VERSION ""

NS_ :

BS_:

BU_: Charger BMS

BO_ 2618644212 BMV: 512 BMS
 SG_ SingleBatteryGroup256 : 4092|4@1+ (1,0) [0|15] ""  Charger
 SG_ SingleBatteryVoltage256 : 4080|12@1+ (0.01,0) [0|24] "V"  Charger
 SG_ SingleBatteryGroup255 : 4076|4@1+ (1,0) [0|15] ""  Charger
 SG_ SingleBatteryVoltage255 : 4064|12@1+ (0.01,0) [0|24] "V"  Charger
 SG_ SingleBatteryGroup254 : 4060|4@1+ (1,0) [0|15] ""  Charger
 SG_ SingleBatteryVoltage254 : 4048|12@1+ (0.01,0) [0|24] "V"  Charger
 SG_ SingleBatteryGroup253 : 4044|4@1+ (1,0) [0|15] ""  Charger
 SG_ SingleBatteryVoltage253 : 4032|12@1+ (0.01,0) [0|24] "V"  Charger
 SG_ SingleBatteryGroup252 : 4028|4@1+ (1,0) [0|15] ""  Charger
 SG_ SingleBatteryVoltage252 : 4016|12@1+ (0.01,0) [0|24] "V"  Charger
 SG_ SingleBatteryGroup251 : 4012|4@1+ (1,0) [0|15] ""  Charger
 SG_ SingleBatteryVoltage251 : 4000|12@1+ (0.01,0) [0|24] "V"  Charger
 SG_ SingleBatteryGroup250 : 3996|4@1+ (1,0) [0|15] ""  Charger
 SG_ SingleBatteryVoltage250 : 3984|12@1+ (0.01,0) [0|24] "V"  Charger
 SG_ SingleBatteryGroup249 : 3980|4@1+ (1,0) [0|15] ""  Charger
 SG_ SingleBatteryVoltage249 : 3968|12@1+ (0.01,0) [0|24] "V"  Charger
 SG_ SingleBatteryGroup248 : 3964|4@1+ (1,0) [0|15] ""  Charger
 SG_ SingleBatteryVoltage248 : 3952|12@1+ (0.01,0) [0|24] "V"  Charger
 SG_ SingleBatteryGroup247 : 3948|4@1+ (1,0) [0|15] ""  Charger
 SG_ SingleBatteryVoltage247 : 3936|12@1+ (0.01,0) [0|24] "V"  Charger
 SG_ SingleBatteryGroup246 : 3932|4@1+ (1,0) [0|15] ""  Charger
 SG_ SingleBatteryVoltage246 : 3920|12@1+ (0.01,0) [0|24] "V"  Charger
 SG_ SingleBatteryGroup245 : 3916|4@1+ (1,0) [0|15] ""  Charger
 SG_ SingleBatteryVoltage245 : 3904|12@1+ (0.01,0) [0|24] "V"  Charger
 SG_ SingleBatteryGroup244 : 3900|4@1+ (1,0) [0|15] ""  Charger
 SG_ SingleBatteryVoltage244 : 3888|12@1+ (0.01,0) [0|24] "V"  Charger
 SG_ SingleBatteryGroup243 : 3884|4@1+ (1,0) [0|15] ""  Charger
 SG_ SingleBatteryVoltage243 : 3872|12@1+ (0.01,0) [0|24] "V"  Charger
 SG_ SingleBatteryGroup242 : 3868|4@1+ (1,0) [0|15] ""  Charger
 SG_ SingleBatteryVoltage242 : 3856|12@1+ (0.01,0) [0|24] "V"  Charger
 SG_ SingleBatteryGroup241 : 3852|4@1+ (1,0) [0|15] ""  Charger
 SG_ SingleBatteryVoltage241 : 3840|12@1+ (0.01,0) [0|24] "V"  Charger
 SG_ SingleBatteryGroup240 : 3836|4@1+ (1,0) [0|15] ""  Charger
 SG_ SingleBatteryVoltage240 : 3824|12@1+ (0.01,0) [0|24] "V"  Charger
 SG_ SingleBatteryGroup239 : 3820|4@1+ (1,0) [0|15] ""  Charger
 SG_ SingleBatteryVoltage239 : 3808|12@1+ (0.01,0) [0|24] "V"  Charger
 SG_ SingleBatteryGroup238 : 3804|4@1+ (1,0) [0|15] ""  Charger
 SG_ SingleBatteryVoltage238 : 3792|12@1+ (0.01,0) [0|24] "V"  Charger
 SG_ SingleBatteryGroup237 : 3788|4@1+ (1,0) [0|15] ""  Charger
 SG_ SingleBatteryVoltage237 : 3776|12@1+ (0.01,0) [0|24] "V"  Charger
 SG_ SingleBatteryGroup236 : 3772|4@1+ (1,0) [0|15] ""  Charger
 SG_ SingleBatteryVoltage236 : 3760|12@1+ (0.01,0) [0|24] "V"  Charger
 SG_ SingleBatteryGroup235 : 3756|4@1+ (1,0) [0|15] ""  Charger
 SG_ SingleBatteryVoltage235 : 3744|12@1+ (0.01,0) [0|24] "V"  Charger
 SG_ SingleBatteryGroup234 : 3740|4@1+ (1,0) [0|15] ""  Charger
 SG_ SingleBatteryVoltage234 : 3728|12@1+ (0.01,0) [0|24] "V"  Charger
 SG_ SingleBatteryGroup233 : 3724|4@1+ (1,0) [0|15] ""  Charger
 SG_ SingleBatteryVoltage233 : 3712|12@1+ (0.01,0) [0|24] "V"  Charger
 SG_ SingleBatteryGroup232 : 3708|4@1+ (1,0) [0|15] ""  Charger
 SG_ SingleBatteryVoltage232 : 3696|12@1+ (0.01,0) [0|24] "V"  Charger
 SG_ SingleBatteryGroup231 : 3692|4@1+ (1,0) [0|15] ""  Charger
 SG_ SingleBatteryVoltage231 : 3680|12@1+ (0.01,0) [0|24] "V"  Charger
 SG_ SingleBatteryGroup230 : 3676|4@1+ (1,0) [0|15] ""  Charger
 SG_ SingleBatteryVoltage230 : 3664|12@1+ (0.01,0) [0|24] "V"  Charger
 SG_ SingleBatteryGroup229 : 3660|4@1+ (1,0) [0|15] ""  Charger
 SG_ SingleBatteryVoltage229 : 3648|12@1+ (0.01,0) [0|24] "V"  Charger
 SG_ SingleBatteryGroup228 : 3644|4@1+ (1,0) [0|15] ""  Charger
 SG_ SingleBatteryVoltage228 : 3632|12@1+ (0.01,0) [0|24] "V"  Charger
 SG_ SingleBatteryGroup227 : 3628|4@1+ (1,0) [0|15] ""  Charger
 SG_ SingleBatteryVoltage227 : 3616|12@1+ (0.01,0) [0|24] "V"  Charger
 SG_ SingleBatteryGroup226 : 3612|4@1+ (1,0) [0|15] ""  Charger
 SG_ SingleBatteryVoltage226 : 3600|12@1+ (0.01,0) [0|24] "V"  Charger
 SG_ SingleBatteryGroup225 : 3596|4@1+ (1,0) [0|15] ""  Charger
 SG_ SingleBatteryVoltage225 : 3584|12@1+ (0.01,0) [0|24] "V"  Charger
 SG_ SingleBatteryGroup224 : 3580|4@1+ (1,0) [0|15] ""  Charger
 SG_ SingleBatteryVoltage224 : 3568|12@1+ (0.01,0) [0|24] "V"  Charger
 SG_ SingleBatteryGroup223 : 3564|4@1+ (1,0) [0|15] ""  Charger
 SG_ SingleBatteryVoltage223 : 3552|12@1+ (0.01,0) [0|24] "V"  Charger
 SG_ SingleBatteryGroup222 : 3548|4@1+ (1,0) [0|15] ""  Charger
 SG_ SingleBatteryVoltage222 : 3536|12@1+ (0.01,0) [0|24] "V"  Charger
 SG_ SingleBatteryGroup221 : 3532|4@1+ (1,0) [0|15] ""  Charger
 SG_ SingleBatteryVoltage221 : 3520|12@1+ (0.01,0) [0|24] "V"  Charger
 SG_ SingleBatteryGroup220 : 3516|4@1+ (1,0) [0|15] ""  Charger
 SG_ SingleBatteryVoltage220 : 3504|12@1+ (0.01,0) [0|24] "V"  Charger
 SG_ SingleBatteryGroup219 : 3500|4@1+ (1,0) [0|15] ""  Charger
 SG_ SingleBatteryVoltage219 : 3488|12@1+ (0.01,0) [0|24] "V"  Charger
 SG_ SingleBatteryGroup218 : 3484|4@1+ (1,0) [0|15] ""  Charger
 SG_ SingleBatteryVoltage218 : 3472|12@1+ (0.01,0) [0|24] "V"  Charger
 SG_ SingleBatteryGroup217 : 3468|4@1+ (1,0) [0|15] ""  Charger
 SG_ SingleBatteryVoltage217 : 3456|12@1+ (0.01,0) [0|24] "V"  Charger
 SG_ SingleBatteryGroup216 : 3452|4@1+ (1,0) [0|15] ""  Charger
 SG_ SingleBatteryVoltage216 : 3440|12@1+ (0.01,0) [0|24] "V"  Charger
 SG_ SingleBatteryGroup215 : 3436|4@1+ (1,0) [0|15] ""  Charger
 SG_ SingleBatteryVoltage215 : 3424|12@1+ (0.01,0) [0|24] "V"  Charger
 SG_ SingleBatteryGroup214 : 3420|4@1+ (1,0) [0|15] ""  Charger
 SG_ SingleBatteryVoltage214 : 3408|12@1+ (0.01,0) [0|24] "V"  Charger
 SG_ SingleBatteryGroup213 : 3404|4@1+ (1,0) [0|15] ""  Charger
 SG_ SingleBatteryVoltage213 : 3392|12@1+ (0.01,0) [0|24] "V"  Charger
 SG_ SingleBatteryGroup212 : 3388|4@1+ (1,0) [0|15] ""  Charger
 SG_ SingleBatteryVoltage212 : 3376|12@1+ (0.01,0) [0|24] "V"  Charger
 SG_ SingleBatteryGroup211 : 3372|4@1+ (1,0) [0|15] ""  Charger
 SG_ SingleBatteryVoltage211 : 3360|12@1+ (0.01,0) [0|24] "V"  Charger
 SG_ SingleBatteryGroup210 : 3356|4@1+ (1,0) [0|15] ""  Charger
 SG_ SingleBatteryVoltage210 : 3344|12@1+ (0.01,0) [0|24] "V"  Charger
 SG_ SingleBatteryGroup209 : 3340|4@1+ (1,0) [0|15] ""  Charger
 SG_ SingleBatteryVoltage209 : 3328|12@1+ (0.01,0) [0|24] "V"  Charger
 SG_ SingleBatteryGroup208 : 3324|4@1+ (1,0) [0|15] ""  Charger
 SG_ SingleBatteryVoltage208 : 3312|12@1+ (0.01,0) [0|24] "V"  Charger
 SG_ SingleBatteryGroup207 : 3308|4@1+ (1,0) [0|15] ""  Charger
 SG_ SingleBatteryVoltage207 : 3296|12@1+ (0.01,0) [0|24] "V"  Charger
 SG_ SingleBatteryGroup206 : 3292|4@1+ (1,0) [0|15] ""  Charger
 SG_ SingleBatteryVoltage206 : 3280|12@1+ (0.01,0) [0|24] "V"  Charger
 SG_ SingleBatteryGroup205 : 3276|4@1+ (1,0) [0|15] ""  Charger
 SG_ SingleBatteryVoltage205 : 3264|12@1+ (0.01,0) [0|24] "V"  Charger
 SG_ SingleBatteryGroup204 : 3260|4@1+ (1,0) [0|15] ""  Charger
 SG_ SingleBatteryVoltage204 : 3248|12@1+ (0.01,0) [0|24] "V"  Charger
 SG_ SingleBatteryGroup203 : 3244|4@1+ (1,0) [0|15] ""  Charger
 SG_ SingleBatteryVoltage203 : 3232|12@1+ (0.01,0) [0|24] "V"  Charger
 SG_ SingleBatteryGroup202 : 3228|4@1+ (1,0) [0|15] ""  Charger
 SG_ SingleBatteryVoltage202 : 3216|12@1+ (0.01,0) [0|24] "V"  Charger
 SG_ SingleBatteryGroup201 : 3212|4@1+ (1,0) [0|15] ""  Charger
 SG_ SingleBatteryVoltage201 : 3200|12@1+ (0.01,0) [0|24] "V"  Charger
 SG_ SingleBatteryGroup200 : 3196|4@1+ (1,0) [0|15] ""  Charger
 SG_ SingleBatteryVoltage200 : 3184|12@1+ (0.01,0) [0|24] "V"  Charger
 SG_ SingleBatteryGroup199 : 3180|4@1+ (1,0) [0|15] ""  Charger
 SG_ SingleBatteryVoltage199 : 3168|12@1+ (0.01,0) [0|24] "V"  Charger
 SG_ SingleBatteryGroup198 : 3164|4@1+ (1,0) [0|15] ""  Charger
 SG_ SingleBatteryVoltage198 : 3152|12@1+ (0.01,0) [0|24] "V"  Charger
 SG_ SingleBatteryGroup197 : 3148|4@1+ (1,0) [0|15] ""  Charger
 SG_ SingleBatteryVoltage197 : 3136|12@1+ (0.01,0) [0|24] "V"  Charger
 SG_ SingleBatteryGroup196 : 3132|4@1+ (1,0) [0|15] ""  Charger
 SG_ SingleBatteryVoltage196 : 3120|12@1+ (0.01,0) [0|24] "V"  Charger
 SG_ SingleBatteryGroup195 : 3116|4@1+ (1,0) [0|15] ""  Charger
 SG_ SingleBatteryVoltage195 : 3104|12@1+ (0.01,0) [0|24] "V"  Charger
 SG_ SingleBatteryGroup194 : 3100|4@1+ (1,0) [0|15] ""  Charger
 SG_ SingleBatteryVoltage194 : 3088|12@1+ (0.01,0) [0|24] "V"  Charger
 SG_ SingleBatteryGroup193 : 3084|4@1+ (1,0) [0|15] ""  Charger
 SG_ SingleBatteryVoltage193 : 3072|12@1+ (0.01,0) [0|24] "V"  Charger
 SG_ SingleBatteryGroup192 : 3068|4@1+ (1,0) [0|15] ""  Charger
 SG_ SingleBatteryVoltage192 : 3056|12@1+ (0.01,0) [0|24] "V"  Charger
 SG_ SingleBatteryGroup191 : 3052|4@1+ (1,0) [0|15] ""  Charger
 SG_ SingleBatteryVoltage191 : 3040|12@1+ (0.01,0) [0|24] "V"  Charger
 SG_ SingleBatteryGroup190 : 3036|4@1+ (1,0) [0|15] ""  Charger
 SG_ SingleBatteryVoltage190 : 3024|12@1+ (0.01,0) [0|24] "V"  Charger
 SG_ SingleBatteryGroup189 : 3020|4@1+ (1,0) [0|15] ""  Charger
 SG_ SingleBatteryVoltage189 : 3008|12@1+ (0.01,0) [0|24] "V"  Charger
 SG_ SingleBatteryGroup188 : 3004|4@1+ (1,0) [0|15] ""  Charger
 SG_ SingleBatteryVoltage188 : 2992|12@1+ (0.01,0) [0|24] "V"  Charger
 SG_ SingleBatteryGroup187 : 2988|4@1+ (1,0) [0|15] ""  Charger
 SG_ SingleBatteryVoltage187 : 2976|12@1+ (0.01,0) [0|24] "V"  Charger
 SG_ SingleBatteryGroup186 : 2972|4@1+ (1,0) [0|15] ""  Charger
 SG_ SingleBatteryVoltage186 : 2960|12@1+ (0.01,0) [0|24] "V"  Charger
 SG_ SingleBatteryGroup185 : 2956|4@1+ (1,0) [0|15] ""  Charger
 SG_ SingleBatteryVoltage185 : 2944|12@1+ (0.01,0) [0|24] "V"  Charger
 SG_ SingleBatteryGroup184 : 2940|4@1+ (1,0) [0|15] ""  Charger
 SG_ SingleBatteryVoltage184 : 2928|12@1+ (0.01,0) [0|24] "V"  Charger
 SG_ SingleBatteryGroup183 : 2924|4@1+ (1,0) [0|15] ""  Charger
 SG_ SingleBatteryVoltage183 : 2912|12@1+ (0.01,0) [0|24] "V"  Charger
 SG_ SingleBatteryGroup182 : 2908|4@1+ (1,0) [0|15] ""  Charger
 SG_ SingleBatteryVoltage182 : 2896|12@1+ (0.01,0) [0|24] "V"  Charger
 SG_ SingleBatteryGroup181 : 2892|4@1+ (1,0) [0|15] ""  Charger
 SG_ SingleBatteryVoltage181 : 2880|12@1+ (0.01,0) [0|24] "V"  Charger
 SG_ SingleBatteryGroup180 : 2876|4@1+ (1,0) [0|15] ""  Charger
 SG_ SingleBatteryVoltage180 : 2864|12@1+ (0.01,0) [0|24] "V"  Charger
 SG_ SingleBatteryGroup179 : 2860|4@1+ (1,0) [0|15] ""  Charger
 SG_ SingleBatteryVoltage179 : 2848|12@1+ (0.01,0) [0|24] "V"  Charger
 SG_ SingleBatteryGroup178 : 2844|4@1+ (1,0) [0|15] ""  Charger
 SG_ SingleBatteryVoltage178 : 2832|12@1+ (0.01,0) [0|24] "V"  Charger
 SG_ SingleBatteryGroup177 : 2828|4@1+ (1,0) [0|15] ""  Charger
 SG_ SingleBatteryVoltage177 : 2816|12@1+ (0.01,0) [0|24] "V"  Charger
 SG_ SingleBatteryGroup176 : 2812|4@1+ (1,0) [0|15] ""  Charger
 SG_ SingleBatteryVoltage176 : 2800|12@1+ (0.01,0) [0|24] "V"  Charger
 SG_ SingleBatteryGroup175 : 2796|4@1+ (1,0) [0|15] ""  Charger
 SG_ SingleBatteryVoltage175 : 2784|12@1+ (0.01,0) [0|24] "V"  Charger
 SG_ SingleBatteryGroup174 : 2780|4@1+ (1,0) [0|15] ""  Charger
 SG_ SingleBatteryVoltage174 : 2768|12@1+ (0.01,0) [0|24] "V"  Charger
 SG_ SingleBatteryGroup173 : 2764|4@1+ (1,0) [0|15] ""  Charger
 SG_ SingleBatteryVoltage173 : 2752|12@1+ (0.01,0) [0|24] "V"  Charger
 SG_ SingleBatteryGroup172 : 2748|4@1+ (1,0) [0|15] ""  Charger
 SG_ SingleBatteryVoltage172 : 2736|12@1+ (0.01,0) [0|24] "V"  Charger
 SG_ SingleBatteryGroup171 : 2732|4@1+ (1,0) [0|15] ""  Charger
 SG_ SingleBatteryVoltage171 : 2720|12@1+ (0.01,0) [0|24] "V"  Charger
 SG_ SingleBatteryGroup170 : 2716|4@1+ (1,0) [0|15] ""  Charger
 SG_ SingleBatteryVoltage170 : 2704|12@1+ (0.01,0) [0|24] "V"  Charger
 SG_ SingleBatteryGroup169 : 2700|4@1+ (1,0) [0|15] ""  Charger
 SG_ SingleBatteryVoltage169 : 2688|12@1+ (0.01,0) [0|24] "V"  Charger
 SG_ SingleBatteryGroup168 : 2684|4@1+ (1,0) [0|15] ""  Charger
 SG_ SingleBatteryVoltage168 : 2672|12@1+ (0.01,0) [0|24] "V"  Charger
 SG_ SingleBatteryGroup167 : 2668|4@1+ (1,0) [0|15] ""  Charger
 SG_ SingleBatteryVoltage167 : 2656|12@1+ (0.01,0) [0|24] "V"  Charger
 SG_ SingleBatteryGroup166 : 2652|4@1+ (1,0) [0|15] ""  Charger
 SG_ SingleBatteryVoltage166 : 2640|12@1+ (0.01,0) [0|24] "V"  Charger
 SG_ SingleBatteryGroup165 : 2636|4@1+ (1,0) [0|15] ""  Charger
 SG_ SingleBatteryVoltage165 : 2624|12@1+ (0.01,0) [0|24] "V"  Charger
 SG_ SingleBatteryGroup164 : 2620|4@1+ (1,0) [0|15] ""  Charger
 SG_ SingleBatteryVoltage164 : 2608|12@1+ (0.01,0) [0|24] "V"  Charger
 SG_ SingleBatteryGroup163 : 2604|4@1+ (1,0) [0|15] ""  Charger
 SG_ SingleBatteryVoltage163 : 2592|12@1+ (0.01,0) [0|24] "V"  Charger
 SG_ SingleBatteryGroup162 : 2588|4@1+ (1,0) [0|15] ""  Charger
 SG_ SingleBatteryVoltage162 : 2576|12@1+ (0.01,0) [0|24] "V"  Charger
 SG_ SingleBatteryGroup161 : 2572|4@1+ (1,0) [0|15] ""  Charger
 SG_ SingleBatteryVoltage161 : 2560|12@1+ (0.01,0) [0|24] "V"  Charger
 SG_ SingleBatteryGroup160 : 2556|4@1+ (1,0) [0|15] ""  Charger
 SG_ SingleBatteryVoltage160 : 2544|12@1+ (0.01,0) [0|24] "V"  Charger
 SG_ SingleBatteryGroup159 : 2540|4@1+ (1,0) [0|15] ""  Charger
 SG_ SingleBatteryVoltage159 : 2528|12@1+ (0.01,0) [0|24] "V"  Charger
 SG_ SingleBatteryGroup158 : 2524|4@1+ (1,0) [0|15] ""  Charger
 SG_ SingleBatteryVoltage158 : 2512|12@1+ (0.01,0) [0|24] "V"  Charger
 SG_ SingleBatteryGroup157 : 2508|4@1+ (1,0) [0|15] ""  Charger
 SG_ SingleBatteryVoltage157 : 2496|12@1+ (0.01,0) [0|24] "V"  Charger
 SG_ SingleBatteryGroup156 : 2492|4@1+ (1,0) [0|15] ""  Charger
 SG_ SingleBatteryVoltage156 : 2480|12@1+ (0.01,0) [0|24] "V"  Charger
 SG_ SingleBatteryGroup155 : 2476|4@1+ (1,0) [0|15] ""  Charger
 SG_ SingleBatteryVoltage155 : 2464|12@1+ (0.01,0) [0|24] "V"  Charger
 SG_ SingleBatteryGroup154 : 2460|4@1+ (1,0) [0|15] ""  Charger
 SG_ SingleBatteryVoltage154 : 2448|12@1+ (0.01,0) [0|24] "V"  Charger
 SG_ SingleBatteryGroup153 : 2444|4@1+ (1,0) [0|15] ""  Charger
 SG_ SingleBatteryVoltage153 : 2432|12@1+ (0.01,0) [0|24] "V"  Charger
 SG_ SingleBatteryGroup152 : 2428|4@1+ (1,0) [0|15] ""  Charger
 SG_ SingleBatteryVoltage152 : 2416|12@1+ (0.01,0) [0|24] "V"  Charger
 SG_ SingleBatteryGroup151 : 2412|4@1+ (1,0) [0|15] ""  Charger
 SG_ SingleBatteryVoltage151 : 2400|12@1+ (0.01,0) [0|24] "V"  Charger
 SG_ SingleBatteryGroup150 : 2396|4@1+ (1,0) [0|15] ""  Charger
 SG_ SingleBatteryVoltage150 : 2384|12@1+ (0.01,0) [0|24] "V"  Charger
 SG_ SingleBatteryGroup149 : 2380|4@1+ (1,0) [0|15] ""  Charger
 SG_ SingleBatteryVoltage149 : 2368|12@1+ (0.01,0) [0|24] "V"  Charger
 SG_ SingleBatteryGroup148 : 2364|4@1+ (1,0) [0|15] ""  Charger
 SG_ SingleBatteryVoltage148 : 2352|12@1+ (0.01,0) [0|24] "V"  Charger
 SG_ SingleBatteryGroup147 : 2348|4@1+ (1,0) [0|15] ""  Charger
 SG_ SingleBatteryVoltage147 : 2336|12@1+ (0.01,0) [0|24] "V"  Charger
 SG_ SingleBatteryGroup146 : 2332|4@1+ (1,0) [0|15] ""  Charger
 SG_ SingleBatteryVoltage146 : 2320|12@1+ (0.01,0) [0|24] "V"  Charger
 SG_ SingleBatteryGroup145 : 2316|4@1+ (1,0) [0|15] ""  Charger
 SG_ SingleBatteryVoltage145 : 2304|12@1+ (0.01,0) [0|24] "V"  Charger
 SG_ SingleBatteryGroup144 : 2300|4@1+ (1,0) [0|15] ""  Charger
 SG_ SingleBatteryVoltage144 : 2288|12@1+ (0.01,0) [0|24] "V"  Charger
 SG_ SingleBatteryGroup143 : 2284|4@1+ (1,0) [0|15] ""  Charger
 SG_ SingleBatteryVoltage143 : 2272|12@1+ (0.01,0) [0|24] "V"  Charger
 SG_ SingleBatteryGroup142 : 2268|4@1+ (1,0) [0|15] ""  Charger
 SG_ SingleBatteryVoltage142 : 2256|12@1+ (0.01,0) [0|24] "V"  Charger
 SG_ SingleBatteryGroup141 : 2252|4@1+ (1,0) [0|15] ""  Charger
 SG_ SingleBatteryVoltage141 : 2240|12@1+ (0.01,0) [0|24] "V"  Charger
 SG_ SingleBatteryGroup140 : 2236|4@1+ (1,0) [0|15] ""  Charger
 SG_ SingleBatteryVoltage140 : 2224|12@1+ (0.01,0) [0|24] "V"  Charger
 SG_ SingleBatteryGroup139 : 2220|4@1+ (1,0) [0|15] ""  Charger
 SG_ SingleBatteryVoltage139 : 2208|12@1+ (0.01,0) [0|24] "V"  Charger
 SG_ SingleBatteryGroup138 : 2204|4@1+ (1,0) [0|15] ""  Charger
 SG_ SingleBatteryVoltage138 : 2192|12@1+ (0.01,0) [0|24] "V"  Charger
 SG_ SingleBatteryGroup137 : 2188|4@1+ (1,0) [0|15] ""  Charger
 SG_ SingleBatteryVoltage137 : 2176|12@1+ (0.01,0) [0|24] "V"  Charger
 SG_ SingleBatteryGroup136 : 2172|4@1+ (1,0) [0|15] ""  Charger
 SG_ SingleBatteryVoltage136 : 2160|12@1+ (0.01,0) [0|24] "V"  Charger
 SG_ SingleBatteryGroup135 : 2156|4@1+ (1,0) [0|15] ""  Charger
 SG_ SingleBatteryVoltage135 : 2144|12@1+ (0.01,0) [0|24] "V"  Charger
 SG_ SingleBatteryGroup134 : 2140|4@1+ (1,0) [0|15] ""  Charger
 SG_ SingleBatteryVoltage134 : 2128|12@1+ (0.01,0) [0|24] "V"  Charger
 SG_ SingleBatteryGroup133 : 2124|4@1+ (1,0) [0|15] ""  Charger
 SG_ SingleBatteryVoltage133 : 2112|12@1+ (0.01,0) [0|24] "V"  Charger
 SG_ SingleBatteryGroup132 : 2108|4@1+ (1,0) [0|15] ""  Charger
 SG_ SingleBatteryVoltage132 : 2096|12@1+ (0.01,0) [0|24] "V"  Charger
 SG_ SingleBatteryGroup131 : 2092|4@1+ (1,0) [0|15] ""  Charger
 SG_ SingleBatteryVoltage131 : 2080|12@1+ (0.01,0) [0|24] "V"  Charger
 SG_ SingleBatteryGroup130 : 2076|4@1+ (1,0) [0|15] ""  Charger
 SG_ SingleBatteryVoltage130 : 2064|12@1+ (0.01,0) [0|24] "V"  Charger
 SG_ SingleBatteryGroup129 : 2060|4@1+ (1,0) [0|15] ""  Charger
 SG_ SingleBatteryVoltage129 : 2048|12@1+ (0.01,0) [0|24] "V"  Charger
 SG_ SingleBatteryGroup128 : 2044|4@1+ (1,0) [0|15] ""  Charger
 SG_ SingleBatteryVoltage128 : 2032|12@1+ (0.01,0) [0|24] "V"  Charger
 SG_ SingleBatteryGroup127 : 2028|4@1+ (1,0) [0|15] ""  Charger
 SG_ SingleBatteryVoltage127 : 2016|12@1+ (0.01,0) [0|24] "V"  Charger
 SG_ SingleBatteryGroup126 : 2012|4@1+ (1,0) [0|15] ""  Charger
 SG_ SingleBatteryVoltage126 : 2000|12@1+ (0.01,0) [0|24] "V"  Charger
 SG_ SingleBatteryGroup125 : 1996|4@1+ (1,0) [0|15] ""  Charger
 SG_ SingleBatteryVoltage125 : 1984|12@1+ (0.01,0) [0|24] "V"  Charger
 SG_ SingleBatteryGroup124 : 1980|4@1+ (1,0) [0|15] ""  Charger
 SG_ SingleBatteryVoltage124 : 1968|12@1+ (0.01,0) [0|24] "V"  Charger
 SG_ SingleBatteryGroup123 : 1964|4@1+ (1,0) [0|15] ""  Charger
 SG_ SingleBatteryVoltage123 : 1952|12@1+ (0.01,0) [0|24] "V"  Charger
 SG_ SingleBatteryGroup122 : 1948|4@1+ (1,0) [0|15] ""  Charger
 SG_ SingleBatteryVoltage122 : 1936|12@1+ (0.01,0) [0|24] "V"  Charger
 SG_ SingleBatteryGroup121 : 1932|4@1+ (1,0) [0|15] ""  Charger
 SG_ SingleBatteryVoltage121 : 1920|12@1+ (0.01,0) [0|24] "V"  Charger
 SG_ SingleBatteryGroup120 : 1916|4@1+ (1,0) [0|15] ""  Charger
 SG_ SingleBatteryVoltage120 : 1904|12@1+ (0.01,0) [0|24] "V"  Charger
 SG_ SingleBatteryGroup119 : 1900|4@1+ (1,0) [0|15] ""  Charger
 SG_ SingleBatteryVoltage119 : 1888|12@1+ (0.01,0) [0|24] "V"  Charger
 SG_ SingleBatteryGroup118 : 1884|4@1+ (1,0) [0|15] ""  Charger
 SG_ SingleBatteryVoltage118 : 1872|12@1+ (0.01,0) [0|24] "V"  Charger
 SG_ SingleBatteryGroup117 : 1868|4@1+ (1,0) [0|15] ""  Charger
 SG_ SingleBatteryVoltage117 : 1856|12@1+ (0.01,0) [0|24] "V"  Charger
 SG_ SingleBatteryGroup116 : 1852|4@1+ (1,0) [0|15] ""  Charger
 SG_ SingleBatteryVoltage116 : 1840|12@1+ (0.01,0) [0|24] "V"  Charger
 SG_ SingleBatteryGroup115 : 1836|4@1+ (1,0) [0|15] ""  Charger
 SG_ SingleBatteryVoltage115 : 1824|12@1+ (0.01,0) [0|24] "V"  Charger
 SG_ SingleBatteryGroup114 : 1820|4@1+ (1,0) [0|15] ""  Charger
 SG_ SingleBatteryVoltage114 : 1808|12@1+ (0.01,0) [0|24] "V"  Charger
 SG_ SingleBatteryGroup113 : 1804|4@1+ (1,0) [0|15] ""  Charger
 SG_ SingleBatteryVoltage113 : 1792|12@1+ (0.01,0) [0|24] "V"  Charger
 SG_ SingleBatteryGroup112 : 1788|4@1+ (1,0) [0|15] ""  Charger
 SG_ SingleBatteryVoltage112 : 1776|12@1+ (0.01,0) [0|24] "V"  Charger
 SG_ SingleBatteryGroup111 : 1772|4@1+ (1,0) [0|15] ""  Charger
 SG_ SingleBatteryVoltage111 : 1760|12@1+ (0.01,0) [0|24] "V"  Charger
 SG_ SingleBatteryGroup110 : 1756|4@1+ (1,0) [0|15] ""  Charger
 SG_ SingleBatteryVoltage110 : 1744|12@1+ (0.01,0) [0|24] "V"  Charger
 SG_ SingleBatteryGroup109 : 1740|4@1+ (1,0) [0|15] ""  Charger
 SG_ SingleBatteryVoltage109 : 1728|12@1+ (0.01,0) [0|24] "V"  Charger
 SG_ SingleBatteryGroup108 : 1724|4@1+ (1,0) [0|15] ""  Charger
 SG_ SingleBatteryVoltage108 : 1712|12@1+ (0.01,0) [0|24] "V"  Charger
 SG_ SingleBatteryGroup107 : 1708|4@1+ (1,0) [0|15] ""  Charger
 SG_ SingleBatteryVoltage107 : 1696|12@1+ (0.01,0) [0|24] "V"  Charger
 SG_ SingleBatteryGroup106 : 1692|4@1+ (1,0) [0|15] ""  Charger
 SG_ SingleBatteryVoltage106 : 1680|12@1+ (0.01,0) [0|24] "V"  Charger
 SG_ SingleBatteryGroup105 : 1676|4@1+ (1,0) [0|15] ""  Charger
 SG_ SingleBatteryVoltage105 : 1664|12@1+ (0.01,0) [0|24] "V"  Charger
 SG_ SingleBatteryGroup104 : 1660|4@1+ (1,0) [0|15] ""  Charger
 SG_ SingleBatteryVoltage104 : 1648|12@1+ (0.01,0) [0|24] "V"  Charger
 SG_ SingleBatteryGroup103 : 1644|4@1+ (1,0) [0|15] ""  Charger
 SG_ SingleBatteryVoltage103 : 1632|12@1+ (0.01,0) [0|24] "V"  Charger
 SG_ SingleBatteryGroup102 : 1628|4@1+ (1,0) [0|15] ""  Charger
 SG_ SingleBatteryVoltage102 : 1616|12@1+ (0.01,0) [0|24] "V"  Charger
 SG_ SingleBatteryGroup101 : 1612|4@1+ (1,0) [0|15] ""  Charger
 SG_ SingleBatteryVoltage101 : 1600|12@1+ (0.01,0) [0|24] "V"  Charger
 SG_ SingleBatteryGroup100 : 1596|4@1+ (1,0) [0|15] ""  Charger
 SG_ SingleBatteryVoltage100 : 1584|12@1+ (0.01,0) [0|24] "V"  Charger
 SG_ SingleBatteryGroup099 : 1580|4@1+ (1,0) [0|15] ""  Charger
 SG_ SingleBatteryVoltage099 : 1568|12@1+ (0.01,0) [0|24] "V"  Charger
 SG_ SingleBatteryGroup098 : 1564|4@1+ (1,0) [0|15] ""  Charger
 SG_ SingleBatteryVoltage098 : 1552|12@1+ (0.01,0) [0|24] "V"  Charger
 SG_ SingleBatteryGroup097 : 1548|4@1+ (1,0) [0|15] ""  Charger
 SG_ SingleBatteryVoltage097 : 1536|12@1+ (0.01,0) [0|24] "V"  Charger
 SG_ SingleBatteryGroup096 : 1532|4@1+ (1,0) [0|15] ""  Charger
 SG_ SingleBatteryVoltage096 : 1520|12@1+ (0.01,0) [0|24] "V"  Charger
 SG_ SingleBatteryGroup095 : 1516|4@1+ (1,0) [0|15] ""  Charger
 SG_ SingleBatteryVoltage095 : 1504|12@1+ (0.01,0) [0|24] "V"  Charger
 SG_ SingleBatteryGroup094 : 1500|4@1+ (1,0) [0|15] ""  Charger
 SG_ SingleBatteryVoltage094 : 1488|12@1+ (0.01,0) [0|24] "V"  Charger
 SG_ SingleBatteryGroup093 : 1484|4@1+ (1,0) [0|15] ""  Charger
 SG_ SingleBatteryVoltage093 : 1472|12@1+ (0.01,0) [0|24] "V"  Charger
 SG_ SingleBatteryGroup092 : 1468|4@1+ (1,0) [0|15] ""  Charger
 SG_ SingleBatteryVoltage092 : 1456|12@1+ (0.01,0) [0|24] "V"  Charger
 SG_ SingleBatteryGroup091 : 1452|4@1+ (1,0) [0|15] ""  Charger
 SG_ SingleBatteryVoltage091 : 1440|12@1+ (0.01,0) [0|24] "V"  Charger
 SG_ SingleBatteryGroup090 : 1436|4@1+ (1,0) [0|15] ""  Charger
 SG_ SingleBatteryVoltage090 : 1424|12@1+ (0.01,0) [0|24] "V"  Charger
 SG_ SingleBatteryGroup089 : 1420|4@1+ (1,0) [0|15] ""  Charger
 SG_ SingleBatteryVoltage089 : 1408|12@1+ (0.01,0) [0|24] "V"  Charger
 SG_ SingleBatteryGroup088 : 1404|4@1+ (1,0) [0|15] ""  Charger
 SG_ SingleBatteryVoltage088 : 1392|12@1+ (0.01,0) [0|24] "V"  Charger
 SG_ SingleBatteryGroup087 : 1388|4@1+ (1,0) [0|15] ""  Charger
 SG_ SingleBatteryVoltage087 : 1376|12@1+ (0.01,0) [0|24] "V"  Charger
 SG_ SingleBatteryGroup086 : 1372|4@1+ (1,0) [0|15] ""  Charger
 SG_ SingleBatteryVoltage086 : 1360|12@1+ (0.01,0) [0|24] "V"  Charger
 SG_ SingleBatteryGroup085 : 1356|4@1+ (1,0) [0|15] ""  Charger
 SG_ SingleBatteryVoltage085 : 1344|12@1+ (0.01,0) [0|24] "V"  Charger
 SG_ SingleBatteryGroup084 : 1340|4@1+ (1,0) [0|15] ""  Charger
 SG_ SingleBatteryVoltage084 : 1328|12@1+ (0.01,0) [0|24] "V"  Charger
 SG_ SingleBatteryGroup083 : 1324|4@1+ (1,0) [0|15] ""  Charger
 SG_ SingleBatteryVoltage083 : 1312|12@1+ (0.01,0) [0|24] "V"  Charger
 SG_ SingleBatteryGroup082 : 1308|4@1+ (1,0) [0|15] ""  Charger
 SG_ SingleBatteryVoltage082 : 1296|12@1+ (0.01,0) [0|24] "V"  Charger
 SG_ SingleBatteryGroup081 : 1292|4@1+ (1,0) [0|15] ""  Charger
 SG_ SingleBatteryVoltage081 : 1280|12@1+ (0.01,0) [0|24] "V"  Charger
 SG_ SingleBatteryGroup080 : 1276|4@1+ (1,0) [0|15] ""  Charger
 SG_ SingleBatteryVoltage080 : 1264|12@1+ (0.01,0) [0|24] "V"  Charger
 SG_ SingleBatteryGroup079 : 1260|4@1+ (1,0) [0|15] ""  Charger
 SG_ SingleBatteryVoltage079 : 1248|12@1+ (0.01,0) [0|24] "V"  Charger
 SG_ SingleBatteryGroup078 : 1244|4@1+ (1,0) [0|15] ""  Charger
 SG_ SingleBatteryVoltage078 : 1232|12@1+ (0.01,0) [0|24] "V"  Charger
 SG_ SingleBatteryGroup077 : 1228|4@1+ (1,0) [0|15] ""  Charger
 SG_ SingleBatteryVoltage077 : 1216|12@1+ (0.01,0) [0|24] "V"  Charger
 SG_ SingleBatteryGroup076 : 1212|4@1+ (1,0) [0|15] ""  Charger
 SG_ SingleBatteryVoltage076 : 1200|12@1+ (0.01,0) [0|24] "V"  Charger
 SG_ SingleBatteryGroup075 : 1196|4@1+ (1,0) [0|15] ""  Charger
 SG_ SingleBatteryVoltage075 : 1184|12@1+ (0.01,0) [0|24] "V"  Charger
 SG_ SingleBatteryGroup074 : 1180|4@1+ (1,0) [0|15] ""  Charger
 SG_ SingleBatteryVoltage074 : 1168|12@1+ (0.01,0) [0|24] "V"  Charger
 SG_ SingleBatteryGroup073 : 1164|4@1+ (1,0) [0|15] ""  Charger
 SG_ SingleBatteryVoltage073 : 1152|12@1+ (0.01,0) [0|24] "V"  Charger
 SG_ SingleBatteryGroup072 : 1148|4@1+ (1,0) [0|15] ""  Charger
 SG_ SingleBatteryVoltage072 : 1136|12@1+ (0.01,0) [0|24] "V"  Charger
 SG_ SingleBatteryGroup071 : 1132|4@1+ (1,0) [0|15] ""  Charger
 SG_ SingleBatteryVoltage071 : 1120|12@1+ (0.01,0) [0|24] "V"  Charger
 SG_ SingleBatteryGroup070 : 1116|4@1+ (1,0) [0|15] ""  Charger
 SG_ SingleBatteryVoltage070 : 1104|12@1+ (0.01,0) [0|24] "V"  Charger
 SG_ SingleBatteryGroup069 : 1100|4@1+ (1,0) [0|15] ""  Charger
 SG_ SingleBatteryVoltage069 : 1088|12@1+ (0.01,0) [0|24] "V"  Charger
 SG_ SingleBatteryGroup068 : 1084|4@1+ (1,0) [0|15] ""  Charger
 SG_ SingleBatteryVoltage068 : 1072|12@1+ (0.01,0) [0|24] "V"  Charger
 SG_ SingleBatteryGroup067 : 1068|4@1+ (1,0) [0|15] ""  Charger
 SG_ SingleBatteryVoltage067 : 1056|12@1+ (0.01,0) [0|24] "V"  Charger
 SG_ SingleBatteryGroup066 : 1052|4@1+ (1,0) [0|15] ""  Charger
 SG_ SingleBatteryVoltage066 : 1040|12@1+ (0.01,0) [0|24] "V"  Charger
 SG_ SingleBatteryGroup065 : 1036|4@1+ (1,0) [0|15] ""  Charger
 SG_ SingleBatteryVoltage065 : 1024|12@1+ (0.01,0) [0|24] "V"  Charger
 SG_ SingleBatteryGroup064 : 1020|4@1+ (1,0) [0|15] ""  Charger
 SG_ SingleBatteryVoltage064 : 1008|12@1+ (0.01,0) [0|24] "V"  Charger
 SG_ SingleBatteryGroup063 : 1004|4@1+ (1,0) [0|15] ""  Charger
 SG_ SingleBatteryVoltage063 : 992|12@1+ (0.01,0) [0|24] "V"  Charger
 SG_ SingleBatteryGroup062 : 988|4@1+ (1,0) [0|15] ""  Charger
 SG_ SingleBatteryVoltage062 : 976|12@1+ (0.01,0) [0|24] "V"  Charger
 SG_ SingleBatteryGroup061 : 972|4@1+ (1,0) [0|15] ""  Charger
 SG_ SingleBatteryVoltage061 : 960|12@1+ (0.01,0) [0|24] "V"  Charger
 SG_ SingleBatteryGroup060 : 956|4@1+ (1,0) [0|15] ""  Charger
 SG_ SingleBatteryVoltage060 : 944|12@1+ (0.01,0) [0|24] "V"  Charger
 SG_ SingleBatteryGroup059 : 940|4@1+ (1,0) [0|15] ""  Charger
 SG_ SingleBatteryVoltage059 : 928|12@1+ (0.01,0) [0|24] "V"  Charger
 SG_ SingleBatteryGroup058 : 924|4@1+ (1,0) [0|15] ""  Charger
 SG_ SingleBatteryVoltage058 : 912|12@1+ (0.01,0) [0|24] "V"  Charger
 SG_ SingleBatteryGroup057 : 908|4@1+ (1,0) [0|15] ""  Charger
 SG_ SingleBatteryVoltage057 : 896|12@1+ (0.01,0) [0|24] "V"  Charger
 SG_ SingleBatteryGroup056 : 892|4@1+ (1,0) [0|15] ""  Charger
 SG_ SingleBatteryVoltage056 : 880|12@1+ (0.01,0) [0|24] "V"  Charger
 SG_ SingleBatteryGroup055 : 876|4@1+ (1,0) [0|15] ""  Charger
 SG_ SingleBatteryVoltage055 : 864|12@1+ (0.01,0) [0|24] "V"  Charger
 SG_ SingleBatteryGroup054 : 860|4@1+ (1,0) [0|15] ""  Charger
 SG_ SingleBatteryVoltage054 : 848|12@1+ (0.01,0) [0|24] "V"  Charger
 SG_ SingleBatteryGroup053 : 844|4@1+ (1,0) [0|15] ""  Charger
 SG_ SingleBatteryVoltage053 : 832|12@1+ (0.01,0) [0|24] "V"  Charger
 SG_ SingleBatteryGroup052 : 828|4@1+ (1,0) [0|15] ""  Charger
 SG_ SingleBatteryVoltage052 : 816|12@1+ (0.01,0) [0|24] "V"  Charger
 SG_ SingleBatteryGroup051 : 812|4@1+ (1,0) [0|15] ""  Charger
 SG_ SingleBatteryVoltage051 : 800|12@1+ (0.01,0) [0|24] "V"  Charger
 SG_ SingleBatteryGroup050 : 796|4@1+ (1,0) [0|15] ""  Charger
 SG_ SingleBatteryVoltage050 : 784|12@1+ (0.01,0) [0|24] "V"  Charger
 SG_ SingleBatteryGroup049 : 780|4@1+ (1,0) [0|15] ""  Charger
 SG_ SingleBatteryVoltage049 : 768|12@1+ (0.01,0) [0|24] "V"  Charger
 SG_ SingleBatteryGroup048 : 764|4@1+ (1,0) [0|15] ""  Charger
 SG_ SingleBatteryVoltage048 : 752|12@1+ (0.01,0) [0|24] "V"  Charger
 SG_ SingleBatteryGroup047 : 748|4@1+ (1,0) [0|15] ""  Charger
 SG_ SingleBatteryVoltage047 : 736|12@1+ (0.01,0) [0|24] "V"  Charger
 SG_ SingleBatteryGroup046 : 732|4@1+ (1,0) [0|15] ""  Charger
 SG_ SingleBatteryVoltage046 : 720|12@1+ (0.01,0) [0|24] "V"  Charger
 SG_ SingleBatteryGroup045 : 716|4@1+ (1,0) [0|15] ""  Charger
 SG_ SingleBatteryVoltage045 : 704|12@1+ (0.01,0) [0|24] "V"  Charger
 SG_ SingleBatteryGroup044 : 700|4@1+ (1,0) [0|15] ""  Charger
 SG_ SingleBatteryVoltage044 : 688|12@1+ (0.01,0) [0|24] "V"  Charger
 SG_ SingleBatteryGroup043 : 684|4@1+ (1,0) [0|15] ""  Charger
 SG_ SingleBatteryVoltage043 : 672|12@1+ (0.01,0) [0|24] "V"  Charger
 SG_ SingleBatteryGroup042 : 668|4@1+ (1,0) [0|15] ""  Charger
 SG_ SingleBatteryVoltage042 : 656|12@1+ (0.01,0) [0|24] "V"  Charger
 SG_ SingleBatteryGroup041 : 652|4@1+ (1,0) [0|15] ""  Charger
 SG_ SingleBatteryVoltage041 : 640|12@1+ (0.01,0) [0|24] "V"  Charger
 SG_ SingleBatteryGroup040 : 636|4@1+ (1,0) [0|15] ""  Charger
 SG_ SingleBatteryVoltage040 : 624|12@1+ (0.01,0) [0|24] "V"  Charger
 SG_ SingleBatteryGroup039 : 620|4@1+ (1,0) [0|15] ""  Charger
 SG_ SingleBatteryVoltage039 : 608|12@1+ (0.01,0) [0|24] "V"  Charger
 SG_ SingleBatteryGroup038 : 604|4@1+ (1,0) [0|15] ""  Charger
 SG_ SingleBatteryVoltage038 : 592|12@1+ (0.01,0) [0|24] "V"  Charger
 SG_ SingleBatteryGroup037 : 588|4@1+ (1,0) [0|15] ""  Charger
 SG_ SingleBatteryVoltage037 : 576|12@1+ (0.01,0) [0|24] "V"  Charger
 SG_ SingleBatteryGroup036 : 572|4@1+ (1,0) [0|15] ""  Charger
 SG_ SingleBatteryVoltage036 : 560|12@1+ (0.01,0) [0|24] "V"  Charger
 SG_ SingleBatteryGroup035 : 556|4@1+ (1,0) [0|15] ""  Charger
 SG_ SingleBatteryVoltage035 : 544|12@1+ (0.01,0) [0|24] "V"  Charger
 SG_ SingleBatteryGroup034 : 540|4@1+ (1,0) [0|15] ""  Charger
 SG_ SingleBatteryVoltage034 : 528|12@1+ (0.01,0) [0|24] "V"  Charger
 SG_ SingleBatteryGroup033 : 524|4@1+ (1,0) [0|15] ""  Charger
 SG_ SingleBatteryVoltage033 : 512|12@1+ (0.01,0) [0|24] "V"  Charger
 SG_ SingleBatteryGroup032 : 508|4@1+ (1,0) [0|15] ""  Charger
 SG_ SingleBatteryVoltage032 : 496|12@1+ (0.01,0) [0|24] "V"  Charger
 SG_ SingleBatteryGroup031 : 492|4@1+ (1,0) [0|15] ""  Charger
 SG_ SingleBatteryVoltage031 : 480|12@1+ (0.01,0) [0|24] "V"  Charger
 SG_ SingleBatteryGroup030 : 476|4@1+ (1,0) [0|15] ""  Charger
 SG_ SingleBatteryVoltage030 : 464|12@1+ (0.01,0) [0|24] "V"  Charger
 SG_ SingleBatteryGroup029 : 460|4@1+ (1,0) [0|15] ""  Charger
 SG_ SingleBatteryVoltage029 : 448|12@1+ (0.01,0) [0|24] "V"  Charger
 SG_ SingleBatteryGroup028 : 444|4@1+ (1,0) [0|15] ""  Charger
 SG_ SingleBatteryVoltage028 : 432|12@1+ (0.01,0) [0|24] "V"  Charger
 SG_ SingleBatteryGroup027 : 428|4@1+ (1,0) [0|15] ""  Charger
 SG_ SingleBatteryVoltage027 : 416|12@1+ (0.01,0) [0|24] "V"  Charger
 SG_ SingleBatteryGroup026 : 412|4@1+ (1,0) [0|15] ""  Charger
 SG_ SingleBatteryVoltage026 : 400|12@1+ (0.01,0) [0|24] "V"  Charger
 SG_ SingleBatteryGroup025 : 396|4@1+ (1,0) [0|15] ""  Charger
 SG_ SingleBatteryVoltage025 : 384|12@1+ (0.01,0) [0|24] "V"  Charger
 SG_ SingleBatteryGroup024 : 380|4@1+ (1,0) [0|15] ""  Charger
 SG_ SingleBatteryVoltage024 : 368|12@1+ (0.01,0) [0|24] "V"  Charger
 SG_ SingleBatteryGroup023 : 364|4@1+ (1,0) [0|15] ""  Charger
 SG_ SingleBatteryVoltage023 : 352|12@1+ (0.01,0) [0|24] "V"  Charger
 SG_ SingleBatteryGroup022 : 348|4@1+ (1,0) [0|15] ""  Charger
 SG_ SingleBatteryVoltage022 : 336|12@1+ (0.01,0) [0|24] "V"  Charger
 SG_ SingleBatteryGroup021 : 332|4@1+ (1,0) [0|15] ""  Charger
 SG_ SingleBatteryVoltage021 : 320|12@1+ (0.01,0) [0|24] "V"  Charger
 SG_ SingleBatteryGroup020 : 316|4@1+ (1,0) [0|15] ""  Charger
 SG_ SingleBatteryVoltage020 : 304|12@1+ (0.01,0) [0|24] "V"  Charger
 SG_ SingleBatteryGroup019 : 300|4@1+ (1,0) [0|15] ""  Charger
 SG_ SingleBatteryVoltage019 : 288|12@1+ (0.01,0) [0|24] "V"  Charger
 SG_ SingleBatteryGroup018 : 284|4@1+ (1,0) [0|15] ""  Charger
 SG_ SingleBatteryVoltage018 : 272|12@1+ (0.01,0) [0|24] "V"  Charger
 SG_ SingleBatteryGroup017 : 268|4@1+ (1,0) [0|15] ""  Charger
 SG_ SingleBatteryVoltage017 : 256|12@1+ (0.01,0) [0|24] "V"  Charger
 SG_ SingleBatteryGroup016 : 252|4@1+ (1,0) [0|15] ""  Charger
 SG_ SingleBatteryVoltage016 : 240|12@1+ (0.01,0) [0|24] "V"  Charger
 SG_ SingleBatteryGroup015 : 236|4@1+ (1,0) [0|15] ""  Charger
 SG_ SingleBatteryVoltage015 : 224|12@1+ (0.01,0) [0|24] "V"  Charger
 SG_ SingleBatteryGroup014 : 220|4@1+ (1,0) [0|15] ""  Charger
 SG_ SingleBatteryVoltage014 : 208|12@1+ (0.01,0) [0|24] "V"  Charger
 SG_ SingleBatteryGroup013 : 204|4@1+ (1,0) [0|15] ""  Charger
 SG_ SingleBatteryVoltage013 : 192|12@1+ (0.01,0) [0|24] "V"  Charger
 SG_ SingleBatteryGroup012 : 188|4@1+ (1,0) [0|15] ""  Charger
 SG_ SingleBatteryVoltage012 : 176|12@1+ (0.01,0) [0|24] "V"  Charger
 SG_ SingleBatteryGroup011 : 172|4@1+ (1,0) [0|15] ""  Charger
 SG_ SingleBatteryVoltage011 : 160|12@1+ (0.01,0) [0|24] "V"  Charger
 SG_ SingleBatteryGroup010 : 156|4@1+ (1,0) [0|15] ""  Charger
 SG_ SingleBatteryVoltage010 : 144|12@1+ (0.01,0) [0|24] "V"  Charger
 SG_ SingleBatteryGroup009 : 140|4@1+ (1,0) [0|15] ""  Charger
 SG_ SingleBatteryVoltage009 : 128|12@1+ (0.01,0) [0|24] "V"  Charger
 SG_ SingleBatteryGroup008 : 124|4@1+ (1,0) [0|15] ""  Charger
 SG_ SingleBatteryVoltage008 : 112|12@1+ (0.01,0) [0|24] "V"  Charger
 SG_ SingleBatteryGroup007 : 108|4@1+ (1,0) [0|15] ""  Charger
 SG_ SingleBatteryVoltage007 : 96|12@1+ (0.01,0) [0|24] "V"  Charger
 SG_ SingleBatteryGroup006 : 92|4@1+ (1,0) [0|15] ""  Charger
 SG_ SingleBatteryVoltage006 : 80|12@1+ (0.01,0) [0|24] "V"  Charger
 SG_ SingleBatteryGroup005 : 76|4@1+ (1,0) [0|15] ""  Charger
 SG_ SingleBatteryVoltage005 : 64|12@1+ (0.01,0) [0|24] "V"  Charger
 SG_ SingleBatteryGroup004 : 60|4@1+ (1,0) [0|15] ""  Charger
 SG_ SingleBatteryVoltage004 : 48|12@1+ (0.01,0) [0|24] "V"  Charger
 SG_ SingleBatteryGroup003 : 44|4@1+ (1,0) [0|15] ""  Charger
 SG_ SingleBatteryVoltage003 : 32|12@1+ (0.01,0) [0|24] "V"  Charger
 SG_ SingleBatteryGroup002 : 28|4@1+ (1,0) [0|15] ""  Charger
 SG_ SingleBatteryVoltage002 : 16|12@1+ (0.01,0) [0|24] "V"  Charger
 SG_ SingleBatteryGroup001 : 12|4@1+ (1,0) [0|15] ""  Charger
 SG_ SingleBatteryVoltage001 : 0|12@1+ (0.01,0) [0|24] "V"  Charger

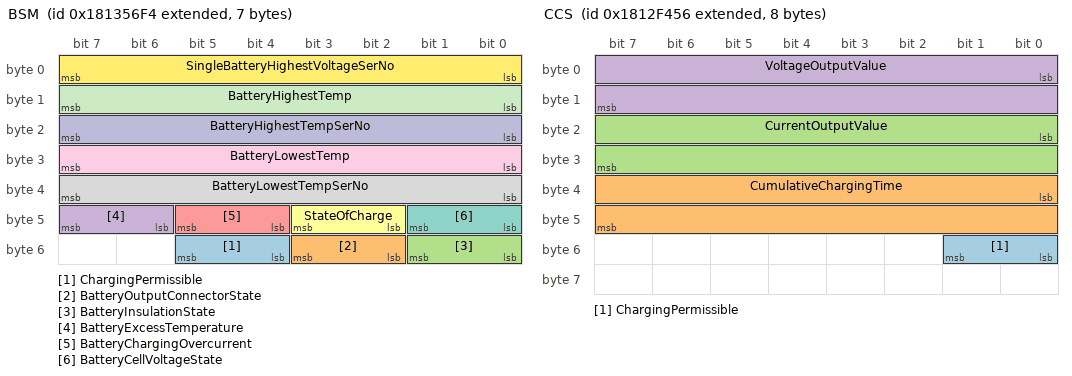
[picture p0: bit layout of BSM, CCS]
BO_ 2551404276 BSM: 7 BMS
 SG_ ChargingPermissible : 52|2@1+ (1,0) [0|3] ""  Charger
 SG_ BatteryOutputConnectorState : 50|2@1+ (1,0) [0|3] ""  Charger
 SG_ BatteryInsulationState : 48|2@1+ (1,0) [0|3] ""  Charger
 SG_ BatteryExcessTemperature : 46|2@1+ (1,0) [0|3] ""  Charger
 SG_ BatteryChargingOvercurrent : 44|2@1+ (1,0) [0|3] ""  Charger
 SG_ StateOfCharge : 42|2@1+ (1,0) [0|3] ""  Charger
 SG_ BatteryCellVoltageState : 40|2@1+ (1,0) [0|3] ""  Charger
 SG_ BatteryLowestTempSerNo : 32|8@1+ (1,1) [1|256] ""  Charger
 SG_ BatteryLowestTemp : 24|8@1+ (1,-50) [-50|200] "°C"  Charger
 SG_ BatteryHighestTempSerNo : 16|8@1+ (1,1) [1|256] ""  Charger
 SG_ BatteryHighestTemp : 8|8@1+ (1,-50) [-50|200] "°C"  Charger
 SG_ SingleBatteryHighestVoltageSerNo : 0|8@1+ (1,1) [1|256] ""  Charger

BO_ 2551379030 CCS: 8 Charger
 SG_ ChargingPermissible : 48|2@1+ (1,0) [0|3] ""  BMS
 SG_ CumulativeChargingTime : 32|16@1+ (1,0) [0|600] "min"  BMS
 SG_ CurrentOutputValue : 16|16@1+ (0.1,-400) [-400|6153.5] "A"  BMS
 SG_ VoltageOutputValue : 0|16@1+ (0.1,0) [0|6553.5] "V"  BMS

BO_ 2618382068 BCS: 9 BMS
 SG_ EstimatedRemainingChargingTime : 56|16@1+ (1,0) [0|600] "min"  Charger
 SG_ CurrentChargeState : 48|8@1+ (1,0) [0|100] "%"  Charger
 SG_ GroupNrOfCellWithHighestVoltage : 44|4@1+ (1,0) [0|15] ""  Charger
 SG_ HighestVoltageOfBatteryCell : 32|12@1+ (0.01,0) [0|24] "V"  Charger
 SG_ MeasuredChargingCurrent : 16|16@1+ (0.1,-400) [-400|6153.5] "A"  Charger
 SG_ MeasuredChargingVoltage : 0|16@1+ (0.1,0) [0|6553.5] "V"  Charger

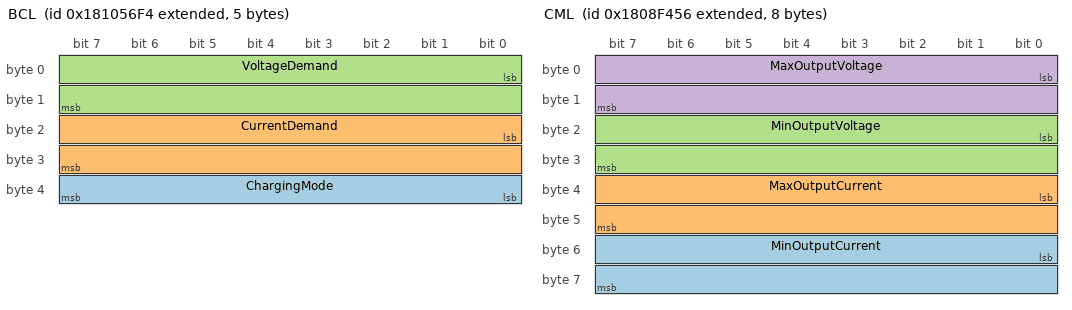
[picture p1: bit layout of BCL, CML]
BO_ 2551207668 BCL: 5 BMS
 SG_ ChargingMode : 32|8@1+ (1,0) [0|0] ""  Charger
 SG_ CurrentDemand : 16|16@1+ (0.1,-400) [-400|6153.5] "A"  Charger
 SG_ VoltageDemand : 0|16@1+ (0.1,0) [0|6553.5] "V"  Charger

BO_ 2416637014 CRO: 1 Charger
 SG_ ChargerReadyForCharging : 0|8@1+ (1,0) [0|255] ""  BMS

BO_ 2416531188 BRO: 1 BMS
 SG_ BmsReadyForCharging : 0|8@1+ (1,0) [0|255] ""  Charger

BO_ 2550723670 CML: 8 Charger
 SG_ MinOutputCurrent : 48|16@1+ (0.1,-400) [-400|6153.5] "A"  BMS
 SG_ MaxOutputCurrent : 32|16@1+ (0.1,-400) [-400|6153.5] "A"  BMS
 SG_ MinOutputVoltage : 16|16@1+ (0.1,0) [0|6553.5] "V"  BMS
 SG_ MaxOutputVoltage : 0|16@1+ (0.1,0) [0|6553.5] "V"  BMS

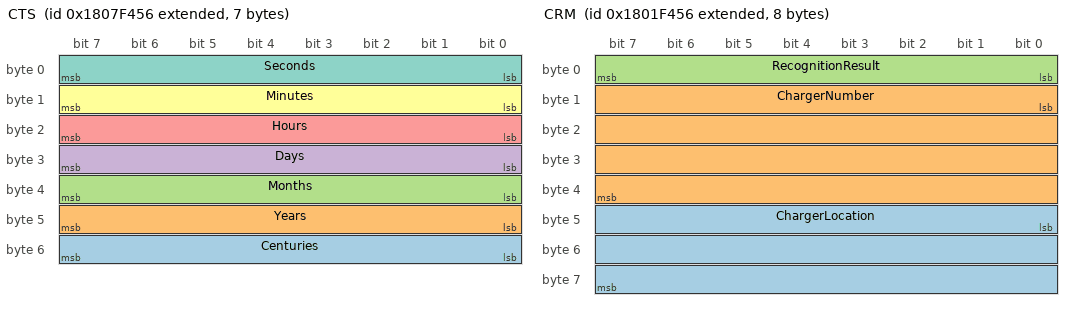
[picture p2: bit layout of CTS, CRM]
BO_ 2550658134 CTS: 7 Charger
 SG_ Centuries : 48|8@1+ (1,0) [0|0] "" Vector__XXX
 SG_ Years : 40|8@1+ (1,0) [0|0] "" Vector__XXX
 SG_ Months : 32|8@1+ (1,0) [0|255] "" Vector__XXX
 SG_ Days : 24|8@1+ (1,0) [0|255] "" Vector__XXX
 SG_ Hours : 16|8@1+ (1,0) [0|0] "" Vector__XXX
 SG_ Minutes : 8|8@1+ (1,0) [0|0] "" Vector__XXX
 SG_ Seconds : 0|8@1+ (1,0) [0|0] "" Vector__XXX

BO_ 2617661172 BCP: 13 BMS
 SG_ CurrentBatteryVoltage : 88|16@1+ (0.1,0) [0|6553.5] "V"  Charger
 SG_ StatusOfCharge : 72|16@1+ (0.1,0) [0|100] "%"  Charger
 SG_ MaxPermTemperature : 64|8@1+ (1,-50) [-50|200] "°C"  Charger
 SG_ TotalMaxPermChargingVoltage : 48|16@1+ (0.1,0) [0|6553.5] "V"  Charger
 SG_ TotalNominalEnergy : 32|16@1+ (0.1,0) [0|1000] "kWh"  Charger
 SG_ MaxPermChargingCurrent : 16|16@1+ (0.1,-400) [-400|6153.5] "A"  Charger
 SG_ MaxBattCellChargingVoltage : 0|16@1+ (0.01,0) [0|24] "V"  Charger

BO_ 2617399028 BRM: 49 BMS
 SG_ BmsSoftwareVersion_Reserved : 368|24@1+ (1,0) [0|16777215] ""  Charger
 SG_ BmsSoftwareVersion_CompileYear : 352|16@1+ (1,0) [0|65534] ""  Charger
 SG_ BmsSoftwareVersion_CompileMonth : 344|8@1+ (1,0) [1|12] ""  Charger
 SG_ BmsSoftwareVersion_CompileDay : 336|8@1+ (1,0) [1|31] ""  Charger
 SG_ BmsSoftwareVersion_Serial : 328|8@1+ (1,0) [1|254] ""  Charger
 SG_ BRM_Reserved1 : 184|8@1+ (1,0) [0|255] ""  Charger
 SG_ VIN : 192|136@1+ (1,0) [0|0] ""  Charger
 SG_ Property : 176|8@1+ (1,0) [0|1] ""  Charger
 SG_ ChargingFrequency : 152|24@1+ (1,0) [0|16777215] ""  Charger
 SG_ ProductionDay : 144|8@1+ (1,0) [0|31] "Days"  Charger
 SG_ ProductionMonth : 136|8@1+ (1,0) [1|12] ""  Charger
 SG_ ProductionYear : 128|8@1+ (1,1985) [1985|2235] "Years"  Charger
 SG_ BatteryPackNumber : 96|32@1+ (1,0) [0|4294967295] ""  Charger
 SG_ ManufacturerName : 64|32@1+ (1,0) [0|4294967295] ""  Charger
 SG_ BatterySystemVoltage : 48|16@1+ (0.1,0) [0|6553.5] "V"  Charger
 SG_ BatterySystemCapacity : 32|16@1+ (0.1,0) [0|6553.5] "Ah"  Charger
 SG_ BmsVersion : 8|16@1+ (1,0) [0|65535] ""  Charger
 SG_ BmsRevision : 0|8@1+ (1,0) [0|255] ""  Charger
 SG_ BatteryType : 24|8@1+ (1,0) [0|255] ""  Charger

BO_ 2550264918 CRM: 8 Charger
 SG_ ChargerLocation : 40|24@1+ (1,0) [0|16777215] ""  BMS
 SG_ ChargerNumber : 8|32@1+ (1,0) [0|4294967295] ""  BMS
 SG_ RecognitionResult : 0|8@1+ (1,0) [0|170] ""  BMS

BO_ 2552714996 BHM: 2 BMS
 SG_ MaxChargingVoltage : 0|16@1+ (0.1,0) [0|6553.5] "V"  Charger

BO_ 2552689750 CHM: 3 Charger
 SG_ MinorChargerVersion : 0|8@1+ (1,0) [0|65535] "" Vector__XXX
 SG_ MajorChargerVersion : 8|16@1+ (1,0) [0|65535] ""  BMS

BO_ 2565603070 TPDT: 8 Vector__XXX
 SG_ SequenceNumber : 0|8@1+ (1,0) [0|255] "" Vector__XXX

BO_ 2565668606 TPCMxx: 8 Vector__XXX
 SG_ TotalNumberOfPacketsEoMA m19 : 24|8@1+ (1,0) [0|255] "" Vector__XXX
 SG_ TotalMessageSizeEoMA m19 : 8|16@1+ (1,0) [0|64255] "" Vector__XXX
 SG_ TotalMessageSizeBAM m32 : 8|16@1+ (1,0) [0|64255] "" Vector__XXX
 SG_ TotalNumberOfPacketsBAM m32 : 24|8@1+ (1,0) [0|255] "" Vector__XXX
 SG_ ConnectionAbortReason m255 : 8|8@1+ (1,0) [0|255] "" Vector__XXX
 SG_ NextPacketNumberToBeSent m17 : 16|8@1+ (1,0) [0|255] "" Vector__XXX
 SG_ NumberOfPacketsThatCanBeSent m17 : 8|8@1+ (1,0) [0|255] "" Vector__XXX
 SG_ PGNumber : 40|24@1+ (1,0) [0|16777200] "" Vector__XXX
 SG_ MaximumNumberOfPackets m16 : 32|8@1+ (1,0) [0|255] "" Vector__XXX
 SG_ TotalNumberOfPackets m16 : 24|8@1+ (1,0) [0|255] "" Vector__XXX
 SG_ TotalMessageSize m16 : 8|16@1+ (1,0) [0|64255] "" Vector__XXX
 SG_ ControlByte M : 0|8@1+ (1,0) [0|255] "" Vector__XXX

BO_ 2565537534 RQST: 3 Vector__XXX
 SG_ ParameterGroupNumber : 0|24@1+ (1,0) [0|16777215] "" Vector__XXX

BO_ 2565406462 ACKM: 8 Vector__XXX
 SG_ AddressBusy m3 : 32|8@1+ (1,0) [0|255] "" Vector__XXX
 SG_ ControlByte M : 0|8@1+ (1,0) [0|255] "" Vector__XXX
 SG_ ParameterGroupNumber : 40|24@1+ (1,0) [0|16777215] "" Vector__XXX
 SG_ GroupFunctionValue : 8|8@1+ (1,0) [0|255] "" Vector__XXX
 SG_ AddressAccessDenied m2 : 32|8@1+ (1,0) [0|255] "" Vector__XXX
 SG_ AddressNegativeAcknowledgement m1 : 32|8@1+ (1,0) [0|255] "" Vector__XXX
 SG_ AddressAcknowledged m0 : 32|8@1+ (1,0) [0|255] "" Vector__XXX

CM_ BO_ 2618644212 "[Charging] Single power storage battery voltage";
CM_ SG_ 2618644212 SingleBatteryGroup256 "#256 single power storage battery voltage

battery grouping No.";
CM_ SG_ 2618644212 SingleBatteryVoltage256 "#256 single power storage battery voltage

single power storage battery voltage";
CM_ SG_ 2618644212 SingleBatteryGroup255 "#255 single power storage battery voltage

battery grouping No.";
CM_ SG_ 2618644212 SingleBatteryVoltage255 "#255 single power storage battery voltage

single power storage battery voltage";
CM_ SG_ 2618644212 SingleBatteryGroup254 "#254 single power storage battery voltage

battery grouping No.";
CM_ SG_ 2618644212 SingleBatteryVoltage254 "#254 single power storage battery voltage

single power storage battery voltage";
CM_ SG_ 2618644212 SingleBatteryGroup253 "#253 single power storage battery voltage

battery grouping No.";
CM_ SG_ 2618644212 SingleBatteryVoltage253 "#253 single power storage battery voltage

single power storage battery voltage";
CM_ SG_ 2618644212 SingleBatteryGroup252 "#252 single power storage battery voltage

battery grouping No.";
CM_ SG_ 2618644212 SingleBatteryVoltage252 "#252 single power storage battery voltage

single power storage battery voltage";
CM_ SG_ 2618644212 SingleBatteryGroup251 "#251 single power storage battery voltage

battery grouping No.";
CM_ SG_ 2618644212 SingleBatteryVoltage251 "#251 single power storage battery voltage

single power storage battery voltage";
CM_ SG_ 2618644212 SingleBatteryGroup250 "#250 single power storage battery voltage

battery grouping No.";
CM_ SG_ 2618644212 SingleBatteryVoltage250 "#250 single power storage battery voltage

single power storage battery voltage";
CM_ SG_ 2618644212 SingleBatteryGroup249 "#249 single power storage battery voltage

battery grouping No.";
CM_ SG_ 2618644212 SingleBatteryVoltage249 "#249 single power storage battery voltage

single power storage battery voltage";
CM_ SG_ 2618644212 SingleBatteryGroup248 "#248 single power storage battery voltage

battery grouping No.";
CM_ SG_ 2618644212 SingleBatteryVoltage248 "#248 single power storage battery voltage

single power storage battery voltage";
CM_ SG_ 2618644212 SingleBatteryGroup247 "#247 single power storage battery voltage

battery grouping No.";
CM_ SG_ 2618644212 SingleBatteryVoltage247 "#247 single power storage battery voltage

single power storage battery voltage";
CM_ SG_ 2618644212 SingleBatteryGroup246 "#246 single power storage battery voltage

battery grouping No.";
CM_ SG_ 2618644212 SingleBatteryVoltage246 "#246 single power storage battery voltage

single power storage battery voltage";
CM_ SG_ 2618644212 SingleBatteryGroup245 "#245 single power storage battery voltage

battery grouping No.";
CM_ SG_ 2618644212 SingleBatteryVoltage245 "#245 single power storage battery voltage

single power storage battery voltage";
CM_ SG_ 2618644212 SingleBatteryGroup244 "#244 single power storage battery voltage

battery grouping No.";
CM_ SG_ 2618644212 SingleBatteryVoltage244 "#244 single power storage battery voltage

single power storage battery voltage";
CM_ SG_ 2618644212 SingleBatteryGroup243 "#243 single power storage battery voltage

battery grouping No.";
CM_ SG_ 2618644212 SingleBatteryVoltage243 "#243 single power storage battery voltage

single power storage battery voltage";
CM_ SG_ 2618644212 SingleBatteryGroup242 "#242 single power storage battery voltage

battery grouping No.";
CM_ SG_ 2618644212 SingleBatteryVoltage242 "#242 single power storage battery voltage

single power storage battery voltage";
CM_ SG_ 2618644212 SingleBatteryGroup241 "#241 single power storage battery voltage

battery grouping No.";
CM_ SG_ 2618644212 SingleBatteryVoltage241 "#241 single power storage battery voltage

single power storage battery voltage";
CM_ SG_ 2618644212 SingleBatteryGroup240 "#240 single power storage battery voltage

battery grouping No.";
CM_ SG_ 2618644212 SingleBatteryVoltage240 "#240 single power storage battery voltage

single power storage battery voltage";
CM_ SG_ 2618644212 SingleBatteryGroup239 "#239 single power storage battery voltage

battery grouping No.";
CM_ SG_ 2618644212 SingleBatteryVoltage239 "#239 single power storage battery voltage

single power storage battery voltage";
CM_ SG_ 2618644212 SingleBatteryGroup238 "#238 single power storage battery voltage

battery grouping No.";
CM_ SG_ 2618644212 SingleBatteryVoltage238 "#238 single power storage battery voltage

single power storage battery voltage";
CM_ SG_ 2618644212 SingleBatteryGroup237 "#237 single power storage battery voltage

battery grouping No.";
CM_ SG_ 2618644212 SingleBatteryVoltage237 "#237 single power storage battery voltage

single power storage battery voltage";
CM_ SG_ 2618644212 SingleBatteryGroup236 "#236 single power storage battery voltage

battery grouping No.";
CM_ SG_ 2618644212 SingleBatteryVoltage236 "#236 single power storage battery voltage

single power storage battery voltage";
CM_ SG_ 2618644212 SingleBatteryGroup235 "#235 single power storage battery voltage

battery grouping No.";
CM_ SG_ 2618644212 SingleBatteryVoltage235 "#235 single power storage battery voltage

single power storage battery voltage";
CM_ SG_ 2618644212 SingleBatteryGroup234 "#234 single power storage battery voltage

battery grouping No.";
CM_ SG_ 2618644212 SingleBatteryVoltage234 "#234 single power storage battery voltage

single power storage battery voltage";
CM_ SG_ 2618644212 SingleBatteryGroup233 "#233 single power storage battery voltage

battery grouping No.";
CM_ SG_ 2618644212 SingleBatteryVoltage233 "#233 single power storage battery voltage

single power storage battery voltage";
CM_ SG_ 2618644212 SingleBatteryGroup232 "#232 single power storage battery voltage

battery grouping No.";
CM_ SG_ 2618644212 SingleBatteryVoltage232 "#232 single power storage battery voltage

single power storage battery voltage";
CM_ SG_ 2618644212 SingleBatteryGroup231 "#231 single power storage battery voltage

battery grouping No.";
CM_ SG_ 2618644212 SingleBatteryVoltage231 "#231 single power storage battery voltage

single power storage battery voltage";
CM_ SG_ 2618644212 SingleBatteryGroup230 "#230 single power storage battery voltage

battery grouping No.";
CM_ SG_ 2618644212 SingleBatteryVoltage230 "#230 single power storage battery voltage

single power storage battery voltage";
CM_ SG_ 2618644212 SingleBatteryGroup229 "#229 single power storage battery voltage

battery grouping No.";
CM_ SG_ 2618644212 SingleBatteryVoltage229 "#229 single power storage battery voltage

single power storage battery voltage";
CM_ SG_ 2618644212 SingleBatteryGroup228 "#228 single power storage battery voltage

battery grouping No.";
CM_ SG_ 2618644212 SingleBatteryVoltage228 "#228 single power storage battery voltage

single power storage battery voltage";
CM_ SG_ 2618644212 SingleBatteryGroup227 "#227 single power storage battery voltage

battery grouping No.";
CM_ SG_ 2618644212 SingleBatteryVoltage227 "#227 single power storage battery voltage

single power storage battery voltage";
CM_ SG_ 2618644212 SingleBatteryGroup226 "#226 single power storage battery voltage

battery grouping No.";
CM_ SG_ 2618644212 SingleBatteryVoltage226 "#226 single power storage battery voltage

single power storage battery voltage";
CM_ SG_ 2618644212 SingleBatteryGroup225 "#225 single power storage battery voltage

battery grouping No.";
CM_ SG_ 2618644212 SingleBatteryVoltage225 "#225 single power storage battery voltage

single power storage battery voltage";
CM_ SG_ 2618644212 SingleBatteryGroup224 "#224 single power storage battery voltage

battery grouping No.";
CM_ SG_ 2618644212 SingleBatteryVoltage224 "#224 single power storage battery voltage

single power storage battery voltage";
CM_ SG_ 2618644212 SingleBatteryGroup223 "#223 single power storage battery voltage

battery grouping No.";
CM_ SG_ 2618644212 SingleBatteryVoltage223 "#223 single power storage battery voltage

single power storage battery voltage";
CM_ SG_ 2618644212 SingleBatteryGroup222 "#222 single power storage battery voltage

battery grouping No.";
CM_ SG_ 2618644212 SingleBatteryVoltage222 "#222 single power storage battery voltage

single power storage battery voltage";
CM_ SG_ 2618644212 SingleBatteryGroup221 "#221 single power storage battery voltage

battery grouping No.";
CM_ SG_ 2618644212 SingleBatteryVoltage221 "#221 single power storage battery voltage

single power storage battery voltage";
CM_ SG_ 2618644212 SingleBatteryGroup220 "#220 single power storage battery voltage

battery grouping No.";
CM_ SG_ 2618644212 SingleBatteryVoltage220 "#220 single power storage battery voltage

single power storage battery voltage";
CM_ SG_ 2618644212 SingleBatteryGroup219 "#219 single power storage battery voltage

battery grouping No.";
CM_ SG_ 2618644212 SingleBatteryVoltage219 "#219 single power storage battery voltage

single power storage battery voltage";
CM_ SG_ 2618644212 SingleBatteryGroup218 "#218 single power storage battery voltage

battery grouping No.";
CM_ SG_ 2618644212 SingleBatteryVoltage218 "#218 single power storage battery voltage

single power storage battery voltage";
CM_ SG_ 2618644212 SingleBatteryGroup217 "#217 single power storage battery voltage

battery grouping No.";
CM_ SG_ 2618644212 SingleBatteryVoltage217 "#217 single power storage battery voltage

single power storage battery voltage";
CM_ SG_ 2618644212 SingleBatteryGroup216 "#216 single power storage battery voltage

battery grouping No.";
CM_ SG_ 2618644212 SingleBatteryVoltage216 "#216 single power storage battery voltage

single power storage battery voltage";
CM_ SG_ 2618644212 SingleBatteryGroup215 "#215 single power storage battery voltage

battery grouping No.";
CM_ SG_ 2618644212 SingleBatteryVoltage215 "#215 single power storage battery voltage

single power storage battery voltage";
CM_ SG_ 2618644212 SingleBatteryGroup214 "#214 single power storage battery voltage

battery grouping No.";
CM_ SG_ 2618644212 SingleBatteryVoltage214 "#214 single power storage battery voltage

single power storage battery voltage";
CM_ SG_ 2618644212 SingleBatteryGroup213 "#213 single power storage battery voltage

battery grouping No.";
CM_ SG_ 2618644212 SingleBatteryVoltage213 "#213 single power storage battery voltage

single power storage battery voltage";
CM_ SG_ 2618644212 SingleBatteryGroup212 "#212 single power storage battery voltage

battery grouping No.";
CM_ SG_ 2618644212 SingleBatteryVoltage212 "#212 single power storage battery voltage

single power storage battery voltage";
CM_ SG_ 2618644212 SingleBatteryGroup211 "#211 single power storage battery voltage

battery grouping No.";
CM_ SG_ 2618644212 SingleBatteryVoltage211 "#211 single power storage battery voltage

single power storage battery voltage";
CM_ SG_ 2618644212 SingleBatteryGroup210 "#210 single power storage battery voltage

battery grouping No.";
CM_ SG_ 2618644212 SingleBatteryVoltage210 "#210 single power storage battery voltage

single power storage battery voltage";
CM_ SG_ 2618644212 SingleBatteryGroup209 "#209 single power storage battery voltage

battery grouping No.";
CM_ SG_ 2618644212 SingleBatteryVoltage209 "#209 single power storage battery voltage

single power storage battery voltage";
CM_ SG_ 2618644212 SingleBatteryGroup208 "#208 single power storage battery voltage

battery grouping No.";
CM_ SG_ 2618644212 SingleBatteryVoltage208 "#208 single power storage battery voltage

single power storage battery voltage";
CM_ SG_ 2618644212 SingleBatteryGroup207 "#207 single power storage battery voltage

battery grouping No.";
CM_ SG_ 2618644212 SingleBatteryVoltage207 "#207 single power storage battery voltage

single power storage battery voltage";
CM_ SG_ 2618644212 SingleBatteryGroup206 "#206 single power storage battery voltage

battery grouping No.";
CM_ SG_ 2618644212 SingleBatteryVoltage206 "#206 single power storage battery voltage

single power storage battery voltage";
CM_ SG_ 2618644212 SingleBatteryGroup205 "#205 single power storage battery voltage

battery grouping No.";
CM_ SG_ 2618644212 SingleBatteryVoltage205 "#205 single power storage battery voltage

single power storage battery voltage";
CM_ SG_ 2618644212 SingleBatteryGroup204 "#204 single power storage battery voltage

battery grouping No.";
CM_ SG_ 2618644212 SingleBatteryVoltage204 "#204 single power storage battery voltage

single power storage battery voltage";
CM_ SG_ 2618644212 SingleBatteryGroup203 "#203 single power storage battery voltage

battery grouping No.";
CM_ SG_ 2618644212 SingleBatteryVoltage203 "#203 single power storage battery voltage

single power storage battery voltage";
CM_ SG_ 2618644212 SingleBatteryGroup202 "#202 single power storage battery voltage

battery grouping No.";
CM_ SG_ 2618644212 SingleBatteryVoltage202 "#202 single power storage battery voltage

single power storage battery voltage";
CM_ SG_ 2618644212 SingleBatteryGroup201 "#201 single power storage battery voltage

battery grouping No.";
CM_ SG_ 2618644212 SingleBatteryVoltage201 "#201 single power storage battery voltage

single power storage battery voltage";
CM_ SG_ 2618644212 SingleBatteryGroup200 "#200 single power storage battery voltage

battery grouping No.";
CM_ SG_ 2618644212 SingleBatteryVoltage200 "#200 single power storage battery voltage

single power storage battery voltage";
CM_ SG_ 2618644212 SingleBatteryGroup199 "#199 single power storage battery voltage

battery grouping No.";
CM_ SG_ 2618644212 SingleBatteryVoltage199 "#199 single power storage battery voltage

single power storage battery voltage";
CM_ SG_ 2618644212 SingleBatteryGroup198 "#198 single power storage battery voltage

battery grouping No.";
CM_ SG_ 2618644212 SingleBatteryVoltage198 "#198 single power storage battery voltage

single power storage battery voltage";
CM_ SG_ 2618644212 SingleBatteryGroup197 "#197 single power storage battery voltage

battery grouping No.";
CM_ SG_ 2618644212 SingleBatteryVoltage197 "#197 single power storage battery voltage

single power storage battery voltage";
CM_ SG_ 2618644212 SingleBatteryGroup196 "#196 single power storage battery voltage

battery grouping No.";
CM_ SG_ 2618644212 SingleBatteryVoltage196 "#196 single power storage battery voltage

single power storage battery voltage";
CM_ SG_ 2618644212 SingleBatteryGroup195 "#195 single power storage battery voltage

battery grouping No.";
CM_ SG_ 2618644212 SingleBatteryVoltage195 "#195 single power storage battery voltage

single power storage battery voltage";
CM_ SG_ 2618644212 SingleBatteryGroup194 "#194 single power storage battery voltage

battery grouping No.";
CM_ SG_ 2618644212 SingleBatteryVoltage194 "#194 single power storage battery voltage

single power storage battery voltage";
CM_ SG_ 2618644212 SingleBatteryGroup193 "#193 single power storage battery voltage

battery grouping No.";
CM_ SG_ 2618644212 SingleBatteryVoltage193 "#193 single power storage battery voltage

single power storage battery voltage";
CM_ SG_ 2618644212 SingleBatteryGroup192 "#192 single power storage battery voltage

battery grouping No.";
CM_ SG_ 2618644212 SingleBatteryVoltage192 "#192 single power storage battery voltage

single power storage battery voltage";
CM_ SG_ 2618644212 SingleBatteryGroup191 "#191 single power storage battery voltage

battery grouping No.";
CM_ SG_ 2618644212 SingleBatteryVoltage191 "#191 single power storage battery voltage

single power storage battery voltage";
CM_ SG_ 2618644212 SingleBatteryGroup190 "#190 single power storage battery voltage

battery grouping No.";
CM_ SG_ 2618644212 SingleBatteryVoltage190 "#190 single power storage battery voltage

single power storage battery voltage";
CM_ SG_ 2618644212 SingleBatteryGroup189 "#189 single power storage battery voltage

battery grouping No.";
CM_ SG_ 2618644212 SingleBatteryVoltage189 "#189 single power storage battery voltage

single power storage battery voltage";
CM_ SG_ 2618644212 SingleBatteryGroup188 "#188 single power storage battery voltage

battery grouping No.";
CM_ SG_ 2618644212 SingleBatteryVoltage188 "#188 single power storage battery voltage

single power storage battery voltage";
CM_ SG_ 2618644212 SingleBatteryGroup187 "#187 single power storage battery voltage

battery grouping No.";
CM_ SG_ 2618644212 SingleBatteryVoltage187 "#187 single power storage battery voltage

single power storage battery voltage";
CM_ SG_ 2618644212 SingleBatteryGroup186 "#186 single power storage battery voltage

battery grouping No.";
CM_ SG_ 2618644212 SingleBatteryVoltage186 "#186 single power storage battery voltage

single power storage battery voltage";
CM_ SG_ 2618644212 SingleBatteryGroup185 "#185 single power storage battery voltage

battery grouping No.";
CM_ SG_ 2618644212 SingleBatteryVoltage185 "#185 single power storage battery voltage

single power storage battery voltage";
CM_ SG_ 2618644212 SingleBatteryGroup184 "#184 single power storage battery voltage

battery grouping No.";
CM_ SG_ 2618644212 SingleBatteryVoltage184 "#184 single power storage battery voltage

single power storage battery voltage";
CM_ SG_ 2618644212 SingleBatteryGroup183 "#183 single power storage battery voltage

battery grouping No.";
CM_ SG_ 2618644212 SingleBatteryVoltage183 "#183 single power storage battery voltage

single power storage battery voltage";
CM_ SG_ 2618644212 SingleBatteryGroup182 "#182 single power storage battery voltage

battery grouping No.";
CM_ SG_ 2618644212 SingleBatteryVoltage182 "#182 single power storage battery voltage

single power storage battery voltage";
CM_ SG_ 2618644212 SingleBatteryGroup181 "#181 single power storage battery voltage

battery grouping No.";
CM_ SG_ 2618644212 SingleBatteryVoltage181 "#181 single power storage battery voltage

single power storage battery voltage";
CM_ SG_ 2618644212 SingleBatteryGroup180 "#180 single power storage battery voltage

battery grouping No.";
CM_ SG_ 2618644212 SingleBatteryVoltage180 "#180 single power storage battery voltage

single power storage battery voltage";
CM_ SG_ 2618644212 SingleBatteryGroup179 "#179 single power storage battery voltage

battery grouping No.";
CM_ SG_ 2618644212 SingleBatteryVoltage179 "#179 single power storage battery voltage

single power storage battery voltage";
CM_ SG_ 2618644212 SingleBatteryGroup178 "#178 single power storage battery voltage

battery grouping No.";
CM_ SG_ 2618644212 SingleBatteryVoltage178 "#178 single power storage battery voltage

single power storage battery voltage";
CM_ SG_ 2618644212 SingleBatteryGroup177 "#177 single power storage battery voltage

battery grouping No.";
CM_ SG_ 2618644212 SingleBatteryVoltage177 "#177 single power storage battery voltage

single power storage battery voltage";
CM_ SG_ 2618644212 SingleBatteryGroup176 "#176 single power storage battery voltage

battery grouping No.";
CM_ SG_ 2618644212 SingleBatteryVoltage176 "#176 single power storage battery voltage

single power storage battery voltage";
CM_ SG_ 2618644212 SingleBatteryGroup175 "#175 single power storage battery voltage

battery grouping No.";
CM_ SG_ 2618644212 SingleBatteryVoltage175 "#175 single power storage battery voltage

single power storage battery voltage";
CM_ SG_ 2618644212 SingleBatteryGroup174 "#174 single power storage battery voltage

battery grouping No.";
CM_ SG_ 2618644212 SingleBatteryVoltage174 "#174 single power storage battery voltage

single power storage battery voltage";
CM_ SG_ 2618644212 SingleBatteryGroup173 "#173 single power storage battery voltage

battery grouping No.";
CM_ SG_ 2618644212 SingleBatteryVoltage173 "#173 single power storage battery voltage

single power storage battery voltage";
CM_ SG_ 2618644212 SingleBatteryGroup172 "#172 single power storage battery voltage

battery grouping No.";
CM_ SG_ 2618644212 SingleBatteryVoltage172 "#172 single power storage battery voltage

single power storage battery voltage";
CM_ SG_ 2618644212 SingleBatteryGroup171 "#171 single power storage battery voltage

battery grouping No.";
CM_ SG_ 2618644212 SingleBatteryVoltage171 "#171 single power storage battery voltage

single power storage battery voltage";
CM_ SG_ 2618644212 SingleBatteryGroup170 "#170 single power storage battery voltage

battery grouping No.";
CM_ SG_ 2618644212 SingleBatteryVoltage170 "#170 single power storage battery voltage

single power storage battery voltage";
CM_ SG_ 2618644212 SingleBatteryGroup169 "#169 single power storage battery voltage

battery grouping No.";
CM_ SG_ 2618644212 SingleBatteryVoltage169 "#169 single power storage battery voltage

single power storage battery voltage";
CM_ SG_ 2618644212 SingleBatteryGroup168 "#168 single power storage battery voltage

battery grouping No.";
CM_ SG_ 2618644212 SingleBatteryVoltage168 "#168 single power storage battery voltage

single power storage battery voltage";
CM_ SG_ 2618644212 SingleBatteryGroup167 "#167 single power storage battery voltage

battery grouping No.";
CM_ SG_ 2618644212 SingleBatteryVoltage167 "#167 single power storage battery voltage

single power storage battery voltage";
CM_ SG_ 2618644212 SingleBatteryGroup166 "#166 single power storage battery voltage

battery grouping No.";
CM_ SG_ 2618644212 SingleBatteryVoltage166 "#166 single power storage battery voltage

single power storage battery voltage";
CM_ SG_ 2618644212 SingleBatteryGroup165 "#165 single power storage battery voltage

battery grouping No.";
CM_ SG_ 2618644212 SingleBatteryVoltage165 "#165 single power storage battery voltage

single power storage battery voltage";
CM_ SG_ 2618644212 SingleBatteryGroup164 "#164 single power storage battery voltage

battery grouping No.";
CM_ SG_ 2618644212 SingleBatteryVoltage164 "#164 single power storage battery voltage

single power storage battery voltage";
CM_ SG_ 2618644212 SingleBatteryGroup163 "#163 single power storage battery voltage

battery grouping No.";
CM_ SG_ 2618644212 SingleBatteryVoltage163 "#163 single power storage battery voltage

single power storage battery voltage";
CM_ SG_ 2618644212 SingleBatteryGroup162 "#162 single power storage battery voltage

battery grouping No.";
CM_ SG_ 2618644212 SingleBatteryVoltage162 "#162 single power storage battery voltage

single power storage battery voltage";
CM_ SG_ 2618644212 SingleBatteryGroup161 "#161 single power storage battery voltage

battery grouping No.";
CM_ SG_ 2618644212 SingleBatteryVoltage161 "#161 single power storage battery voltage

single power storage battery voltage";
CM_ SG_ 2618644212 SingleBatteryGroup160 "#160 single power storage battery voltage

battery grouping No.";
CM_ SG_ 2618644212 SingleBatteryVoltage160 "#160 single power storage battery voltage

single power storage battery voltage";
CM_ SG_ 2618644212 SingleBatteryGroup159 "#159 single power storage battery voltage

battery grouping No.";
CM_ SG_ 2618644212 SingleBatteryVoltage159 "#159 single power storage battery voltage

single power storage battery voltage";
CM_ SG_ 2618644212 SingleBatteryGroup158 "#158 single power storage battery voltage

battery grouping No.";
CM_ SG_ 2618644212 SingleBatteryVoltage158 "#158 single power storage battery voltage

single power storage battery voltage";
CM_ SG_ 2618644212 SingleBatteryGroup157 "#157 single power storage battery voltage

battery grouping No.";
CM_ SG_ 2618644212 SingleBatteryVoltage157 "#157 single power storage battery voltage

single power storage battery voltage";
CM_ SG_ 2618644212 SingleBatteryGroup156 "#156 single power storage battery voltage

battery grouping No.";
CM_ SG_ 2618644212 SingleBatteryVoltage156 "#156 single power storage battery voltage

single power storage battery voltage";
CM_ SG_ 2618644212 SingleBatteryGroup155 "#155 single power storage battery voltage

battery grouping No.";
CM_ SG_ 2618644212 SingleBatteryVoltage155 "#155 single power storage battery voltage

single power storage battery voltage";
CM_ SG_ 2618644212 SingleBatteryGroup154 "#154 single power storage battery voltage

battery grouping No.";
CM_ SG_ 2618644212 SingleBatteryVoltage154 "#154 single power storage battery voltage

single power storage battery voltage";
CM_ SG_ 2618644212 SingleBatteryGroup153 "#153 single power storage battery voltage

battery grouping No.";
CM_ SG_ 2618644212 SingleBatteryVoltage153 "#153 single power storage battery voltage

single power storage battery voltage";
CM_ SG_ 2618644212 SingleBatteryGroup152 "#152 single power storage battery voltage

battery grouping No.";
CM_ SG_ 2618644212 SingleBatteryVoltage152 "#152 single power storage battery voltage

single power storage battery voltage";
CM_ SG_ 2618644212 SingleBatteryGroup151 "#151 single power storage battery voltage

battery grouping No.";
CM_ SG_ 2618644212 SingleBatteryVoltage151 "#151 single power storage battery voltage

single power storage battery voltage";
CM_ SG_ 2618644212 SingleBatteryGroup150 "#150 single power storage battery voltage

battery grouping No.";
CM_ SG_ 2618644212 SingleBatteryVoltage150 "#150 single power storage battery voltage

single power storage battery voltage";
CM_ SG_ 2618644212 SingleBatteryGroup149 "#149 single power storage battery voltage

battery grouping No.";
CM_ SG_ 2618644212 SingleBatteryVoltage149 "#149 single power storage battery voltage

single power storage battery voltage";
CM_ SG_ 2618644212 SingleBatteryGroup148 "#148 single power storage battery voltage

battery grouping No.";
CM_ SG_ 2618644212 SingleBatteryVoltage148 "#148 single power storage battery voltage

single power storage battery voltage";
CM_ SG_ 2618644212 SingleBatteryGroup147 "#147 single power storage battery voltage

battery grouping No.";
CM_ SG_ 2618644212 SingleBatteryVoltage147 "#147 single power storage battery voltage

single power storage battery voltage";
CM_ SG_ 2618644212 SingleBatteryGroup146 "#146 single power storage battery voltage

battery grouping No.";
CM_ SG_ 2618644212 SingleBatteryVoltage146 "#146 single power storage battery voltage

single power storage battery voltage";
CM_ SG_ 2618644212 SingleBatteryGroup145 "#145 single power storage battery voltage

battery grouping No.";
CM_ SG_ 2618644212 SingleBatteryVoltage145 "#145 single power storage battery voltage

single power storage battery voltage";
CM_ SG_ 2618644212 SingleBatteryGroup144 "#144 single power storage battery voltage

battery grouping No.";
CM_ SG_ 2618644212 SingleBatteryVoltage144 "#144 single power storage battery voltage

single power storage battery voltage";
CM_ SG_ 2618644212 SingleBatteryGroup143 "#143 single power storage battery voltage

battery grouping No.";
CM_ SG_ 2618644212 SingleBatteryVoltage143 "#143 single power storage battery voltage

single power storage battery voltage";
CM_ SG_ 2618644212 SingleBatteryGroup142 "#142 single power storage battery voltage

battery grouping No.";
CM_ SG_ 2618644212 SingleBatteryVoltage142 "#142 single power storage battery voltage

single power storage battery voltage";
CM_ SG_ 2618644212 SingleBatteryGroup141 "#141 single power storage battery voltage

battery grouping No.";
CM_ SG_ 2618644212 SingleBatteryVoltage141 "#141 single power storage battery voltage

single power storage battery voltage";
CM_ SG_ 2618644212 SingleBatteryGroup140 "#140 single power storage battery voltage

battery grouping No.";
CM_ SG_ 2618644212 SingleBatteryVoltage140 "#140 single power storage battery voltage

single power storage battery voltage";
CM_ SG_ 2618644212 SingleBatteryGroup139 "#139 single power storage battery voltage

battery grouping No.";
CM_ SG_ 2618644212 SingleBatteryVoltage139 "#139 single power storage battery voltage

single power storage battery voltage";
CM_ SG_ 2618644212 SingleBatteryGroup138 "#138 single power storage battery voltage

battery grouping No.";
CM_ SG_ 2618644212 SingleBatteryVoltage138 "#138 single power storage battery voltage

single power storage battery voltage";
CM_ SG_ 2618644212 SingleBatteryGroup137 "#137 single power storage battery voltage

battery grouping No.";
CM_ SG_ 2618644212 SingleBatteryVoltage137 "#137 single power storage battery voltage

single power storage battery voltage";
CM_ SG_ 2618644212 SingleBatteryGroup136 "#136 single power storage battery voltage

battery grouping No.";
CM_ SG_ 2618644212 SingleBatteryVoltage136 "#136 single power storage battery voltage

single power storage battery voltage";
CM_ SG_ 2618644212 SingleBatteryGroup135 "#135 single power storage battery voltage

battery grouping No.";
CM_ SG_ 2618644212 SingleBatteryVoltage135 "#135 single power storage battery voltage

single power storage battery voltage";
CM_ SG_ 2618644212 SingleBatteryGroup134 "#134 single power storage battery voltage

battery grouping No.";
CM_ SG_ 2618644212 SingleBatteryVoltage134 "#134 single power storage battery voltage

single power storage battery voltage";
CM_ SG_ 2618644212 SingleBatteryGroup133 "#133 single power storage battery voltage

battery grouping No.";
CM_ SG_ 2618644212 SingleBatteryVoltage133 "#133 single power storage battery voltage

single power storage battery voltage";
CM_ SG_ 2618644212 SingleBatteryGroup132 "#132 single power storage battery voltage

battery grouping No.";
CM_ SG_ 2618644212 SingleBatteryVoltage132 "#132 single power storage battery voltage

single power storage battery voltage";
CM_ SG_ 2618644212 SingleBatteryGroup131 "#131 single power storage battery voltage

battery grouping No.";
CM_ SG_ 2618644212 SingleBatteryVoltage131 "#131 single power storage battery voltage

single power storage battery voltage";
CM_ SG_ 2618644212 SingleBatteryGroup130 "#130 single power storage battery voltage

battery grouping No.";
CM_ SG_ 2618644212 SingleBatteryVoltage130 "#130 single power storage battery voltage

single power storage battery voltage";
CM_ SG_ 2618644212 SingleBatteryGroup129 "#129 single power storage battery voltage

battery grouping No.";
CM_ SG_ 2618644212 SingleBatteryVoltage129 "#129 single power storage battery voltage

single power storage battery voltage";
CM_ SG_ 2618644212 SingleBatteryGroup128 "#128 single power storage battery voltage

battery grouping No.";
CM_ SG_ 2618644212 SingleBatteryVoltage128 "#128 single power storage battery voltage

single power storage battery voltage";
CM_ SG_ 2618644212 SingleBatteryGroup127 "#127 single power storage battery voltage

battery grouping No.";
CM_ SG_ 2618644212 SingleBatteryVoltage127 "#127 single power storage battery voltage

single power storage battery voltage";
CM_ SG_ 2618644212 SingleBatteryGroup126 "#126 single power storage battery voltage

battery grouping No.";
CM_ SG_ 2618644212 SingleBatteryVoltage126 "#126 single power storage battery voltage

single power storage battery voltage";
CM_ SG_ 2618644212 SingleBatteryGroup125 "#125 single power storage battery voltage

battery grouping No.";
CM_ SG_ 2618644212 SingleBatteryVoltage125 "#125 single power storage battery voltage

single power storage battery voltage";
CM_ SG_ 2618644212 SingleBatteryGroup124 "#124 single power storage battery voltage

battery grouping No.";
CM_ SG_ 2618644212 SingleBatteryVoltage124 "#124 single power storage battery voltage

single power storage battery voltage";
CM_ SG_ 2618644212 SingleBatteryGroup123 "#123 single power storage battery voltage

battery grouping No.";
CM_ SG_ 2618644212 SingleBatteryVoltage123 "#123 single power storage battery voltage

single power storage battery voltage";
CM_ SG_ 2618644212 SingleBatteryGroup122 "#122 single power storage battery voltage

battery grouping No.";
CM_ SG_ 2618644212 SingleBatteryVoltage122 "#122 single power storage battery voltage

single power storage battery voltage";
CM_ SG_ 2618644212 SingleBatteryGroup121 "#121 single power storage battery voltage

battery grouping No.";
CM_ SG_ 2618644212 SingleBatteryVoltage121 "#121 single power storage battery voltage

single power storage battery voltage";
CM_ SG_ 2618644212 SingleBatteryGroup120 "#120 single power storage battery voltage

battery grouping No.";
CM_ SG_ 2618644212 SingleBatteryVoltage120 "#120 single power storage battery voltage

single power storage battery voltage";
CM_ SG_ 2618644212 SingleBatteryGroup119 "#119 single power storage battery voltage

battery grouping No.";
CM_ SG_ 2618644212 SingleBatteryVoltage119 "#119 single power storage battery voltage

single power storage battery voltage";
CM_ SG_ 2618644212 SingleBatteryGroup118 "#118 single power storage battery voltage

battery grouping No.";
CM_ SG_ 2618644212 SingleBatteryVoltage118 "#118 single power storage battery voltage

single power storage battery voltage";
CM_ SG_ 2618644212 SingleBatteryGroup117 "#117 single power storage battery voltage

battery grouping No.";
CM_ SG_ 2618644212 SingleBatteryVoltage117 "#117 single power storage battery voltage

single power storage battery voltage";
CM_ SG_ 2618644212 SingleBatteryGroup116 "#116 single power storage battery voltage

battery grouping No.";
CM_ SG_ 2618644212 SingleBatteryVoltage116 "#116 single power storage battery voltage

single power storage battery voltage";
CM_ SG_ 2618644212 SingleBatteryGroup115 "#115 single power storage battery voltage

battery grouping No.";
CM_ SG_ 2618644212 SingleBatteryVoltage115 "#115 single power storage battery voltage

single power storage battery voltage";
CM_ SG_ 2618644212 SingleBatteryGroup114 "#114 single power storage battery voltage

battery grouping No.";
CM_ SG_ 2618644212 SingleBatteryVoltage114 "#114 single power storage battery voltage

single power storage battery voltage";
CM_ SG_ 2618644212 SingleBatteryGroup113 "#113 single power storage battery voltage

battery grouping No.";
CM_ SG_ 2618644212 SingleBatteryVoltage113 "#113 single power storage battery voltage

single power storage battery voltage";
CM_ SG_ 2618644212 SingleBatteryGroup112 "#112 single power storage battery voltage

battery grouping No.";
CM_ SG_ 2618644212 SingleBatteryVoltage112 "#112 single power storage battery voltage

single power storage battery voltage";
CM_ SG_ 2618644212 SingleBatteryGroup111 "#111 single power storage battery voltage

battery grouping No.";
CM_ SG_ 2618644212 SingleBatteryVoltage111 "#111 single power storage battery voltage

single power storage battery voltage";
CM_ SG_ 2618644212 SingleBatteryGroup110 "#110 single power storage battery voltage

battery grouping No.";
CM_ SG_ 2618644212 SingleBatteryVoltage110 "#110 single power storage battery voltage

single power storage battery voltage";
CM_ SG_ 2618644212 SingleBatteryGroup109 "#109 single power storage battery voltage

battery grouping No.";
CM_ SG_ 2618644212 SingleBatteryVoltage109 "#109 single power storage battery voltage

single power storage battery voltage";
CM_ SG_ 2618644212 SingleBatteryGroup108 "#108 single power storage battery voltage

battery grouping No.";
CM_ SG_ 2618644212 SingleBatteryVoltage108 "#108 single power storage battery voltage

single power storage battery voltage";
CM_ SG_ 2618644212 SingleBatteryGroup107 "#107 single power storage battery voltage

battery grouping No.";
CM_ SG_ 2618644212 SingleBatteryVoltage107 "#107 single power storage battery voltage

single power storage battery voltage";
CM_ SG_ 2618644212 SingleBatteryGroup106 "#106 single power storage battery voltage

battery grouping No.";
CM_ SG_ 2618644212 SingleBatteryVoltage106 "#106 single power storage battery voltage

single power storage battery voltage";
CM_ SG_ 2618644212 SingleBatteryGroup105 "#105 single power storage battery voltage

battery grouping No.";
CM_ SG_ 2618644212 SingleBatteryVoltage105 "#105 single power storage battery voltage

single power storage battery voltage";
CM_ SG_ 2618644212 SingleBatteryGroup104 "#104 single power storage battery voltage

battery grouping No.";
CM_ SG_ 2618644212 SingleBatteryVoltage104 "#104 single power storage battery voltage

single power storage battery voltage";
CM_ SG_ 2618644212 SingleBatteryGroup103 "#103 single power storage battery voltage

battery grouping No.";
CM_ SG_ 2618644212 SingleBatteryVoltage103 "#103 single power storage battery voltage

single power storage battery voltage";
CM_ SG_ 2618644212 SingleBatteryGroup102 "#102 single power storage battery voltage

battery grouping No.";
CM_ SG_ 2618644212 SingleBatteryVoltage102 "#102 single power storage battery voltage

single power storage battery voltage";
CM_ SG_ 2618644212 SingleBatteryGroup101 "#101 single power storage battery voltage

battery grouping No.";
CM_ SG_ 2618644212 SingleBatteryVoltage101 "#101 single power storage battery voltage

single power storage battery voltage";
CM_ SG_ 2618644212 SingleBatteryGroup100 "#100 single power storage battery voltage

battery grouping No.";
CM_ SG_ 2618644212 SingleBatteryVoltage100 "#100 single power storage battery voltage

single power storage battery voltage";
CM_ SG_ 2618644212 SingleBatteryGroup099 "#99 single power storage battery voltage

battery grouping No.";
CM_ SG_ 2618644212 SingleBatteryVoltage099 "#99 single power storage battery voltage

single power storage battery voltage";
CM_ SG_ 2618644212 SingleBatteryGroup098 "#98 single power storage battery voltage

battery grouping No.";
CM_ SG_ 2618644212 SingleBatteryVoltage098 "#98 single power storage battery voltage

single power storage battery voltage";
CM_ SG_ 2618644212 SingleBatteryGroup097 "#97 single power storage battery voltage

battery grouping No.";
CM_ SG_ 2618644212 SingleBatteryVoltage097 "#97 single power storage battery voltage

single power storage battery voltage";
CM_ SG_ 2618644212 SingleBatteryGroup096 "#96 single power storage battery voltage

battery grouping No.";
CM_ SG_ 2618644212 SingleBatteryVoltage096 "#96 single power storage battery voltage

single power storage battery voltage";
CM_ SG_ 2618644212 SingleBatteryGroup095 "#95 single power storage battery voltage

battery grouping No.";
CM_ SG_ 2618644212 SingleBatteryVoltage095 "#95 single power storage battery voltage

single power storage battery voltage";
CM_ SG_ 2618644212 SingleBatteryGroup094 "#94 single power storage battery voltage

battery grouping No.";
CM_ SG_ 2618644212 SingleBatteryVoltage094 "#94 single power storage battery voltage

single power storage battery voltage";
CM_ SG_ 2618644212 SingleBatteryGroup093 "#93 single power storage battery voltage

battery grouping No.";
CM_ SG_ 2618644212 SingleBatteryVoltage093 "#93 single power storage battery voltage

single power storage battery voltage";
CM_ SG_ 2618644212 SingleBatteryGroup092 "#92 single power storage battery voltage

battery grouping No.";
CM_ SG_ 2618644212 SingleBatteryVoltage092 "#92 single power storage battery voltage

single power storage battery voltage";
CM_ SG_ 2618644212 SingleBatteryGroup091 "#91 single power storage battery voltage

battery grouping No.";
CM_ SG_ 2618644212 SingleBatteryVoltage091 "#91 single power storage battery voltage

single power storage battery voltage";
CM_ SG_ 2618644212 SingleBatteryGroup090 "#90 single power storage battery voltage

battery grouping No.";
CM_ SG_ 2618644212 SingleBatteryVoltage090 "#90 single power storage battery voltage

single power storage battery voltage";
CM_ SG_ 2618644212 SingleBatteryGroup089 "#89 single power storage battery voltage

battery grouping No.";
CM_ SG_ 2618644212 SingleBatteryVoltage089 "#89 single power storage battery voltage

single power storage battery voltage";
CM_ SG_ 2618644212 SingleBatteryGroup088 "#88 single power storage battery voltage

battery grouping No.";
CM_ SG_ 2618644212 SingleBatteryVoltage088 "#88 single power storage battery voltage

single power storage battery voltage";
CM_ SG_ 2618644212 SingleBatteryGroup087 "#87 single power storage battery voltage

battery grouping No.";
CM_ SG_ 2618644212 SingleBatteryVoltage087 "#87 single power storage battery voltage

single power storage battery voltage";
CM_ SG_ 2618644212 SingleBatteryGroup086 "#86 single power storage battery voltage

battery grouping No.";
CM_ SG_ 2618644212 SingleBatteryVoltage086 "#86 single power storage battery voltage

single power storage battery voltage";
CM_ SG_ 2618644212 SingleBatteryGroup085 "#85 single power storage battery voltage

battery grouping No.";
CM_ SG_ 2618644212 SingleBatteryVoltage085 "#85 single power storage battery voltage

single power storage battery voltage";
CM_ SG_ 2618644212 SingleBatteryGroup084 "#84 single power storage battery voltage

battery grouping No.";
CM_ SG_ 2618644212 SingleBatteryVoltage084 "#84 single power storage battery voltage

single power storage battery voltage";
CM_ SG_ 2618644212 SingleBatteryGroup083 "#83 single power storage battery voltage

battery grouping No.";
CM_ SG_ 2618644212 SingleBatteryVoltage083 "#83 single power storage battery voltage

single power storage battery voltage";
CM_ SG_ 2618644212 SingleBatteryGroup082 "#82 single power storage battery voltage

battery grouping No.";
CM_ SG_ 2618644212 SingleBatteryVoltage082 "#82 single power storage battery voltage

single power storage battery voltage";
CM_ SG_ 2618644212 SingleBatteryGroup081 "#81 single power storage battery voltage

battery grouping No.";
CM_ SG_ 2618644212 SingleBatteryVoltage081 "#81 single power storage battery voltage

single power storage battery voltage";
CM_ SG_ 2618644212 SingleBatteryGroup080 "#80 single power storage battery voltage

battery grouping No.";
CM_ SG_ 2618644212 SingleBatteryVoltage080 "#80 single power storage battery voltage

single power storage battery voltage";
CM_ SG_ 2618644212 SingleBatteryGroup079 "#79 single power storage battery voltage

battery grouping No.";
CM_ SG_ 2618644212 SingleBatteryVoltage079 "#79 single power storage battery voltage

single power storage battery voltage";
CM_ SG_ 2618644212 SingleBatteryGroup078 "#78 single power storage battery voltage

battery grouping No.";
CM_ SG_ 2618644212 SingleBatteryVoltage078 "#78 single power storage battery voltage

single power storage battery voltage";
CM_ SG_ 2618644212 SingleBatteryGroup077 "#77 single power storage battery voltage

battery grouping No.";
CM_ SG_ 2618644212 SingleBatteryVoltage077 "#77 single power storage battery voltage

single power storage battery voltage";
CM_ SG_ 2618644212 SingleBatteryGroup076 "#76 single power storage battery voltage

battery grouping No.";
CM_ SG_ 2618644212 SingleBatteryVoltage076 "#76 single power storage battery voltage

single power storage battery voltage";
CM_ SG_ 2618644212 SingleBatteryGroup075 "#75 single power storage battery voltage

battery grouping No.";
CM_ SG_ 2618644212 SingleBatteryVoltage075 "#75 single power storage battery voltage

single power storage battery voltage";
CM_ SG_ 2618644212 SingleBatteryGroup074 "#74 single power storage battery voltage

battery grouping No.";
CM_ SG_ 2618644212 SingleBatteryVoltage074 "#74 single power storage battery voltage

single power storage battery voltage";
CM_ SG_ 2618644212 SingleBatteryGroup073 "#73 single power storage battery voltage

battery grouping No.";
CM_ SG_ 2618644212 SingleBatteryVoltage073 "#73 single power storage battery voltage

single power storage battery voltage";
CM_ SG_ 2618644212 SingleBatteryGroup072 "#72 single power storage battery voltage

battery grouping No.";
CM_ SG_ 2618644212 SingleBatteryVoltage072 "#72 single power storage battery voltage

single power storage battery voltage";
CM_ SG_ 2618644212 SingleBatteryGroup071 "#71 single power storage battery voltage

battery grouping No.";
CM_ SG_ 2618644212 SingleBatteryVoltage071 "#71 single power storage battery voltage

single power storage battery voltage";
CM_ SG_ 2618644212 SingleBatteryGroup070 "#70 single power storage battery voltage

battery grouping No.";
CM_ SG_ 2618644212 SingleBatteryVoltage070 "#70 single power storage battery voltage

single power storage battery voltage";
CM_ SG_ 2618644212 SingleBatteryGroup069 "#69 single power storage battery voltage

battery grouping No.";
CM_ SG_ 2618644212 SingleBatteryVoltage069 "#69 single power storage battery voltage

single power storage battery voltage";
CM_ SG_ 2618644212 SingleBatteryGroup068 "#68 single power storage battery voltage

battery grouping No.";
CM_ SG_ 2618644212 SingleBatteryVoltage068 "#68 single power storage battery voltage

single power storage battery voltage";
CM_ SG_ 2618644212 SingleBatteryGroup067 "#67 single power storage battery voltage

battery grouping No.";
CM_ SG_ 2618644212 SingleBatteryVoltage067 "#67 single power storage battery voltage

single power storage battery voltage";
CM_ SG_ 2618644212 SingleBatteryGroup066 "#66 single power storage battery voltage

battery grouping No.";
CM_ SG_ 2618644212 SingleBatteryVoltage066 "#66 single power storage battery voltage

single power storage battery voltage";
CM_ SG_ 2618644212 SingleBatteryGroup065 "#65 single power storage battery voltage

battery grouping No.";
CM_ SG_ 2618644212 SingleBatteryVoltage065 "#65 single power storage battery voltage

single power storage battery voltage";
CM_ SG_ 2618644212 SingleBatteryGroup064 "#64 single power storage battery voltage

battery grouping No.";
CM_ SG_ 2618644212 SingleBatteryVoltage064 "#64 single power storage battery voltage

single power storage battery voltage";
CM_ SG_ 2618644212 SingleBatteryGroup063 "#63 single power storage battery voltage

battery grouping No.";
CM_ SG_ 2618644212 SingleBatteryVoltage063 "#63 single power storage battery voltage

single power storage battery voltage";
CM_ SG_ 2618644212 SingleBatteryGroup062 "#62 single power storage battery voltage

battery grouping No.";
CM_ SG_ 2618644212 SingleBatteryVoltage062 "#62 single power storage battery voltage

single power storage battery voltage";
CM_ SG_ 2618644212 SingleBatteryGroup061 "#61 single power storage battery voltage

battery grouping No.";
CM_ SG_ 2618644212 SingleBatteryVoltage061 "#61 single power storage battery voltage

single power storage battery voltage";
CM_ SG_ 2618644212 SingleBatteryGroup060 "#60 single power storage battery voltage

battery grouping No.";
CM_ SG_ 2618644212 SingleBatteryVoltage060 "#60 single power storage battery voltage

single power storage battery voltage";
CM_ SG_ 2618644212 SingleBatteryGroup059 "#59 single power storage battery voltage

battery grouping No.";
CM_ SG_ 2618644212 SingleBatteryVoltage059 "#59 single power storage battery voltage

single power storage battery voltage";
CM_ SG_ 2618644212 SingleBatteryGroup058 "#58 single power storage battery voltage

battery grouping No.";
CM_ SG_ 2618644212 SingleBatteryVoltage058 "#58 single power storage battery voltage

single power storage battery voltage";
CM_ SG_ 2618644212 SingleBatteryGroup057 "#57 single power storage battery voltage

battery grouping No.";
CM_ SG_ 2618644212 SingleBatteryVoltage057 "#57 single power storage battery voltage

single power storage battery voltage";
CM_ SG_ 2618644212 SingleBatteryGroup056 "#56 single power storage battery voltage

battery grouping No.";
CM_ SG_ 2618644212 SingleBatteryVoltage056 "#56 single power storage battery voltage

single power storage battery voltage";
CM_ SG_ 2618644212 SingleBatteryGroup055 "#55 single power storage battery voltage

battery grouping No.";
CM_ SG_ 2618644212 SingleBatteryVoltage055 "#55 single power storage battery voltage

single power storage battery voltage";
CM_ SG_ 2618644212 SingleBatteryGroup054 "#54 single power storage battery voltage

battery grouping No.";
CM_ SG_ 2618644212 SingleBatteryVoltage054 "#54 single power storage battery voltage

single power storage battery voltage";
CM_ SG_ 2618644212 SingleBatteryGroup053 "#53 single power storage battery voltage

battery grouping No.";
CM_ SG_ 2618644212 SingleBatteryVoltage053 "#53 single power storage battery voltage

single power storage battery voltage";
CM_ SG_ 2618644212 SingleBatteryGroup052 "#52 single power storage battery voltage

battery grouping No.";
CM_ SG_ 2618644212 SingleBatteryVoltage052 "#52 single power storage battery voltage

single power storage battery voltage";
CM_ SG_ 2618644212 SingleBatteryGroup051 "#51 single power storage battery voltage

battery grouping No.";
CM_ SG_ 2618644212 SingleBatteryVoltage051 "#51 single power storage battery voltage

single power storage battery voltage";
CM_ SG_ 2618644212 SingleBatteryGroup050 "#50 single power storage battery voltage

battery grouping No.";
CM_ SG_ 2618644212 SingleBatteryVoltage050 "#50 single power storage battery voltage

single power storage battery voltage";
CM_ SG_ 2618644212 SingleBatteryGroup049 "#49 single power storage battery voltage

battery grouping No.";
CM_ SG_ 2618644212 SingleBatteryVoltage049 "#49 single power storage battery voltage

single power storage battery voltage";
CM_ SG_ 2618644212 SingleBatteryGroup048 "#48 single power storage battery voltage

battery grouping No.";
CM_ SG_ 2618644212 SingleBatteryVoltage048 "#48 single power storage battery voltage

single power storage battery voltage";
CM_ SG_ 2618644212 SingleBatteryGroup047 "#47 single power storage battery voltage

battery grouping No.";
CM_ SG_ 2618644212 SingleBatteryVoltage047 "#47 single power storage battery voltage

single power storage battery voltage";
CM_ SG_ 2618644212 SingleBatteryGroup046 "#46 single power storage battery voltage

battery grouping No.";
CM_ SG_ 2618644212 SingleBatteryVoltage046 "#46 single power storage battery voltage

single power storage battery voltage";
CM_ SG_ 2618644212 SingleBatteryGroup045 "#45 single power storage battery voltage

battery grouping No.";
CM_ SG_ 2618644212 SingleBatteryVoltage045 "#45 single power storage battery voltage

single power storage battery voltage";
CM_ SG_ 2618644212 SingleBatteryGroup044 "#44 single power storage battery voltage

battery grouping No.";
CM_ SG_ 2618644212 SingleBatteryVoltage044 "#44 single power storage battery voltage

single power storage battery voltage";
CM_ SG_ 2618644212 SingleBatteryGroup043 "#43 single power storage battery voltage

battery grouping No.";
CM_ SG_ 2618644212 SingleBatteryVoltage043 "#43 single power storage battery voltage

single power storage battery voltage";
CM_ SG_ 2618644212 SingleBatteryGroup042 "#42 single power storage battery voltage

battery grouping No.";
CM_ SG_ 2618644212 SingleBatteryVoltage042 "#42 single power storage battery voltage

single power storage battery voltage";
CM_ SG_ 2618644212 SingleBatteryGroup041 "#41 single power storage battery voltage

battery grouping No.";
CM_ SG_ 2618644212 SingleBatteryVoltage041 "#41 single power storage battery voltage

single power storage battery voltage";
CM_ SG_ 2618644212 SingleBatteryGroup040 "#40 single power storage battery voltage

battery grouping No.";
CM_ SG_ 2618644212 SingleBatteryVoltage040 "#40 single power storage battery voltage

single power storage battery voltage";
CM_ SG_ 2618644212 SingleBatteryGroup039 "#39 single power storage battery voltage

battery grouping No.";
CM_ SG_ 2618644212 SingleBatteryVoltage039 "#39 single power storage battery voltage

single power storage battery voltage";
CM_ SG_ 2618644212 SingleBatteryGroup038 "#38 single power storage battery voltage

battery grouping No.";
CM_ SG_ 2618644212 SingleBatteryVoltage038 "#38 single power storage battery voltage

single power storage battery voltage";
CM_ SG_ 2618644212 SingleBatteryGroup037 "#37 single power storage battery voltage

battery grouping No.";
CM_ SG_ 2618644212 SingleBatteryVoltage037 "#37 single power storage battery voltage

single power storage battery voltage";
CM_ SG_ 2618644212 SingleBatteryGroup036 "#36 single power storage battery voltage

battery grouping No.";
CM_ SG_ 2618644212 SingleBatteryVoltage036 "#36 single power storage battery voltage

single power storage battery voltage";
CM_ SG_ 2618644212 SingleBatteryGroup035 "#35 single power storage battery voltage

battery grouping No.";
CM_ SG_ 2618644212 SingleBatteryVoltage035 "#35 single power storage battery voltage

single power storage battery voltage";
CM_ SG_ 2618644212 SingleBatteryGroup034 "#34 single power storage battery voltage

battery grouping No.";
CM_ SG_ 2618644212 SingleBatteryVoltage034 "#34 single power storage battery voltage

single power storage battery voltage";
CM_ SG_ 2618644212 SingleBatteryGroup033 "#33 single power storage battery voltage

battery grouping No.";
CM_ SG_ 2618644212 SingleBatteryVoltage033 "#33 single power storage battery voltage

single power storage battery voltage";
CM_ SG_ 2618644212 SingleBatteryGroup032 "#32 single power storage battery voltage

battery grouping No.";
CM_ SG_ 2618644212 SingleBatteryVoltage032 "#32 single power storage battery voltage

single power storage battery voltage";
CM_ SG_ 2618644212 SingleBatteryGroup031 "#31 single power storage battery voltage

battery grouping No.";
CM_ SG_ 2618644212 SingleBatteryVoltage031 "#31 single power storage battery voltage

single power storage battery voltage";
CM_ SG_ 2618644212 SingleBatteryGroup030 "#30 single power storage battery voltage

battery grouping No.";
CM_ SG_ 2618644212 SingleBatteryVoltage030 "#30 single power storage battery voltage

single power storage battery voltage";
CM_ SG_ 2618644212 SingleBatteryGroup029 "#29 single power storage battery voltage

battery grouping No.";
CM_ SG_ 2618644212 SingleBatteryVoltage029 "#29 single power storage battery voltage

single power storage battery voltage";
CM_ SG_ 2618644212 SingleBatteryGroup028 "#28 single power storage battery voltage

battery grouping No.";
CM_ SG_ 2618644212 SingleBatteryVoltage028 "#28 single power storage battery voltage

single power storage battery voltage";
CM_ SG_ 2618644212 SingleBatteryGroup027 "#27 single power storage battery voltage

battery grouping No.";
CM_ SG_ 2618644212 SingleBatteryVoltage027 "#27 single power storage battery voltage

single power storage battery voltage";
CM_ SG_ 2618644212 SingleBatteryGroup026 "#26 single power storage battery voltage

battery grouping No.";
CM_ SG_ 2618644212 SingleBatteryVoltage026 "#26 single power storage battery voltage

single power storage battery voltage";
CM_ SG_ 2618644212 SingleBatteryGroup025 "#25 single power storage battery voltage

battery grouping No.";
CM_ SG_ 2618644212 SingleBatteryVoltage025 "#25 single power storage battery voltage

single power storage battery voltage";
CM_ SG_ 2618644212 SingleBatteryGroup024 "#24 single power storage battery voltage

battery grouping No.";
CM_ SG_ 2618644212 SingleBatteryVoltage024 "#24 single power storage battery voltage

single power storage battery voltage";
CM_ SG_ 2618644212 SingleBatteryGroup023 "#23 single power storage battery voltage

battery grouping No.";
CM_ SG_ 2618644212 SingleBatteryVoltage023 "#23 single power storage battery voltage

single power storage battery voltage";
CM_ SG_ 2618644212 SingleBatteryGroup022 "#22 single power storage battery voltage

battery grouping No.";
CM_ SG_ 2618644212 SingleBatteryVoltage022 "#22 single power storage battery voltage

single power storage battery voltage";
CM_ SG_ 2618644212 SingleBatteryGroup021 "#21 single power storage battery voltage

battery grouping No.";
CM_ SG_ 2618644212 SingleBatteryVoltage021 "#21 single power storage battery voltage

single power storage battery voltage";
CM_ SG_ 2618644212 SingleBatteryGroup020 "#20 single power storage battery voltage

battery grouping No.";
CM_ SG_ 2618644212 SingleBatteryVoltage020 "#20 single power storage battery voltage

single power storage battery voltage";
CM_ SG_ 2618644212 SingleBatteryGroup019 "#19 single power storage battery voltage

battery grouping No.";
CM_ SG_ 2618644212 SingleBatteryVoltage019 "#19 single power storage battery voltage

single power storage battery voltage";
CM_ SG_ 2618644212 SingleBatteryGroup018 "#18 single power storage battery voltage

battery grouping No.";
CM_ SG_ 2618644212 SingleBatteryVoltage018 "#18 single power storage battery voltage

single power storage battery voltage";
CM_ SG_ 2618644212 SingleBatteryGroup017 "#17 single power storage battery voltage

battery grouping No.";
CM_ SG_ 2618644212 SingleBatteryVoltage017 "#17 single power storage battery voltage

single power storage battery voltage";
CM_ SG_ 2618644212 SingleBatteryGroup016 "#16 single power storage battery voltage

battery grouping No.";
CM_ SG_ 2618644212 SingleBatteryVoltage016 "#16 single power storage battery voltage

single power storage battery voltage";
CM_ SG_ 2618644212 SingleBatteryGroup015 "#15 single power storage battery voltage

battery grouping No.";
CM_ SG_ 2618644212 SingleBatteryVoltage015 "#15 single power storage battery voltage

single power storage battery voltage";
CM_ SG_ 2618644212 SingleBatteryGroup014 "#14 single power storage battery voltage

battery grouping No.";
CM_ SG_ 2618644212 SingleBatteryVoltage014 "#14 single power storage battery voltage

single power storage battery voltage";
CM_ SG_ 2618644212 SingleBatteryGroup013 "#13 single power storage battery voltage

battery grouping No.";
CM_ SG_ 2618644212 SingleBatteryVoltage013 "#13 single power storage battery voltage

single power storage battery voltage";
CM_ SG_ 2618644212 SingleBatteryGroup012 "#12 single power storage battery voltage

battery grouping No.";
CM_ SG_ 2618644212 SingleBatteryVoltage012 "#12 single power storage battery voltage

single power storage battery voltage";
CM_ SG_ 2618644212 SingleBatteryGroup011 "#11 single power storage battery voltage

battery grouping No.";
CM_ SG_ 2618644212 SingleBatteryVoltage011 "#11 single power storage battery voltage

single power storage battery voltage";
CM_ SG_ 2618644212 SingleBatteryGroup010 "#10 single power storage battery voltage

battery grouping No.";
CM_ SG_ 2618644212 SingleBatteryVoltage010 "#10 single power storage battery voltage

single power storage battery voltage";
CM_ SG_ 2618644212 SingleBatteryGroup009 "#9 single power storage battery voltage

battery grouping No.";
CM_ SG_ 2618644212 SingleBatteryVoltage009 "#9 single power storage battery voltage

single power storage battery voltage";
CM_ SG_ 2618644212 SingleBatteryGroup008 "#8 single power storage battery voltage

battery grouping No.";
CM_ SG_ 2618644212 SingleBatteryVoltage008 "#8 single power storage battery voltage

single power storage battery voltage";
CM_ SG_ 2618644212 SingleBatteryGroup007 "#7 single power storage battery voltage

battery grouping No.";
CM_ SG_ 2618644212 SingleBatteryVoltage007 "#7 single power storage battery voltage

single power storage battery voltage";
CM_ SG_ 2618644212 SingleBatteryGroup006 "#6 single power storage battery voltage

battery grouping No.";
CM_ SG_ 2618644212 SingleBatteryVoltage006 "#6 single power storage battery voltage

single power storage battery voltage";
CM_ SG_ 2618644212 SingleBatteryGroup005 "#5 single power storage battery voltage

battery grouping No.";
CM_ SG_ 2618644212 SingleBatteryVoltage005 "#5 single power storage battery voltage

single power storage battery voltage";
CM_ SG_ 2618644212 SingleBatteryGroup004 "#4 single power storage battery voltage

battery grouping No.";
CM_ SG_ 2618644212 SingleBatteryVoltage004 "#4 single power storage battery voltage

single power storage battery voltage";
CM_ SG_ 2618644212 SingleBatteryGroup003 "#3 single power storage battery voltage

battery grouping No.";
CM_ SG_ 2618644212 SingleBatteryVoltage003 "#3 single power storage battery voltage

single power storage battery voltage";
CM_ SG_ 2618644212 SingleBatteryGroup002 "#2 single power storage battery voltage

battery grouping No.";
CM_ SG_ 2618644212 SingleBatteryVoltage002 "#2 single power storage battery voltage

single power storage battery voltage";
CM_ SG_ 2618644212 SingleBatteryGroup001 "#1 single power storage battery voltage

battery grouping No.";
CM_ SG_ 2618644212 SingleBatteryVoltage001 "#1 single power storage battery voltage

single power storage battery voltage";
CM_ BO_ 2551404276 "[Charging] Power storage battery status information";
CM_ SG_ 2551404276 ChargingPermissible "Charging permissible";
CM_ SG_ 2551404276 BatteryOutputConnectorState "Connection state of output connector of power storage battery set";
CM_ SG_ 2551404276 BatteryInsulationState "Insulation state of power storage battery";
CM_ SG_ 2551404276 BatteryExcessTemperature "Excess temperature of power storage battery";
CM_ SG_ 2551404276 BatteryChargingOvercurrent "Charging overcurrent of power storage battery";
CM_ SG_ 2551404276 StateOfCharge "State-of-charge SOC of power storage battery for complete vehicle";
CM_ SG_ 2551404276 BatteryCellVoltageState "Voltage state of battery cell";
CM_ SG_ 2551404276 BatteryLowestTempSerNo "Serial number of the lowest temperature detection point of power storage battery";
CM_ SG_ 2551404276 BatteryLowestTemp "The lowest temperature of power storage battery";
CM_ SG_ 2551404276 BatteryHighestTempSerNo "Serial number of the highest temperature detection point";
CM_ SG_ 2551404276 BatteryHighestTemp "Highest temperature of power storage battery";
CM_ SG_ 2551404276 SingleBatteryHighestVoltageSerNo "Serial number of the highest voltage of single power storage battery";
CM_ BO_ 2551379030 "[Charging] Charger's charging status";
CM_ SG_ 2551379030 ChargingPermissible "Charging permissible";
CM_ SG_ 2551379030 CumulativeChargingTime "Cumulative charging time (min)";
CM_ SG_ 2551379030 CurrentOutputValue "Current output value (A)";
CM_ SG_ 2551379030 VoltageOutputValue "Voltage output value (V)";
CM_ BO_ 2618382068 "[Charging] Overall battery charging status";
CM_ SG_ 2618382068 EstimatedRemainingChargingTime "Estimated remaining charging time (min)";
CM_ SG_ 2618382068 CurrentChargeState "Current state-of-charge SOC (%)";
CM_ SG_ 2618382068 GroupNrOfCellWithHighestVoltage "Group number in which the highest voltage of single power storage battery is located";
CM_ SG_ 2618382068 HighestVoltageOfBatteryCell "Voltage of maximum single power storage battery";
CM_ SG_ 2618382068 MeasuredChargingCurrent "Measured value of charging current (A)";
CM_ SG_ 2618382068 MeasuredChargingVoltage "Measured value of charging voltage (V)";
CM_ BO_ 2551207668 "[Charging] Battery charging demand";
CM_ SG_ 2551207668 ChargingMode "Charging mode (0x01: constant voltage charge; 0x02: constant current charge)";
CM_ SG_ 2551207668 CurrentDemand "Current demand (A)";
CM_ SG_ 2551207668 VoltageDemand "Voltage demand (V)";
CM_ BO_ 2416637014 "[Parameter Configuration] Charger output ready state";
CM_ SG_ 2416637014 ChargerReadyForCharging "Whether charger is ready for charging";
CM_ BO_ 2416531188 "[Parameter Configuration] Battery charging ready state";
CM_ SG_ 2416531188 BmsReadyForCharging "Whether BMS is ready for charging ";
CM_ BO_ 2550723670 "[Parameter Configuration] Charger's maximum output";
CM_ SG_ 2550723670 MinOutputCurrent "Minimum output current (A)";
CM_ SG_ 2550723670 MaxOutputCurrent "Maximum output current (A)";
CM_ SG_ 2550723670 MinOutputVoltage "Minimum output voltage (V)";
CM_ SG_ 2550723670 MaxOutputVoltage "Maximum output voltage (V)";
CM_ BO_ 2550658134 "[Parameter Configuration] Charger send-time synchronization information
1. byte: second; 2. byte: minute; 3. byte: hour; 4. byte: day; 5. byte: month; 6. and 7. bytes: year.
All values as compressed BCD code. ";
CM_ BO_ 2617661172 "[Parameter Configuration] Charging parameters of power storage battery";
CM_ SG_ 2617661172 CurrentBatteryVoltage "Current battery voltage of power storage battery for complete vehicle";
CM_ SG_ 2617661172 StatusOfCharge "Status-of-charge of power storage battery for complete vehicle";
CM_ SG_ 2617661172 MaxPermTemperature "Maximum permissible temperature";
CM_ SG_ 2617661172 TotalMaxPermChargingVoltage "Total maximum permissible charging voltage";
CM_ SG_ 2617661172 TotalNominalEnergy "Total nominal energy of power storage battery";
CM_ SG_ 2617661172 MaxPermChargingCurrent "Maximum permissible charging current";
CM_ SG_ 2617661172 MaxBattCellChargingVoltage "Maximum permissible charging voltage of battery cell";
CM_ BO_ 2617399028 "[Handshake Recognition] BMS and vehicle recognition message";
CM_ SG_ 2617399028 BmsSoftwareVersion_Reserved "BMS software version number 8byte represents current BMS version information, determined according to hexadecimal coding. In which, Byte8, byte7, byte6-000001H~FFFFFEH, reserved, fill in FFFFFFH";
CM_ SG_ 2617399028 BmsSoftwareVersion_CompileYear "BMS software version number, determined according to hexadecimal coding. In which, Byte5, Byte4 - 0001H~FFFEH represents compilation year (e.g. the year of 2015: fill in Byte5-DFH, byte4-07H)";
CM_ SG_ 2617399028 BmsSoftwareVersion_CompileMonth "BMS software version number, determined according to hexadecimal coding. In which, Byte3 - 01H~0CH represents compilation month (e.g. November: fill in Byte 3 0BH)";
CM_ SG_ 2617399028 BmsSoftwareVersion_CompileDay "BMS software version number, determined according to hexadecimal coding. In which, Byte2 - 01H~1FH represents compilation day (e.g. the 10the day: fill in Byte 2 0AH)";
CM_ SG_ 2617399028 BmsSoftwareVersion_Serial "BMS software version number, determined according to hexadecimal coding. In which, Byte1 - 01H~FEH represents edition serial number (e.g. 16: fill in Byte 1-10H)";
CM_ SG_ 2617399028 BRM_Reserved1 "Reserved";
CM_ SG_ 2617399028 VIN "Vehicle identification number (VIN)";
CM_ SG_ 2617399028 Property "Battery set property right mark";
CM_ SG_ 2617399028 ChargingFrequency "Battery set charging frequency, which is subject to BMS statistics.";
CM_ SG_ 2617399028 ProductionDay "Battery set production day";
CM_ SG_ 2617399028 ProductionMonth "Battery set production month";
CM_ SG_ 2617399028 ProductionYear "Battery set production year";
CM_ SG_ 2617399028 BatteryPackNumber "Battery pack No., which is reserved and will be defined by the manufacturer";
CM_ SG_ 2617399028 ManufacturerName "Battery manufacturer name";
CM_ SG_ 2617399028 BatterySystemVoltage "Total voltage of the power storage battery system of whole vehicle";
CM_ SG_ 2617399028 BatterySystemCapacity "Capacity of the power storage battery system of whole vehicle";
CM_ SG_ 2617399028 BmsVersion "In this standard, as for the charger communication protocol version No., its current version is specified as V1.1 and is expressed as: byte3, byte2 -- 0001H";
CM_ SG_ 2617399028 BmsRevision "In this standard, as for the charger communication protocol version No., its current version is specified as V1.1 and is expressed as: byte 1 -- 01H";
CM_ SG_ 2617399028 BatteryType "Battery type";
CM_ BO_ 2550264918 "[Handshake Recognition] Charger recognition";
CM_ SG_ 2550264918 ChargerLocation "Charger/charging station location code";
CM_ SG_ 2550264918 ChargerNumber "Charger Number";
CM_ SG_ 2550264918 RecognitionResult "Recognition  result";
CM_ BO_ 2552714996 "[Handshake Initiation] Vehicle handshake";
CM_ SG_ 2552714996 MaxChargingVoltage "Total maximum permissible charging voltage";
CM_ BO_ 2552689750 "[Handshake Initiation] Charger handshake";
CM_ BO_ 2565603070 "Transport Protocol - Data Transfer
Used for the transfer of data associated with Parameter Groups that have more than 8 bytes of data.";
CM_ SG_ 2565603070 SequenceNumber "Sequence Number (TP.DT)";
CM_ BO_ 2565668606 "Transport Protocol - Connection Mgmt
Used for the transfer of Parameter Groups that have 9 or more bytes of data.";
CM_ SG_ 2565668606 TotalNumberOfPacketsEoMA "Total number of packets received for RTS/CTS message.  Zero and one are not valid values.";
CM_ SG_ 2565668606 TotalMessageSizeEoMA "Total message size (in bytes) received for RTS/CTS message.  Messages shorter than 9 data bytes should be sent without utilizing the transport protocol.  Messages longer than 1785 can not use the RTS/CTS transport protocol.";
CM_ SG_ 2565668606 TotalMessageSizeBAM "Total message size (in bytes) for BAM  message.  Messages shorter than 9 data bytes should be sent without utilizing the transport protocol.  Messages longer than 1785 can not use the BAM transport protocol.";
CM_ SG_ 2565668606 TotalNumberOfPacketsBAM "Total number of packets for BAM message.  Zero and one are not valid values.";
CM_ SG_ 2565668606 ConnectionAbortReason "Reason for connection abort message.
1 Already in one or more connection managed sessions and cannot support another.
2 System resources were needed for another task so this connection managed session was terminated.
3 A timeout occurred and this ...";
CM_ SG_ 2565668606 NextPacketNumberToBeSent "Next Packet Number to be sent (TP.CM_CTS)";
CM_ SG_ 2565668606 NumberOfPacketsThatCanBeSent "Number of Packets that can be sent (TP.CM_CTS)";
CM_ SG_ 2565668606 PGNumber "Requested PGN in the TP.CM_RTS message";
CM_ SG_ 2565668606 MaximumNumberOfPackets "Maximum number of packets for RTS/CTS message.  zero through four are not allowed";
CM_ SG_ 2565668606 TotalNumberOfPackets "Total number of packets for RTS/CTS message.  Zero and one are not valid values.";
CM_ SG_ 2565668606 TotalMessageSize "Total message size (in bytes) for RTS/CTS message. 
Messages shorter than 9 data bytes should be sent without utilizing the transport protocol.  Messages longer than 1785 can not use the RTS/CTS transport protocol.";
CM_ SG_ 2565668606 ControlByte "Control byte (I.e. Group Function) associated with the Transport Protocol - Connection Management (PGN 60,416)
16 (dec) - Request to Send
17 (dec) - Clear to Send
19 (dec) - End of Message ACK
32 (dec) - Broadcast Announce Message
255 (dec) - ...";
CM_ BO_ 2565537534 "Request
This message type, identified by the PGN, provides the capability to request information globally or from a specific destination.";
CM_ SG_ 2565537534 ParameterGroupNumber "Whenever it is necessary to identify a Parameter Group in the data field of a CAN data frame, it will be expressed in 24 bits.  The Parameter Group Number is a 24 bit value that has the following constituent components:  Reserved bit, Data Page bit, ...";
CM_ BO_ 2565406462 "Acknowledgment Message
The Acknowledgment PG is used to provide a handshake mechanism between transmitting and receiving devices.";
CM_ SG_ 2565406462 ControlByte "Indicates the acknowledgement response.
0 - Positive Acknowledgment (ACK)
1 - Negative Acknowledgment (NACK)
2 - Access Denied (PGN supported but access denied)
3 - Cannot Respond (PGN supported but ECU cannot respond now) cannot respond with ...";
CM_ SG_ 2565406462 ParameterGroupNumber "PGN which is requested by the Request message";
CM_ SG_ 2565406462 GroupFunctionValue "Group Function of PGN being acknowledged. This field identifies for a device the specific group function of a PGN being acknowledged or declined.  This field is not used if the PGN being acknowledged or declined is not a group function PGN.";
BA_DEF_ SG_  "SigType" ENUM  "Default","Range","RangeSigned","ASCII","Discrete","Control","ReferencePGN","DTC","StringDelimiter","StringLength","StringLengthControl","MessageCounter","MessageChecksum";
BA_DEF_ SG_  "GenSigStartValue" INT 0 2147483647;
BA_DEF_ SG_  "GenSigSendType" ENUM  "Cyclic","OnWrite","OnWriteWithRepetition","OnChange","OnChangeWithRepetition","IfActive","IfActiveWithRepetition","NoSigSendType";
BA_DEF_ SG_  "GenSigILSupport" ENUM  "No","Yes";
BA_DEF_ SG_  "GenSigEVName" STRING ;
BA_DEF_ SG_  "SPN" INT 0 524287;
BA_DEF_ BO_  "TpJ1939VarDlc" ENUM  "No","Yes";
BA_DEF_ BO_  "GenMsgILSupport" ENUM  "No","Yes";
BA_DEF_ BO_  "GenMsgRequestable" INT 0 1;
BA_DEF_ BO_  "GenMsgSendType" ENUM  "cyclic","NotUsed","NotUsed","NotUsed","NotUsed","NotUsed","NotUsed","IfActive","noMsgSendType";
BA_DEF_ BO_  "VFrameFormat" ENUM  "StandardCAN","ExtendedCAN","reserved","J1939PG";
BA_DEF_ BO_  "GenMsgCycleTime" INT 0 3600000;
BA_DEF_DEF_  "SigType" "Default";
BA_DEF_DEF_  "GenSigStartValue" 0;
BA_DEF_DEF_  "GenSigSendType" "NoSigSendType";
BA_DEF_DEF_  "GenSigILSupport" "Yes";
BA_DEF_DEF_  "GenSigEVName" "Env@Nodename_@Signame";
BA_DEF_DEF_  "SPN" 0;
BA_DEF_DEF_  "TpJ1939VarDlc" "No";
BA_DEF_DEF_  "GenMsgILSupport" "Yes";
BA_DEF_DEF_  "GenMsgRequestable" 1;
BA_DEF_DEF_  "GenMsgSendType" "noMsgSendType";
BA_DEF_DEF_  "VFrameFormat" "J1939PG";
BA_DEF_DEF_  "GenMsgCycleTime" 0;
BA_ "TpJ1939VarDlc" BO_ 2618644212 1;
BA_ "GenMsgCycleTime" BO_ 2618644212 10000;
BA_ "GenMsgSendType" BO_ 2618644212 0;
BA_ "GenMsgRequestable" BO_ 2618644212 0;
BA_ "GenMsgILSupport" BO_ 2618644212 0;
BA_ "GenMsgCycleTime" BO_ 2551404276 250;
BA_ "GenMsgSendType" BO_ 2551404276 0;
BA_ "GenMsgRequestable" BO_ 2551404276 0;
BA_ "GenMsgCycleTime" BO_ 2551379030 50;
BA_ "GenMsgSendType" BO_ 2551379030 0;
BA_ "GenMsgRequestable" BO_ 2551379030 0;
BA_ "GenMsgCycleTime" BO_ 2618382068 250;
BA_ "GenMsgSendType" BO_ 2618382068 0;
BA_ "GenMsgRequestable" BO_ 2618382068 0;
BA_ "GenMsgCycleTime" BO_ 2551207668 50;
BA_ "GenMsgSendType" BO_ 2551207668 0;
BA_ "GenMsgRequestable" BO_ 2551207668 0;
BA_ "GenMsgCycleTime" BO_ 2416637014 250;
BA_ "GenMsgSendType" BO_ 2416637014 0;
BA_ "GenMsgRequestable" BO_ 2416637014 0;
BA_ "GenMsgCycleTime" BO_ 2416531188 250;
BA_ "GenMsgSendType" BO_ 2416531188 0;
BA_ "GenMsgRequestable" BO_ 2416531188 0;
BA_ "GenMsgCycleTime" BO_ 2550723670 250;
BA_ "GenMsgSendType" BO_ 2550723670 0;
BA_ "GenMsgRequestable" BO_ 2550723670 0;
BA_ "GenMsgCycleTime" BO_ 2550658134 500;
BA_ "GenMsgSendType" BO_ 2550658134 0;
BA_ "GenMsgRequestable" BO_ 2550658134 0;
BA_ "GenMsgCycleTime" BO_ 2617661172 500;
BA_ "GenMsgSendType" BO_ 2617661172 0;
BA_ "GenMsgRequestable" BO_ 2617661172 0;
BA_ "TpJ1939VarDlc" BO_ 2617399028 1;
BA_ "GenMsgCycleTime" BO_ 2617399028 250;
BA_ "GenMsgSendType" BO_ 2617399028 0;
BA_ "GenMsgRequestable" BO_ 2617399028 0;
BA_ "GenMsgCycleTime" BO_ 2550264918 250;
BA_ "GenMsgSendType" BO_ 2550264918 0;
BA_ "GenMsgRequestable" BO_ 2550264918 0;
BA_ "GenMsgCycleTime" BO_ 2552714996 250;
BA_ "GenMsgSendType" BO_ 2552714996 0;
BA_ "GenMsgRequestable" BO_ 2552714996 0;
BA_ "GenMsgCycleTime" BO_ 2552689750 250;
BA_ "GenMsgSendType" BO_ 2552689750 0;
BA_ "GenMsgRequestable" BO_ 2552689750 0;
BA_ "GenMsgILSupport" BO_ 2565603070 0;
BA_ "GenMsgRequestable" BO_ 2565603070 0;
BA_ "GenMsgILSupport" BO_ 2565668606 0;
BA_ "GenMsgRequestable" BO_ 2565668606 0;
BA_ "GenMsgILSupport" BO_ 2565537534 0;
BA_ "GenMsgRequestable" BO_ 2565537534 0;
BA_ "GenMsgILSupport" BO_ 2565406462 0;
BA_ "GenMsgRequestable" BO_ 2565406462 0;
BA_ "SigType" SG_ 2618644212 SingleBatteryGroup256 1;
BA_ "SPN" SG_ 2618644212 SingleBatteryGroup256 3356;
BA_ "SigType" SG_ 2618644212 SingleBatteryVoltage256 1;
BA_ "SPN" SG_ 2618644212 SingleBatteryVoltage256 3356;
BA_ "SigType" SG_ 2618644212 SingleBatteryGroup255 1;
BA_ "SPN" SG_ 2618644212 SingleBatteryGroup255 3355;
BA_ "SigType" SG_ 2618644212 SingleBatteryVoltage255 1;
BA_ "SPN" SG_ 2618644212 SingleBatteryVoltage255 3355;
BA_ "SigType" SG_ 2618644212 SingleBatteryGroup254 1;
BA_ "SPN" SG_ 2618644212 SingleBatteryGroup254 3354;
BA_ "SigType" SG_ 2618644212 SingleBatteryVoltage254 1;
BA_ "SPN" SG_ 2618644212 SingleBatteryVoltage254 3354;
BA_ "SigType" SG_ 2618644212 SingleBatteryGroup253 1;
BA_ "SPN" SG_ 2618644212 SingleBatteryGroup253 3353;
BA_ "SigType" SG_ 2618644212 SingleBatteryVoltage253 1;
BA_ "SPN" SG_ 2618644212 SingleBatteryVoltage253 3353;
BA_ "SigType" SG_ 2618644212 SingleBatteryGroup252 1;
BA_ "SPN" SG_ 2618644212 SingleBatteryGroup252 3352;
BA_ "SigType" SG_ 2618644212 SingleBatteryVoltage252 1;
BA_ "SPN" SG_ 2618644212 SingleBatteryVoltage252 3352;
BA_ "SigType" SG_ 2618644212 SingleBatteryGroup251 1;
BA_ "SPN" SG_ 2618644212 SingleBatteryGroup251 3351;
BA_ "SigType" SG_ 2618644212 SingleBatteryVoltage251 1;
BA_ "SPN" SG_ 2618644212 SingleBatteryVoltage251 3351;
BA_ "SigType" SG_ 2618644212 SingleBatteryGroup250 1;
BA_ "SPN" SG_ 2618644212 SingleBatteryGroup250 3350;
BA_ "SigType" SG_ 2618644212 SingleBatteryVoltage250 1;
BA_ "SPN" SG_ 2618644212 SingleBatteryVoltage250 3350;
BA_ "SigType" SG_ 2618644212 SingleBatteryGroup249 1;
BA_ "SPN" SG_ 2618644212 SingleBatteryGroup249 3349;
BA_ "SigType" SG_ 2618644212 SingleBatteryVoltage249 1;
BA_ "SPN" SG_ 2618644212 SingleBatteryVoltage249 3349;
BA_ "SigType" SG_ 2618644212 SingleBatteryGroup248 1;
BA_ "SPN" SG_ 2618644212 SingleBatteryGroup248 3348;
BA_ "SigType" SG_ 2618644212 SingleBatteryVoltage248 1;
BA_ "SPN" SG_ 2618644212 SingleBatteryVoltage248 3348;
BA_ "SigType" SG_ 2618644212 SingleBatteryGroup247 1;
BA_ "SPN" SG_ 2618644212 SingleBatteryGroup247 3347;
BA_ "SigType" SG_ 2618644212 SingleBatteryVoltage247 1;
BA_ "SPN" SG_ 2618644212 SingleBatteryVoltage247 3347;
BA_ "SigType" SG_ 2618644212 SingleBatteryGroup246 1;
BA_ "SPN" SG_ 2618644212 SingleBatteryGroup246 3346;
BA_ "SigType" SG_ 2618644212 SingleBatteryVoltage246 1;
BA_ "SPN" SG_ 2618644212 SingleBatteryVoltage246 3346;
BA_ "SigType" SG_ 2618644212 SingleBatteryGroup245 1;
BA_ "SPN" SG_ 2618644212 SingleBatteryGroup245 3345;
BA_ "SigType" SG_ 2618644212 SingleBatteryVoltage245 1;
BA_ "SPN" SG_ 2618644212 SingleBatteryVoltage245 3345;
BA_ "SigType" SG_ 2618644212 SingleBatteryGroup244 1;
BA_ "SPN" SG_ 2618644212 SingleBatteryGroup244 3344;
BA_ "SigType" SG_ 2618644212 SingleBatteryVoltage244 1;
BA_ "SPN" SG_ 2618644212 SingleBatteryVoltage244 3344;
BA_ "SigType" SG_ 2618644212 SingleBatteryGroup243 1;
BA_ "SPN" SG_ 2618644212 SingleBatteryGroup243 3343;
BA_ "SigType" SG_ 2618644212 SingleBatteryVoltage243 1;
BA_ "SPN" SG_ 2618644212 SingleBatteryVoltage243 3343;
BA_ "SigType" SG_ 2618644212 SingleBatteryGroup242 1;
BA_ "SPN" SG_ 2618644212 SingleBatteryGroup242 3342;
BA_ "SigType" SG_ 2618644212 SingleBatteryVoltage242 1;
BA_ "SPN" SG_ 2618644212 SingleBatteryVoltage242 3342;
BA_ "SigType" SG_ 2618644212 SingleBatteryGroup241 1;
BA_ "SPN" SG_ 2618644212 SingleBatteryGroup241 3341;
BA_ "SigType" SG_ 2618644212 SingleBatteryVoltage241 1;
BA_ "SPN" SG_ 2618644212 SingleBatteryVoltage241 3341;
BA_ "SigType" SG_ 2618644212 SingleBatteryGroup240 1;
BA_ "SPN" SG_ 2618644212 SingleBatteryGroup240 3340;
BA_ "SigType" SG_ 2618644212 SingleBatteryVoltage240 1;
BA_ "SPN" SG_ 2618644212 SingleBatteryVoltage240 3340;
BA_ "SigType" SG_ 2618644212 SingleBatteryGroup239 1;
BA_ "SPN" SG_ 2618644212 SingleBatteryGroup239 3339;
BA_ "SigType" SG_ 2618644212 SingleBatteryVoltage239 1;
BA_ "SPN" SG_ 2618644212 SingleBatteryVoltage239 3339;
BA_ "SigType" SG_ 2618644212 SingleBatteryGroup238 1;
BA_ "SPN" SG_ 2618644212 SingleBatteryGroup238 3338;
BA_ "SigType" SG_ 2618644212 SingleBatteryVoltage238 1;
BA_ "SPN" SG_ 2618644212 SingleBatteryVoltage238 3338;
BA_ "SigType" SG_ 2618644212 SingleBatteryGroup237 1;
BA_ "SPN" SG_ 2618644212 SingleBatteryGroup237 3337;
BA_ "SigType" SG_ 2618644212 SingleBatteryVoltage237 1;
BA_ "SPN" SG_ 2618644212 SingleBatteryVoltage237 3337;
BA_ "SigType" SG_ 2618644212 SingleBatteryGroup236 1;
BA_ "SPN" SG_ 2618644212 SingleBatteryGroup236 3336;
BA_ "SigType" SG_ 2618644212 SingleBatteryVoltage236 1;
BA_ "SPN" SG_ 2618644212 SingleBatteryVoltage236 3336;
BA_ "SigType" SG_ 2618644212 SingleBatteryGroup235 1;
BA_ "SPN" SG_ 2618644212 SingleBatteryGroup235 3335;
BA_ "SigType" SG_ 2618644212 SingleBatteryVoltage235 1;
BA_ "SPN" SG_ 2618644212 SingleBatteryVoltage235 3335;
BA_ "SigType" SG_ 2618644212 SingleBatteryGroup234 1;
BA_ "SPN" SG_ 2618644212 SingleBatteryGroup234 3334;
BA_ "SigType" SG_ 2618644212 SingleBatteryVoltage234 1;
BA_ "SPN" SG_ 2618644212 SingleBatteryVoltage234 3334;
BA_ "SigType" SG_ 2618644212 SingleBatteryGroup233 1;
BA_ "SPN" SG_ 2618644212 SingleBatteryGroup233 3333;
BA_ "SigType" SG_ 2618644212 SingleBatteryVoltage233 1;
BA_ "SPN" SG_ 2618644212 SingleBatteryVoltage233 3333;
BA_ "SigType" SG_ 2618644212 SingleBatteryGroup232 1;
BA_ "SPN" SG_ 2618644212 SingleBatteryGroup232 3332;
BA_ "SigType" SG_ 2618644212 SingleBatteryVoltage232 1;
BA_ "SPN" SG_ 2618644212 SingleBatteryVoltage232 3332;
BA_ "SigType" SG_ 2618644212 SingleBatteryGroup231 1;
BA_ "SPN" SG_ 2618644212 SingleBatteryGroup231 3331;
BA_ "SigType" SG_ 2618644212 SingleBatteryVoltage231 1;
BA_ "SPN" SG_ 2618644212 SingleBatteryVoltage231 3331;
BA_ "SigType" SG_ 2618644212 SingleBatteryGroup230 1;
BA_ "SPN" SG_ 2618644212 SingleBatteryGroup230 3330;
BA_ "SigType" SG_ 2618644212 SingleBatteryVoltage230 1;
BA_ "SPN" SG_ 2618644212 SingleBatteryVoltage230 3330;
BA_ "SigType" SG_ 2618644212 SingleBatteryGroup229 1;
BA_ "SPN" SG_ 2618644212 SingleBatteryGroup229 3329;
BA_ "SigType" SG_ 2618644212 SingleBatteryVoltage229 1;
BA_ "SPN" SG_ 2618644212 SingleBatteryVoltage229 3329;
BA_ "SigType" SG_ 2618644212 SingleBatteryGroup228 1;
BA_ "SPN" SG_ 2618644212 SingleBatteryGroup228 3328;
BA_ "SigType" SG_ 2618644212 SingleBatteryVoltage228 1;
BA_ "SPN" SG_ 2618644212 SingleBatteryVoltage228 3328;
BA_ "SigType" SG_ 2618644212 SingleBatteryGroup227 1;
BA_ "SPN" SG_ 2618644212 SingleBatteryGroup227 3327;
BA_ "SigType" SG_ 2618644212 SingleBatteryVoltage227 1;
BA_ "SPN" SG_ 2618644212 SingleBatteryVoltage227 3327;
BA_ "SigType" SG_ 2618644212 SingleBatteryGroup226 1;
BA_ "SPN" SG_ 2618644212 SingleBatteryGroup226 3326;
BA_ "SigType" SG_ 2618644212 SingleBatteryVoltage226 1;
BA_ "SPN" SG_ 2618644212 SingleBatteryVoltage226 3326;
BA_ "SigType" SG_ 2618644212 SingleBatteryGroup225 1;
BA_ "SPN" SG_ 2618644212 SingleBatteryGroup225 3325;
BA_ "SigType" SG_ 2618644212 SingleBatteryVoltage225 1;
BA_ "SPN" SG_ 2618644212 SingleBatteryVoltage225 3325;
BA_ "SigType" SG_ 2618644212 SingleBatteryGroup224 1;
BA_ "SPN" SG_ 2618644212 SingleBatteryGroup224 3324;
BA_ "SigType" SG_ 2618644212 SingleBatteryVoltage224 1;
BA_ "SPN" SG_ 2618644212 SingleBatteryVoltage224 3324;
BA_ "SigType" SG_ 2618644212 SingleBatteryGroup223 1;
BA_ "SPN" SG_ 2618644212 SingleBatteryGroup223 3323;
BA_ "SigType" SG_ 2618644212 SingleBatteryVoltage223 1;
BA_ "SPN" SG_ 2618644212 SingleBatteryVoltage223 3323;
BA_ "SigType" SG_ 2618644212 SingleBatteryGroup222 1;
BA_ "SPN" SG_ 2618644212 SingleBatteryGroup222 3322;
BA_ "SigType" SG_ 2618644212 SingleBatteryVoltage222 1;
BA_ "SPN" SG_ 2618644212 SingleBatteryVoltage222 3322;
BA_ "SigType" SG_ 2618644212 SingleBatteryGroup221 1;
BA_ "SPN" SG_ 2618644212 SingleBatteryGroup221 3321;
BA_ "SigType" SG_ 2618644212 SingleBatteryVoltage221 1;
BA_ "SPN" SG_ 2618644212 SingleBatteryVoltage221 3321;
BA_ "SigType" SG_ 2618644212 SingleBatteryGroup220 1;
BA_ "SPN" SG_ 2618644212 SingleBatteryGroup220 3320;
BA_ "SigType" SG_ 2618644212 SingleBatteryVoltage220 1;
BA_ "SPN" SG_ 2618644212 SingleBatteryVoltage220 3320;
BA_ "SigType" SG_ 2618644212 SingleBatteryGroup219 1;
BA_ "SPN" SG_ 2618644212 SingleBatteryGroup219 3319;
BA_ "SigType" SG_ 2618644212 SingleBatteryVoltage219 1;
BA_ "SPN" SG_ 2618644212 SingleBatteryVoltage219 3319;
BA_ "SigType" SG_ 2618644212 SingleBatteryGroup218 1;
BA_ "SPN" SG_ 2618644212 SingleBatteryGroup218 3318;
BA_ "SigType" SG_ 2618644212 SingleBatteryVoltage218 1;
BA_ "SPN" SG_ 2618644212 SingleBatteryVoltage218 3318;
BA_ "SigType" SG_ 2618644212 SingleBatteryGroup217 1;
BA_ "SPN" SG_ 2618644212 SingleBatteryGroup217 3317;
BA_ "SigType" SG_ 2618644212 SingleBatteryVoltage217 1;
BA_ "SPN" SG_ 2618644212 SingleBatteryVoltage217 3317;
BA_ "SigType" SG_ 2618644212 SingleBatteryGroup216 1;
BA_ "SPN" SG_ 2618644212 SingleBatteryGroup216 3316;
BA_ "SigType" SG_ 2618644212 SingleBatteryVoltage216 1;
BA_ "SPN" SG_ 2618644212 SingleBatteryVoltage216 3316;
BA_ "SigType" SG_ 2618644212 SingleBatteryGroup215 1;
BA_ "SPN" SG_ 2618644212 SingleBatteryGroup215 3315;
BA_ "SigType" SG_ 2618644212 SingleBatteryVoltage215 1;
BA_ "SPN" SG_ 2618644212 SingleBatteryVoltage215 3315;
BA_ "SigType" SG_ 2618644212 SingleBatteryGroup214 1;
BA_ "SPN" SG_ 2618644212 SingleBatteryGroup214 3314;
BA_ "SigType" SG_ 2618644212 SingleBatteryVoltage214 1;
BA_ "SPN" SG_ 2618644212 SingleBatteryVoltage214 3314;
BA_ "SigType" SG_ 2618644212 SingleBatteryGroup213 1;
BA_ "SPN" SG_ 2618644212 SingleBatteryGroup213 3313;
BA_ "SigType" SG_ 2618644212 SingleBatteryVoltage213 1;
BA_ "SPN" SG_ 2618644212 SingleBatteryVoltage213 3313;
BA_ "SigType" SG_ 2618644212 SingleBatteryGroup212 1;
BA_ "SPN" SG_ 2618644212 SingleBatteryGroup212 3312;
BA_ "SigType" SG_ 2618644212 SingleBatteryVoltage212 1;
BA_ "SPN" SG_ 2618644212 SingleBatteryVoltage212 3312;
BA_ "SigType" SG_ 2618644212 SingleBatteryGroup211 1;
BA_ "SPN" SG_ 2618644212 SingleBatteryGroup211 3311;
BA_ "SigType" SG_ 2618644212 SingleBatteryVoltage211 1;
BA_ "SPN" SG_ 2618644212 SingleBatteryVoltage211 3311;
BA_ "SigType" SG_ 2618644212 SingleBatteryGroup210 1;
BA_ "SPN" SG_ 2618644212 SingleBatteryGroup210 3310;
BA_ "SigType" SG_ 2618644212 SingleBatteryVoltage210 1;
BA_ "SPN" SG_ 2618644212 SingleBatteryVoltage210 3310;
BA_ "SigType" SG_ 2618644212 SingleBatteryGroup209 1;
BA_ "SPN" SG_ 2618644212 SingleBatteryGroup209 3309;
BA_ "SigType" SG_ 2618644212 SingleBatteryVoltage209 1;
BA_ "SPN" SG_ 2618644212 SingleBatteryVoltage209 3309;
BA_ "SigType" SG_ 2618644212 SingleBatteryGroup208 1;
BA_ "SPN" SG_ 2618644212 SingleBatteryGroup208 3308;
BA_ "SigType" SG_ 2618644212 SingleBatteryVoltage208 1;
BA_ "SPN" SG_ 2618644212 SingleBatteryVoltage208 3308;
BA_ "SigType" SG_ 2618644212 SingleBatteryGroup207 1;
BA_ "SPN" SG_ 2618644212 SingleBatteryGroup207 3307;
BA_ "SigType" SG_ 2618644212 SingleBatteryVoltage207 1;
BA_ "SPN" SG_ 2618644212 SingleBatteryVoltage207 3307;
BA_ "SigType" SG_ 2618644212 SingleBatteryGroup206 1;
BA_ "SPN" SG_ 2618644212 SingleBatteryGroup206 3306;
BA_ "SigType" SG_ 2618644212 SingleBatteryVoltage206 1;
BA_ "SPN" SG_ 2618644212 SingleBatteryVoltage206 3306;
BA_ "SigType" SG_ 2618644212 SingleBatteryGroup205 1;
BA_ "SPN" SG_ 2618644212 SingleBatteryGroup205 3305;
BA_ "SigType" SG_ 2618644212 SingleBatteryVoltage205 1;
BA_ "SPN" SG_ 2618644212 SingleBatteryVoltage205 3305;
BA_ "SigType" SG_ 2618644212 SingleBatteryGroup204 1;
BA_ "SPN" SG_ 2618644212 SingleBatteryGroup204 3304;
BA_ "SigType" SG_ 2618644212 SingleBatteryVoltage204 1;
BA_ "SPN" SG_ 2618644212 SingleBatteryVoltage204 3304;
BA_ "SigType" SG_ 2618644212 SingleBatteryGroup203 1;
BA_ "SPN" SG_ 2618644212 SingleBatteryGroup203 3303;
BA_ "SigType" SG_ 2618644212 SingleBatteryVoltage203 1;
BA_ "SPN" SG_ 2618644212 SingleBatteryVoltage203 3303;
BA_ "SigType" SG_ 2618644212 SingleBatteryGroup202 1;
BA_ "SPN" SG_ 2618644212 SingleBatteryGroup202 3302;
BA_ "SigType" SG_ 2618644212 SingleBatteryVoltage202 1;
BA_ "SPN" SG_ 2618644212 SingleBatteryVoltage202 3302;
BA_ "SigType" SG_ 2618644212 SingleBatteryGroup201 1;
BA_ "SPN" SG_ 2618644212 SingleBatteryGroup201 3301;
BA_ "SigType" SG_ 2618644212 SingleBatteryVoltage201 1;
BA_ "SPN" SG_ 2618644212 SingleBatteryVoltage201 3301;
BA_ "SigType" SG_ 2618644212 SingleBatteryGroup200 1;
BA_ "SPN" SG_ 2618644212 SingleBatteryGroup200 3300;
BA_ "SigType" SG_ 2618644212 SingleBatteryVoltage200 1;
BA_ "SPN" SG_ 2618644212 SingleBatteryVoltage200 3300;
BA_ "SigType" SG_ 2618644212 SingleBatteryGroup199 1;
BA_ "SPN" SG_ 2618644212 SingleBatteryGroup199 3299;
BA_ "SigType" SG_ 2618644212 SingleBatteryVoltage199 1;
BA_ "SPN" SG_ 2618644212 SingleBatteryVoltage199 3299;
BA_ "SigType" SG_ 2618644212 SingleBatteryGroup198 1;
BA_ "SPN" SG_ 2618644212 SingleBatteryGroup198 3298;
BA_ "SigType" SG_ 2618644212 SingleBatteryVoltage198 1;
BA_ "SPN" SG_ 2618644212 SingleBatteryVoltage198 3298;
BA_ "SigType" SG_ 2618644212 SingleBatteryGroup197 1;
BA_ "SPN" SG_ 2618644212 SingleBatteryGroup197 3297;
BA_ "SigType" SG_ 2618644212 SingleBatteryVoltage197 1;
BA_ "SPN" SG_ 2618644212 SingleBatteryVoltage197 3297;
BA_ "SigType" SG_ 2618644212 SingleBatteryGroup196 1;
BA_ "SPN" SG_ 2618644212 SingleBatteryGroup196 3296;
BA_ "SigType" SG_ 2618644212 SingleBatteryVoltage196 1;
BA_ "SPN" SG_ 2618644212 SingleBatteryVoltage196 3296;
BA_ "SigType" SG_ 2618644212 SingleBatteryGroup195 1;
BA_ "SPN" SG_ 2618644212 SingleBatteryGroup195 3295;
BA_ "SigType" SG_ 2618644212 SingleBatteryVoltage195 1;
BA_ "SPN" SG_ 2618644212 SingleBatteryVoltage195 3295;
BA_ "SigType" SG_ 2618644212 SingleBatteryGroup194 1;
BA_ "SPN" SG_ 2618644212 SingleBatteryGroup194 3294;
BA_ "SigType" SG_ 2618644212 SingleBatteryVoltage194 1;
BA_ "SPN" SG_ 2618644212 SingleBatteryVoltage194 3294;
BA_ "SigType" SG_ 2618644212 SingleBatteryGroup193 1;
BA_ "SPN" SG_ 2618644212 SingleBatteryGroup193 3293;
BA_ "SigType" SG_ 2618644212 SingleBatteryVoltage193 1;
BA_ "SPN" SG_ 2618644212 SingleBatteryVoltage193 3293;
BA_ "SigType" SG_ 2618644212 SingleBatteryGroup192 1;
BA_ "SPN" SG_ 2618644212 SingleBatteryGroup192 3292;
BA_ "SigType" SG_ 2618644212 SingleBatteryVoltage192 1;
BA_ "SPN" SG_ 2618644212 SingleBatteryVoltage192 3292;
BA_ "SigType" SG_ 2618644212 SingleBatteryGroup191 1;
BA_ "SPN" SG_ 2618644212 SingleBatteryGroup191 3291;
BA_ "SigType" SG_ 2618644212 SingleBatteryVoltage191 1;
BA_ "SPN" SG_ 2618644212 SingleBatteryVoltage191 3291;
BA_ "SigType" SG_ 2618644212 SingleBatteryGroup190 1;
BA_ "SPN" SG_ 2618644212 SingleBatteryGroup190 3290;
BA_ "SigType" SG_ 2618644212 SingleBatteryVoltage190 1;
BA_ "SPN" SG_ 2618644212 SingleBatteryVoltage190 3290;
BA_ "SigType" SG_ 2618644212 SingleBatteryGroup189 1;
BA_ "SPN" SG_ 2618644212 SingleBatteryGroup189 3289;
BA_ "SigType" SG_ 2618644212 SingleBatteryVoltage189 1;
BA_ "SPN" SG_ 2618644212 SingleBatteryVoltage189 3289;
BA_ "SigType" SG_ 2618644212 SingleBatteryGroup188 1;
BA_ "SPN" SG_ 2618644212 SingleBatteryGroup188 3288;
BA_ "SigType" SG_ 2618644212 SingleBatteryVoltage188 1;
BA_ "SPN" SG_ 2618644212 SingleBatteryVoltage188 3288;
BA_ "SigType" SG_ 2618644212 SingleBatteryGroup187 1;
BA_ "SPN" SG_ 2618644212 SingleBatteryGroup187 3287;
BA_ "SigType" SG_ 2618644212 SingleBatteryVoltage187 1;
BA_ "SPN" SG_ 2618644212 SingleBatteryVoltage187 3287;
BA_ "SigType" SG_ 2618644212 SingleBatteryGroup186 1;
BA_ "SPN" SG_ 2618644212 SingleBatteryGroup186 3286;
BA_ "SigType" SG_ 2618644212 SingleBatteryVoltage186 1;
BA_ "SPN" SG_ 2618644212 SingleBatteryVoltage186 3286;
BA_ "SigType" SG_ 2618644212 SingleBatteryGroup185 1;
BA_ "SPN" SG_ 2618644212 SingleBatteryGroup185 3285;
BA_ "SigType" SG_ 2618644212 SingleBatteryVoltage185 1;
BA_ "SPN" SG_ 2618644212 SingleBatteryVoltage185 3285;
BA_ "SigType" SG_ 2618644212 SingleBatteryGroup184 1;
BA_ "SPN" SG_ 2618644212 SingleBatteryGroup184 3284;
BA_ "SigType" SG_ 2618644212 SingleBatteryVoltage184 1;
BA_ "SPN" SG_ 2618644212 SingleBatteryVoltage184 3284;
BA_ "SigType" SG_ 2618644212 SingleBatteryGroup183 1;
BA_ "SPN" SG_ 2618644212 SingleBatteryGroup183 3283;
BA_ "SigType" SG_ 2618644212 SingleBatteryVoltage183 1;
BA_ "SPN" SG_ 2618644212 SingleBatteryVoltage183 3283;
BA_ "SigType" SG_ 2618644212 SingleBatteryGroup182 1;
BA_ "SPN" SG_ 2618644212 SingleBatteryGroup182 3282;
BA_ "SigType" SG_ 2618644212 SingleBatteryVoltage182 1;
BA_ "SPN" SG_ 2618644212 SingleBatteryVoltage182 3282;
BA_ "SigType" SG_ 2618644212 SingleBatteryGroup181 1;
BA_ "SPN" SG_ 2618644212 SingleBatteryGroup181 3281;
BA_ "SigType" SG_ 2618644212 SingleBatteryVoltage181 1;
BA_ "SPN" SG_ 2618644212 SingleBatteryVoltage181 3281;
BA_ "SigType" SG_ 2618644212 SingleBatteryGroup180 1;
BA_ "SPN" SG_ 2618644212 SingleBatteryGroup180 3280;
BA_ "SigType" SG_ 2618644212 SingleBatteryVoltage180 1;
BA_ "SPN" SG_ 2618644212 SingleBatteryVoltage180 3280;
BA_ "SigType" SG_ 2618644212 SingleBatteryGroup179 1;
BA_ "SPN" SG_ 2618644212 SingleBatteryGroup179 3279;
BA_ "SigType" SG_ 2618644212 SingleBatteryVoltage179 1;
BA_ "SPN" SG_ 2618644212 SingleBatteryVoltage179 3279;
BA_ "SigType" SG_ 2618644212 SingleBatteryGroup178 1;
BA_ "SPN" SG_ 2618644212 SingleBatteryGroup178 3278;
BA_ "SigType" SG_ 2618644212 SingleBatteryVoltage178 1;
BA_ "SPN" SG_ 2618644212 SingleBatteryVoltage178 3278;
BA_ "SigType" SG_ 2618644212 SingleBatteryGroup177 1;
BA_ "SPN" SG_ 2618644212 SingleBatteryGroup177 3277;
BA_ "SigType" SG_ 2618644212 SingleBatteryVoltage177 1;
BA_ "SPN" SG_ 2618644212 SingleBatteryVoltage177 3277;
BA_ "SigType" SG_ 2618644212 SingleBatteryGroup176 1;
BA_ "SPN" SG_ 2618644212 SingleBatteryGroup176 3276;
BA_ "SigType" SG_ 2618644212 SingleBatteryVoltage176 1;
BA_ "SPN" SG_ 2618644212 SingleBatteryVoltage176 3276;
BA_ "SigType" SG_ 2618644212 SingleBatteryGroup175 1;
BA_ "SPN" SG_ 2618644212 SingleBatteryGroup175 3275;
BA_ "SigType" SG_ 2618644212 SingleBatteryVoltage175 1;
BA_ "SPN" SG_ 2618644212 SingleBatteryVoltage175 3275;
BA_ "SigType" SG_ 2618644212 SingleBatteryGroup174 1;
BA_ "SPN" SG_ 2618644212 SingleBatteryGroup174 3274;
BA_ "SigType" SG_ 2618644212 SingleBatteryVoltage174 1;
BA_ "SPN" SG_ 2618644212 SingleBatteryVoltage174 3274;
BA_ "SigType" SG_ 2618644212 SingleBatteryGroup173 1;
BA_ "SPN" SG_ 2618644212 SingleBatteryGroup173 3273;
BA_ "SigType" SG_ 2618644212 SingleBatteryVoltage173 1;
BA_ "SPN" SG_ 2618644212 SingleBatteryVoltage173 3273;
BA_ "SigType" SG_ 2618644212 SingleBatteryGroup172 1;
BA_ "SPN" SG_ 2618644212 SingleBatteryGroup172 3272;
BA_ "SigType" SG_ 2618644212 SingleBatteryVoltage172 1;
BA_ "SPN" SG_ 2618644212 SingleBatteryVoltage172 3272;
BA_ "SigType" SG_ 2618644212 SingleBatteryGroup171 1;
BA_ "SPN" SG_ 2618644212 SingleBatteryGroup171 3271;
BA_ "SigType" SG_ 2618644212 SingleBatteryVoltage171 1;
BA_ "SPN" SG_ 2618644212 SingleBatteryVoltage171 3271;
BA_ "SigType" SG_ 2618644212 SingleBatteryGroup170 1;
BA_ "SPN" SG_ 2618644212 SingleBatteryGroup170 3270;
BA_ "SigType" SG_ 2618644212 SingleBatteryVoltage170 1;
BA_ "SPN" SG_ 2618644212 SingleBatteryVoltage170 3270;
BA_ "SigType" SG_ 2618644212 SingleBatteryGroup169 1;
BA_ "SPN" SG_ 2618644212 SingleBatteryGroup169 3269;
BA_ "SigType" SG_ 2618644212 SingleBatteryVoltage169 1;
BA_ "SPN" SG_ 2618644212 SingleBatteryVoltage169 3269;
BA_ "SigType" SG_ 2618644212 SingleBatteryGroup168 1;
BA_ "SPN" SG_ 2618644212 SingleBatteryGroup168 3268;
BA_ "SigType" SG_ 2618644212 SingleBatteryVoltage168 1;
BA_ "SPN" SG_ 2618644212 SingleBatteryVoltage168 3268;
BA_ "SigType" SG_ 2618644212 SingleBatteryGroup167 1;
BA_ "SPN" SG_ 2618644212 SingleBatteryGroup167 3267;
BA_ "SigType" SG_ 2618644212 SingleBatteryVoltage167 1;
BA_ "SPN" SG_ 2618644212 SingleBatteryVoltage167 3267;
BA_ "SigType" SG_ 2618644212 SingleBatteryGroup166 1;
BA_ "SPN" SG_ 2618644212 SingleBatteryGroup166 3266;
BA_ "SigType" SG_ 2618644212 SingleBatteryVoltage166 1;
BA_ "SPN" SG_ 2618644212 SingleBatteryVoltage166 3266;
BA_ "SigType" SG_ 2618644212 SingleBatteryGroup165 1;
BA_ "SPN" SG_ 2618644212 SingleBatteryGroup165 3265;
BA_ "SigType" SG_ 2618644212 SingleBatteryVoltage165 1;
BA_ "SPN" SG_ 2618644212 SingleBatteryVoltage165 3265;
BA_ "SigType" SG_ 2618644212 SingleBatteryGroup164 1;
BA_ "SPN" SG_ 2618644212 SingleBatteryGroup164 3264;
BA_ "SigType" SG_ 2618644212 SingleBatteryVoltage164 1;
BA_ "SPN" SG_ 2618644212 SingleBatteryVoltage164 3264;
BA_ "SigType" SG_ 2618644212 SingleBatteryGroup163 1;
BA_ "SPN" SG_ 2618644212 SingleBatteryGroup163 3263;
BA_ "SigType" SG_ 2618644212 SingleBatteryVoltage163 1;
BA_ "SPN" SG_ 2618644212 SingleBatteryVoltage163 3263;
BA_ "SigType" SG_ 2618644212 SingleBatteryGroup162 1;
BA_ "SPN" SG_ 2618644212 SingleBatteryGroup162 3262;
BA_ "SigType" SG_ 2618644212 SingleBatteryVoltage162 1;
BA_ "SPN" SG_ 2618644212 SingleBatteryVoltage162 3262;
BA_ "SigType" SG_ 2618644212 SingleBatteryGroup161 1;
BA_ "SPN" SG_ 2618644212 SingleBatteryGroup161 3261;
BA_ "SigType" SG_ 2618644212 SingleBatteryVoltage161 1;
BA_ "SPN" SG_ 2618644212 SingleBatteryVoltage161 3261;
BA_ "SigType" SG_ 2618644212 SingleBatteryGroup160 1;
BA_ "SPN" SG_ 2618644212 SingleBatteryGroup160 3260;
BA_ "SigType" SG_ 2618644212 SingleBatteryVoltage160 1;
BA_ "SPN" SG_ 2618644212 SingleBatteryVoltage160 3260;
BA_ "SigType" SG_ 2618644212 SingleBatteryGroup159 1;
BA_ "SPN" SG_ 2618644212 SingleBatteryGroup159 3259;
BA_ "SigType" SG_ 2618644212 SingleBatteryVoltage159 1;
BA_ "SPN" SG_ 2618644212 SingleBatteryVoltage159 3259;
BA_ "SigType" SG_ 2618644212 SingleBatteryGroup158 1;
BA_ "SPN" SG_ 2618644212 SingleBatteryGroup158 3258;
BA_ "SigType" SG_ 2618644212 SingleBatteryVoltage158 1;
BA_ "SPN" SG_ 2618644212 SingleBatteryVoltage158 3258;
BA_ "SigType" SG_ 2618644212 SingleBatteryGroup157 1;
BA_ "SPN" SG_ 2618644212 SingleBatteryGroup157 3257;
BA_ "SigType" SG_ 2618644212 SingleBatteryVoltage157 1;
BA_ "SPN" SG_ 2618644212 SingleBatteryVoltage157 3257;
BA_ "SigType" SG_ 2618644212 SingleBatteryGroup156 1;
BA_ "SPN" SG_ 2618644212 SingleBatteryGroup156 3256;
BA_ "SigType" SG_ 2618644212 SingleBatteryVoltage156 1;
BA_ "SPN" SG_ 2618644212 SingleBatteryVoltage156 3256;
BA_ "SigType" SG_ 2618644212 SingleBatteryGroup155 1;
BA_ "SPN" SG_ 2618644212 SingleBatteryGroup155 3255;
BA_ "SigType" SG_ 2618644212 SingleBatteryVoltage155 1;
BA_ "SPN" SG_ 2618644212 SingleBatteryVoltage155 3255;
BA_ "SigType" SG_ 2618644212 SingleBatteryGroup154 1;
BA_ "SPN" SG_ 2618644212 SingleBatteryGroup154 3254;
BA_ "SigType" SG_ 2618644212 SingleBatteryVoltage154 1;
BA_ "SPN" SG_ 2618644212 SingleBatteryVoltage154 3254;
BA_ "SigType" SG_ 2618644212 SingleBatteryGroup153 1;
BA_ "SPN" SG_ 2618644212 SingleBatteryGroup153 3253;
BA_ "SigType" SG_ 2618644212 SingleBatteryVoltage153 1;
BA_ "SPN" SG_ 2618644212 SingleBatteryVoltage153 3253;
BA_ "SigType" SG_ 2618644212 SingleBatteryGroup152 1;
BA_ "SPN" SG_ 2618644212 SingleBatteryGroup152 3252;
BA_ "SigType" SG_ 2618644212 SingleBatteryVoltage152 1;
BA_ "SPN" SG_ 2618644212 SingleBatteryVoltage152 3252;
BA_ "SigType" SG_ 2618644212 SingleBatteryGroup151 1;
BA_ "SPN" SG_ 2618644212 SingleBatteryGroup151 3251;
BA_ "SigType" SG_ 2618644212 SingleBatteryVoltage151 1;
BA_ "SPN" SG_ 2618644212 SingleBatteryVoltage151 3251;
BA_ "SigType" SG_ 2618644212 SingleBatteryGroup150 1;
BA_ "SPN" SG_ 2618644212 SingleBatteryGroup150 3250;
BA_ "SigType" SG_ 2618644212 SingleBatteryVoltage150 1;
BA_ "SPN" SG_ 2618644212 SingleBatteryVoltage150 3250;
BA_ "SigType" SG_ 2618644212 SingleBatteryGroup149 1;
BA_ "SPN" SG_ 2618644212 SingleBatteryGroup149 3249;
BA_ "SigType" SG_ 2618644212 SingleBatteryVoltage149 1;
BA_ "SPN" SG_ 2618644212 SingleBatteryVoltage149 3249;
BA_ "SigType" SG_ 2618644212 SingleBatteryGroup148 1;
BA_ "SPN" SG_ 2618644212 SingleBatteryGroup148 3248;
BA_ "SigType" SG_ 2618644212 SingleBatteryVoltage148 1;
BA_ "SPN" SG_ 2618644212 SingleBatteryVoltage148 3248;
BA_ "SigType" SG_ 2618644212 SingleBatteryGroup147 1;
BA_ "SPN" SG_ 2618644212 SingleBatteryGroup147 3247;
BA_ "SigType" SG_ 2618644212 SingleBatteryVoltage147 1;
BA_ "SPN" SG_ 2618644212 SingleBatteryVoltage147 3247;
BA_ "SigType" SG_ 2618644212 SingleBatteryGroup146 1;
BA_ "SPN" SG_ 2618644212 SingleBatteryGroup146 3246;
BA_ "SigType" SG_ 2618644212 SingleBatteryVoltage146 1;
BA_ "SPN" SG_ 2618644212 SingleBatteryVoltage146 3246;
BA_ "SigType" SG_ 2618644212 SingleBatteryGroup145 1;
BA_ "SPN" SG_ 2618644212 SingleBatteryGroup145 3245;
BA_ "SigType" SG_ 2618644212 SingleBatteryVoltage145 1;
BA_ "SPN" SG_ 2618644212 SingleBatteryVoltage145 3245;
BA_ "SigType" SG_ 2618644212 SingleBatteryGroup144 1;
BA_ "SPN" SG_ 2618644212 SingleBatteryGroup144 3244;
BA_ "SigType" SG_ 2618644212 SingleBatteryVoltage144 1;
BA_ "SPN" SG_ 2618644212 SingleBatteryVoltage144 3244;
BA_ "SigType" SG_ 2618644212 SingleBatteryGroup143 1;
BA_ "SPN" SG_ 2618644212 SingleBatteryGroup143 3243;
BA_ "SigType" SG_ 2618644212 SingleBatteryVoltage143 1;
BA_ "SPN" SG_ 2618644212 SingleBatteryVoltage143 3243;
BA_ "SigType" SG_ 2618644212 SingleBatteryGroup142 1;
BA_ "SPN" SG_ 2618644212 SingleBatteryGroup142 3242;
BA_ "SigType" SG_ 2618644212 SingleBatteryVoltage142 1;
BA_ "SPN" SG_ 2618644212 SingleBatteryVoltage142 3242;
BA_ "SigType" SG_ 2618644212 SingleBatteryGroup141 1;
BA_ "SPN" SG_ 2618644212 SingleBatteryGroup141 3241;
BA_ "SigType" SG_ 2618644212 SingleBatteryVoltage141 1;
BA_ "SPN" SG_ 2618644212 SingleBatteryVoltage141 3241;
BA_ "SigType" SG_ 2618644212 SingleBatteryGroup140 1;
BA_ "SPN" SG_ 2618644212 SingleBatteryGroup140 3240;
BA_ "SigType" SG_ 2618644212 SingleBatteryVoltage140 1;
BA_ "SPN" SG_ 2618644212 SingleBatteryVoltage140 3240;
BA_ "SigType" SG_ 2618644212 SingleBatteryGroup139 1;
BA_ "SPN" SG_ 2618644212 SingleBatteryGroup139 3239;
BA_ "SigType" SG_ 2618644212 SingleBatteryVoltage139 1;
BA_ "SPN" SG_ 2618644212 SingleBatteryVoltage139 3239;
BA_ "SigType" SG_ 2618644212 SingleBatteryGroup138 1;
BA_ "SPN" SG_ 2618644212 SingleBatteryGroup138 3238;
BA_ "SigType" SG_ 2618644212 SingleBatteryVoltage138 1;
BA_ "SPN" SG_ 2618644212 SingleBatteryVoltage138 3238;
BA_ "SigType" SG_ 2618644212 SingleBatteryGroup137 1;
BA_ "SPN" SG_ 2618644212 SingleBatteryGroup137 3237;
BA_ "SigType" SG_ 2618644212 SingleBatteryVoltage137 1;
BA_ "SPN" SG_ 2618644212 SingleBatteryVoltage137 3237;
BA_ "SigType" SG_ 2618644212 SingleBatteryGroup136 1;
BA_ "SPN" SG_ 2618644212 SingleBatteryGroup136 3236;
BA_ "SigType" SG_ 2618644212 SingleBatteryVoltage136 1;
BA_ "SPN" SG_ 2618644212 SingleBatteryVoltage136 3236;
BA_ "SigType" SG_ 2618644212 SingleBatteryGroup135 1;
BA_ "SPN" SG_ 2618644212 SingleBatteryGroup135 3235;
BA_ "SigType" SG_ 2618644212 SingleBatteryVoltage135 1;
BA_ "SPN" SG_ 2618644212 SingleBatteryVoltage135 3235;
BA_ "SigType" SG_ 2618644212 SingleBatteryGroup134 1;
BA_ "SPN" SG_ 2618644212 SingleBatteryGroup134 3234;
BA_ "SigType" SG_ 2618644212 SingleBatteryVoltage134 1;
BA_ "SPN" SG_ 2618644212 SingleBatteryVoltage134 3234;
BA_ "SigType" SG_ 2618644212 SingleBatteryGroup133 1;
BA_ "SPN" SG_ 2618644212 SingleBatteryGroup133 3233;
BA_ "SigType" SG_ 2618644212 SingleBatteryVoltage133 1;
BA_ "SPN" SG_ 2618644212 SingleBatteryVoltage133 3233;
BA_ "SigType" SG_ 2618644212 SingleBatteryGroup132 1;
BA_ "SPN" SG_ 2618644212 SingleBatteryGroup132 3232;
BA_ "SigType" SG_ 2618644212 SingleBatteryVoltage132 1;
BA_ "SPN" SG_ 2618644212 SingleBatteryVoltage132 3232;
BA_ "SigType" SG_ 2618644212 SingleBatteryGroup131 1;
BA_ "SPN" SG_ 2618644212 SingleBatteryGroup131 3231;
BA_ "SigType" SG_ 2618644212 SingleBatteryVoltage131 1;
BA_ "SPN" SG_ 2618644212 SingleBatteryVoltage131 3231;
BA_ "SigType" SG_ 2618644212 SingleBatteryGroup130 1;
BA_ "SPN" SG_ 2618644212 SingleBatteryGroup130 3230;
BA_ "SigType" SG_ 2618644212 SingleBatteryVoltage130 1;
BA_ "SPN" SG_ 2618644212 SingleBatteryVoltage130 3230;
BA_ "SigType" SG_ 2618644212 SingleBatteryGroup129 1;
BA_ "SPN" SG_ 2618644212 SingleBatteryGroup129 3229;
BA_ "SigType" SG_ 2618644212 SingleBatteryVoltage129 1;
BA_ "SPN" SG_ 2618644212 SingleBatteryVoltage129 3229;
BA_ "SigType" SG_ 2618644212 SingleBatteryGroup128 1;
BA_ "SPN" SG_ 2618644212 SingleBatteryGroup128 3228;
BA_ "SigType" SG_ 2618644212 SingleBatteryVoltage128 1;
BA_ "SPN" SG_ 2618644212 SingleBatteryVoltage128 3228;
BA_ "SigType" SG_ 2618644212 SingleBatteryGroup127 1;
BA_ "SPN" SG_ 2618644212 SingleBatteryGroup127 3227;
BA_ "SigType" SG_ 2618644212 SingleBatteryVoltage127 1;
BA_ "SPN" SG_ 2618644212 SingleBatteryVoltage127 3227;
BA_ "SigType" SG_ 2618644212 SingleBatteryGroup126 1;
BA_ "SPN" SG_ 2618644212 SingleBatteryGroup126 3226;
BA_ "SigType" SG_ 2618644212 SingleBatteryVoltage126 1;
BA_ "SPN" SG_ 2618644212 SingleBatteryVoltage126 3226;
BA_ "SigType" SG_ 2618644212 SingleBatteryGroup125 1;
BA_ "SPN" SG_ 2618644212 SingleBatteryGroup125 3225;
BA_ "SigType" SG_ 2618644212 SingleBatteryVoltage125 1;
BA_ "SPN" SG_ 2618644212 SingleBatteryVoltage125 3225;
BA_ "SigType" SG_ 2618644212 SingleBatteryGroup124 1;
BA_ "SPN" SG_ 2618644212 SingleBatteryGroup124 3224;
BA_ "SigType" SG_ 2618644212 SingleBatteryVoltage124 1;
BA_ "SPN" SG_ 2618644212 SingleBatteryVoltage124 3224;
BA_ "SigType" SG_ 2618644212 SingleBatteryGroup123 1;
BA_ "SPN" SG_ 2618644212 SingleBatteryGroup123 3223;
BA_ "SigType" SG_ 2618644212 SingleBatteryVoltage123 1;
BA_ "SPN" SG_ 2618644212 SingleBatteryVoltage123 3223;
BA_ "SigType" SG_ 2618644212 SingleBatteryGroup122 1;
BA_ "SPN" SG_ 2618644212 SingleBatteryGroup122 3222;
BA_ "SigType" SG_ 2618644212 SingleBatteryVoltage122 1;
BA_ "SPN" SG_ 2618644212 SingleBatteryVoltage122 3222;
BA_ "SigType" SG_ 2618644212 SingleBatteryGroup121 1;
BA_ "SPN" SG_ 2618644212 SingleBatteryGroup121 3221;
BA_ "SigType" SG_ 2618644212 SingleBatteryVoltage121 1;
BA_ "SPN" SG_ 2618644212 SingleBatteryVoltage121 3221;
BA_ "SigType" SG_ 2618644212 SingleBatteryGroup120 1;
BA_ "SPN" SG_ 2618644212 SingleBatteryGroup120 3220;
BA_ "SigType" SG_ 2618644212 SingleBatteryVoltage120 1;
BA_ "SPN" SG_ 2618644212 SingleBatteryVoltage120 3220;
BA_ "SigType" SG_ 2618644212 SingleBatteryGroup119 1;
BA_ "SPN" SG_ 2618644212 SingleBatteryGroup119 3219;
BA_ "SigType" SG_ 2618644212 SingleBatteryVoltage119 1;
BA_ "SPN" SG_ 2618644212 SingleBatteryVoltage119 3219;
BA_ "SigType" SG_ 2618644212 SingleBatteryGroup118 1;
BA_ "SPN" SG_ 2618644212 SingleBatteryGroup118 3218;
BA_ "SigType" SG_ 2618644212 SingleBatteryVoltage118 1;
BA_ "SPN" SG_ 2618644212 SingleBatteryVoltage118 3218;
BA_ "SigType" SG_ 2618644212 SingleBatteryGroup117 1;
BA_ "SPN" SG_ 2618644212 SingleBatteryGroup117 3217;
BA_ "SigType" SG_ 2618644212 SingleBatteryVoltage117 1;
BA_ "SPN" SG_ 2618644212 SingleBatteryVoltage117 3217;
BA_ "SigType" SG_ 2618644212 SingleBatteryGroup116 1;
BA_ "SPN" SG_ 2618644212 SingleBatteryGroup116 3216;
BA_ "SigType" SG_ 2618644212 SingleBatteryVoltage116 1;
BA_ "SPN" SG_ 2618644212 SingleBatteryVoltage116 3216;
BA_ "SigType" SG_ 2618644212 SingleBatteryGroup115 1;
BA_ "SPN" SG_ 2618644212 SingleBatteryGroup115 3215;
BA_ "SigType" SG_ 2618644212 SingleBatteryVoltage115 1;
BA_ "SPN" SG_ 2618644212 SingleBatteryVoltage115 3215;
BA_ "SigType" SG_ 2618644212 SingleBatteryGroup114 1;
BA_ "SPN" SG_ 2618644212 SingleBatteryGroup114 3214;
BA_ "SigType" SG_ 2618644212 SingleBatteryVoltage114 1;
BA_ "SPN" SG_ 2618644212 SingleBatteryVoltage114 3214;
BA_ "SigType" SG_ 2618644212 SingleBatteryGroup113 1;
BA_ "SPN" SG_ 2618644212 SingleBatteryGroup113 3213;
BA_ "SigType" SG_ 2618644212 SingleBatteryVoltage113 1;
BA_ "SPN" SG_ 2618644212 SingleBatteryVoltage113 3213;
BA_ "SigType" SG_ 2618644212 SingleBatteryGroup112 1;
BA_ "SPN" SG_ 2618644212 SingleBatteryGroup112 3212;
BA_ "SigType" SG_ 2618644212 SingleBatteryVoltage112 1;
BA_ "SPN" SG_ 2618644212 SingleBatteryVoltage112 3212;
BA_ "SigType" SG_ 2618644212 SingleBatteryGroup111 1;
BA_ "SPN" SG_ 2618644212 SingleBatteryGroup111 3211;
BA_ "SigType" SG_ 2618644212 SingleBatteryVoltage111 1;
BA_ "SPN" SG_ 2618644212 SingleBatteryVoltage111 3211;
BA_ "SigType" SG_ 2618644212 SingleBatteryGroup110 1;
BA_ "SPN" SG_ 2618644212 SingleBatteryGroup110 3210;
BA_ "SigType" SG_ 2618644212 SingleBatteryVoltage110 1;
BA_ "SPN" SG_ 2618644212 SingleBatteryVoltage110 3210;
BA_ "SigType" SG_ 2618644212 SingleBatteryGroup109 1;
BA_ "SPN" SG_ 2618644212 SingleBatteryGroup109 3209;
BA_ "SigType" SG_ 2618644212 SingleBatteryVoltage109 1;
BA_ "SPN" SG_ 2618644212 SingleBatteryVoltage109 3209;
BA_ "SigType" SG_ 2618644212 SingleBatteryGroup108 1;
BA_ "SPN" SG_ 2618644212 SingleBatteryGroup108 3208;
BA_ "SigType" SG_ 2618644212 SingleBatteryVoltage108 1;
BA_ "SPN" SG_ 2618644212 SingleBatteryVoltage108 3208;
BA_ "SigType" SG_ 2618644212 SingleBatteryGroup107 1;
BA_ "SPN" SG_ 2618644212 SingleBatteryGroup107 3207;
BA_ "SigType" SG_ 2618644212 SingleBatteryVoltage107 1;
BA_ "SPN" SG_ 2618644212 SingleBatteryVoltage107 3207;
BA_ "SigType" SG_ 2618644212 SingleBatteryGroup106 1;
BA_ "SPN" SG_ 2618644212 SingleBatteryGroup106 3206;
BA_ "SigType" SG_ 2618644212 SingleBatteryVoltage106 1;
BA_ "SPN" SG_ 2618644212 SingleBatteryVoltage106 3206;
BA_ "SigType" SG_ 2618644212 SingleBatteryGroup105 1;
BA_ "SPN" SG_ 2618644212 SingleBatteryGroup105 3205;
BA_ "SigType" SG_ 2618644212 SingleBatteryVoltage105 1;
BA_ "SPN" SG_ 2618644212 SingleBatteryVoltage105 3205;
BA_ "SigType" SG_ 2618644212 SingleBatteryGroup104 1;
BA_ "SPN" SG_ 2618644212 SingleBatteryGroup104 3204;
BA_ "SigType" SG_ 2618644212 SingleBatteryVoltage104 1;
BA_ "SPN" SG_ 2618644212 SingleBatteryVoltage104 3204;
BA_ "SigType" SG_ 2618644212 SingleBatteryGroup103 1;
BA_ "SPN" SG_ 2618644212 SingleBatteryGroup103 3203;
BA_ "SigType" SG_ 2618644212 SingleBatteryVoltage103 1;
BA_ "SPN" SG_ 2618644212 SingleBatteryVoltage103 3203;
BA_ "SigType" SG_ 2618644212 SingleBatteryGroup102 1;
BA_ "SPN" SG_ 2618644212 SingleBatteryGroup102 3202;
BA_ "SigType" SG_ 2618644212 SingleBatteryVoltage102 1;
BA_ "SPN" SG_ 2618644212 SingleBatteryVoltage102 3202;
BA_ "SigType" SG_ 2618644212 SingleBatteryGroup101 1;
BA_ "SPN" SG_ 2618644212 SingleBatteryGroup101 3201;
BA_ "SigType" SG_ 2618644212 SingleBatteryVoltage101 1;
BA_ "SPN" SG_ 2618644212 SingleBatteryVoltage101 3201;
BA_ "SPN" SG_ 2618644212 SingleBatteryGroup100 3200;
BA_ "SigType" SG_ 2618644212 SingleBatteryGroup100 1;
BA_ "SPN" SG_ 2618644212 SingleBatteryVoltage100 3200;
BA_ "SigType" SG_ 2618644212 SingleBatteryVoltage100 1;
BA_ "SPN" SG_ 2618644212 SingleBatteryGroup099 3199;
BA_ "SigType" SG_ 2618644212 SingleBatteryGroup099 1;
BA_ "SPN" SG_ 2618644212 SingleBatteryVoltage099 3199;
BA_ "SigType" SG_ 2618644212 SingleBatteryVoltage099 1;
BA_ "SPN" SG_ 2618644212 SingleBatteryGroup098 3198;
BA_ "SigType" SG_ 2618644212 SingleBatteryGroup098 1;
BA_ "SPN" SG_ 2618644212 SingleBatteryVoltage098 3198;
BA_ "SigType" SG_ 2618644212 SingleBatteryVoltage098 1;
BA_ "SPN" SG_ 2618644212 SingleBatteryGroup097 3197;
BA_ "SigType" SG_ 2618644212 SingleBatteryGroup097 1;
BA_ "SPN" SG_ 2618644212 SingleBatteryVoltage097 3197;
BA_ "SigType" SG_ 2618644212 SingleBatteryVoltage097 1;
BA_ "SPN" SG_ 2618644212 SingleBatteryGroup096 3196;
BA_ "SigType" SG_ 2618644212 SingleBatteryGroup096 1;
BA_ "SPN" SG_ 2618644212 SingleBatteryVoltage096 3196;
BA_ "SigType" SG_ 2618644212 SingleBatteryVoltage096 1;
BA_ "SPN" SG_ 2618644212 SingleBatteryGroup095 3195;
BA_ "SigType" SG_ 2618644212 SingleBatteryGroup095 1;
BA_ "SPN" SG_ 2618644212 SingleBatteryVoltage095 3195;
BA_ "SigType" SG_ 2618644212 SingleBatteryVoltage095 1;
BA_ "SPN" SG_ 2618644212 SingleBatteryGroup094 3194;
BA_ "SigType" SG_ 2618644212 SingleBatteryGroup094 1;
BA_ "SPN" SG_ 2618644212 SingleBatteryVoltage094 3194;
BA_ "SigType" SG_ 2618644212 SingleBatteryVoltage094 1;
BA_ "SPN" SG_ 2618644212 SingleBatteryGroup093 3193;
BA_ "SigType" SG_ 2618644212 SingleBatteryGroup093 1;
BA_ "SPN" SG_ 2618644212 SingleBatteryVoltage093 3193;
BA_ "SigType" SG_ 2618644212 SingleBatteryVoltage093 1;
BA_ "SPN" SG_ 2618644212 SingleBatteryGroup092 3192;
BA_ "SigType" SG_ 2618644212 SingleBatteryGroup092 1;
BA_ "SPN" SG_ 2618644212 SingleBatteryVoltage092 3192;
BA_ "SigType" SG_ 2618644212 SingleBatteryVoltage092 1;
BA_ "SPN" SG_ 2618644212 SingleBatteryGroup091 3191;
BA_ "SigType" SG_ 2618644212 SingleBatteryGroup091 1;
BA_ "SPN" SG_ 2618644212 SingleBatteryVoltage091 3191;
BA_ "SigType" SG_ 2618644212 SingleBatteryVoltage091 1;
BA_ "SPN" SG_ 2618644212 SingleBatteryGroup090 3190;
BA_ "SigType" SG_ 2618644212 SingleBatteryGroup090 1;
BA_ "SPN" SG_ 2618644212 SingleBatteryVoltage090 3190;
BA_ "SigType" SG_ 2618644212 SingleBatteryVoltage090 1;
BA_ "SPN" SG_ 2618644212 SingleBatteryGroup089 3189;
BA_ "SigType" SG_ 2618644212 SingleBatteryGroup089 1;
BA_ "SPN" SG_ 2618644212 SingleBatteryVoltage089 3189;
BA_ "SigType" SG_ 2618644212 SingleBatteryVoltage089 1;
BA_ "SPN" SG_ 2618644212 SingleBatteryGroup088 3188;
BA_ "SigType" SG_ 2618644212 SingleBatteryGroup088 1;
BA_ "SPN" SG_ 2618644212 SingleBatteryVoltage088 3188;
BA_ "SigType" SG_ 2618644212 SingleBatteryVoltage088 1;
BA_ "SPN" SG_ 2618644212 SingleBatteryGroup087 3187;
BA_ "SigType" SG_ 2618644212 SingleBatteryGroup087 1;
BA_ "SPN" SG_ 2618644212 SingleBatteryVoltage087 3187;
BA_ "SigType" SG_ 2618644212 SingleBatteryVoltage087 1;
BA_ "SPN" SG_ 2618644212 SingleBatteryGroup086 3186;
BA_ "SigType" SG_ 2618644212 SingleBatteryGroup086 1;
BA_ "SPN" SG_ 2618644212 SingleBatteryVoltage086 3186;
BA_ "SigType" SG_ 2618644212 SingleBatteryVoltage086 1;
BA_ "SPN" SG_ 2618644212 SingleBatteryGroup085 3185;
BA_ "SigType" SG_ 2618644212 SingleBatteryGroup085 1;
BA_ "SPN" SG_ 2618644212 SingleBatteryVoltage085 3185;
BA_ "SigType" SG_ 2618644212 SingleBatteryVoltage085 1;
BA_ "SPN" SG_ 2618644212 SingleBatteryGroup084 3184;
BA_ "SigType" SG_ 2618644212 SingleBatteryGroup084 1;
BA_ "SPN" SG_ 2618644212 SingleBatteryVoltage084 3184;
BA_ "SigType" SG_ 2618644212 SingleBatteryVoltage084 1;
BA_ "SPN" SG_ 2618644212 SingleBatteryGroup083 3183;
BA_ "SigType" SG_ 2618644212 SingleBatteryGroup083 1;
BA_ "SPN" SG_ 2618644212 SingleBatteryVoltage083 3183;
BA_ "SigType" SG_ 2618644212 SingleBatteryVoltage083 1;
BA_ "SPN" SG_ 2618644212 SingleBatteryGroup082 3182;
BA_ "SigType" SG_ 2618644212 SingleBatteryGroup082 1;
BA_ "SPN" SG_ 2618644212 SingleBatteryVoltage082 3182;
BA_ "SigType" SG_ 2618644212 SingleBatteryVoltage082 1;
BA_ "SPN" SG_ 2618644212 SingleBatteryGroup081 3181;
BA_ "SigType" SG_ 2618644212 SingleBatteryGroup081 1;
BA_ "SPN" SG_ 2618644212 SingleBatteryVoltage081 3181;
BA_ "SigType" SG_ 2618644212 SingleBatteryVoltage081 1;
BA_ "SPN" SG_ 2618644212 SingleBatteryGroup080 3180;
BA_ "SigType" SG_ 2618644212 SingleBatteryGroup080 1;
BA_ "SPN" SG_ 2618644212 SingleBatteryVoltage080 3180;
BA_ "SigType" SG_ 2618644212 SingleBatteryVoltage080 1;
BA_ "SPN" SG_ 2618644212 SingleBatteryGroup079 3179;
BA_ "SigType" SG_ 2618644212 SingleBatteryGroup079 1;
BA_ "SPN" SG_ 2618644212 SingleBatteryVoltage079 3179;
BA_ "SigType" SG_ 2618644212 SingleBatteryVoltage079 1;
BA_ "SPN" SG_ 2618644212 SingleBatteryGroup078 3178;
BA_ "SigType" SG_ 2618644212 SingleBatteryGroup078 1;
BA_ "SPN" SG_ 2618644212 SingleBatteryVoltage078 3178;
BA_ "SigType" SG_ 2618644212 SingleBatteryVoltage078 1;
BA_ "SPN" SG_ 2618644212 SingleBatteryGroup077 3177;
BA_ "SigType" SG_ 2618644212 SingleBatteryGroup077 1;
BA_ "SPN" SG_ 2618644212 SingleBatteryVoltage077 3177;
BA_ "SigType" SG_ 2618644212 SingleBatteryVoltage077 1;
BA_ "SPN" SG_ 2618644212 SingleBatteryGroup076 3176;
BA_ "SigType" SG_ 2618644212 SingleBatteryGroup076 1;
BA_ "SPN" SG_ 2618644212 SingleBatteryVoltage076 3176;
BA_ "SigType" SG_ 2618644212 SingleBatteryVoltage076 1;
BA_ "SPN" SG_ 2618644212 SingleBatteryGroup075 3175;
BA_ "SigType" SG_ 2618644212 SingleBatteryGroup075 1;
BA_ "SPN" SG_ 2618644212 SingleBatteryVoltage075 3175;
BA_ "SigType" SG_ 2618644212 SingleBatteryVoltage075 1;
BA_ "SPN" SG_ 2618644212 SingleBatteryGroup074 3174;
BA_ "SigType" SG_ 2618644212 SingleBatteryGroup074 1;
BA_ "SPN" SG_ 2618644212 SingleBatteryVoltage074 3174;
BA_ "SigType" SG_ 2618644212 SingleBatteryVoltage074 1;
BA_ "SPN" SG_ 2618644212 SingleBatteryGroup073 3173;
BA_ "SigType" SG_ 2618644212 SingleBatteryGroup073 1;
BA_ "SPN" SG_ 2618644212 SingleBatteryVoltage073 3173;
BA_ "SigType" SG_ 2618644212 SingleBatteryVoltage073 1;
BA_ "SPN" SG_ 2618644212 SingleBatteryGroup072 3172;
BA_ "SigType" SG_ 2618644212 SingleBatteryGroup072 1;
BA_ "SPN" SG_ 2618644212 SingleBatteryVoltage072 3172;
BA_ "SigType" SG_ 2618644212 SingleBatteryVoltage072 1;
BA_ "SPN" SG_ 2618644212 SingleBatteryGroup071 3171;
BA_ "SigType" SG_ 2618644212 SingleBatteryGroup071 1;
BA_ "SPN" SG_ 2618644212 SingleBatteryVoltage071 3171;
BA_ "SigType" SG_ 2618644212 SingleBatteryVoltage071 1;
BA_ "SPN" SG_ 2618644212 SingleBatteryGroup070 3170;
BA_ "SigType" SG_ 2618644212 SingleBatteryGroup070 1;
BA_ "SPN" SG_ 2618644212 SingleBatteryVoltage070 3170;
BA_ "SigType" SG_ 2618644212 SingleBatteryVoltage070 1;
BA_ "SPN" SG_ 2618644212 SingleBatteryGroup069 3169;
BA_ "SigType" SG_ 2618644212 SingleBatteryGroup069 1;
BA_ "SPN" SG_ 2618644212 SingleBatteryVoltage069 3169;
BA_ "SigType" SG_ 2618644212 SingleBatteryVoltage069 1;
BA_ "SPN" SG_ 2618644212 SingleBatteryGroup068 3168;
BA_ "SigType" SG_ 2618644212 SingleBatteryGroup068 1;
BA_ "SPN" SG_ 2618644212 SingleBatteryVoltage068 3168;
BA_ "SigType" SG_ 2618644212 SingleBatteryVoltage068 1;
BA_ "SPN" SG_ 2618644212 SingleBatteryGroup067 3167;
BA_ "SigType" SG_ 2618644212 SingleBatteryGroup067 1;
BA_ "SPN" SG_ 2618644212 SingleBatteryVoltage067 3167;
BA_ "SigType" SG_ 2618644212 SingleBatteryVoltage067 1;
BA_ "SPN" SG_ 2618644212 SingleBatteryGroup066 3166;
BA_ "SigType" SG_ 2618644212 SingleBatteryGroup066 1;
BA_ "SPN" SG_ 2618644212 SingleBatteryVoltage066 3166;
BA_ "SigType" SG_ 2618644212 SingleBatteryVoltage066 1;
BA_ "SPN" SG_ 2618644212 SingleBatteryGroup065 3165;
BA_ "SigType" SG_ 2618644212 SingleBatteryGroup065 1;
BA_ "SPN" SG_ 2618644212 SingleBatteryVoltage065 3165;
BA_ "SigType" SG_ 2618644212 SingleBatteryVoltage065 1;
BA_ "SPN" SG_ 2618644212 SingleBatteryGroup064 3164;
BA_ "SigType" SG_ 2618644212 SingleBatteryGroup064 1;
BA_ "SPN" SG_ 2618644212 SingleBatteryVoltage064 3164;
BA_ "SigType" SG_ 2618644212 SingleBatteryVoltage064 1;
BA_ "SPN" SG_ 2618644212 SingleBatteryGroup063 3163;
BA_ "SigType" SG_ 2618644212 SingleBatteryGroup063 1;
BA_ "SPN" SG_ 2618644212 SingleBatteryVoltage063 3163;
BA_ "SigType" SG_ 2618644212 SingleBatteryVoltage063 1;
BA_ "SPN" SG_ 2618644212 SingleBatteryGroup062 3162;
BA_ "SigType" SG_ 2618644212 SingleBatteryGroup062 1;
BA_ "SPN" SG_ 2618644212 SingleBatteryVoltage062 3162;
BA_ "SigType" SG_ 2618644212 SingleBatteryVoltage062 1;
BA_ "SPN" SG_ 2618644212 SingleBatteryGroup061 3161;
BA_ "SigType" SG_ 2618644212 SingleBatteryGroup061 1;
BA_ "SPN" SG_ 2618644212 SingleBatteryVoltage061 3161;
BA_ "SigType" SG_ 2618644212 SingleBatteryVoltage061 1;
BA_ "SPN" SG_ 2618644212 SingleBatteryGroup060 3160;
BA_ "SigType" SG_ 2618644212 SingleBatteryGroup060 1;
BA_ "SPN" SG_ 2618644212 SingleBatteryVoltage060 3160;
BA_ "SigType" SG_ 2618644212 SingleBatteryVoltage060 1;
BA_ "SPN" SG_ 2618644212 SingleBatteryGroup059 3159;
BA_ "SigType" SG_ 2618644212 SingleBatteryGroup059 1;
BA_ "SPN" SG_ 2618644212 SingleBatteryVoltage059 3159;
BA_ "SigType" SG_ 2618644212 SingleBatteryVoltage059 1;
BA_ "SPN" SG_ 2618644212 SingleBatteryGroup058 3158;
BA_ "SigType" SG_ 2618644212 SingleBatteryGroup058 1;
BA_ "SPN" SG_ 2618644212 SingleBatteryVoltage058 3158;
BA_ "SigType" SG_ 2618644212 SingleBatteryVoltage058 1;
BA_ "SPN" SG_ 2618644212 SingleBatteryGroup057 3157;
BA_ "SigType" SG_ 2618644212 SingleBatteryGroup057 1;
BA_ "SPN" SG_ 2618644212 SingleBatteryVoltage057 3157;
BA_ "SigType" SG_ 2618644212 SingleBatteryVoltage057 1;
BA_ "SPN" SG_ 2618644212 SingleBatteryGroup056 3156;
BA_ "SigType" SG_ 2618644212 SingleBatteryGroup056 1;
BA_ "SPN" SG_ 2618644212 SingleBatteryVoltage056 3156;
BA_ "SigType" SG_ 2618644212 SingleBatteryVoltage056 1;
BA_ "SPN" SG_ 2618644212 SingleBatteryGroup055 3155;
BA_ "SigType" SG_ 2618644212 SingleBatteryGroup055 1;
BA_ "SPN" SG_ 2618644212 SingleBatteryVoltage055 3155;
BA_ "SigType" SG_ 2618644212 SingleBatteryVoltage055 1;
BA_ "SPN" SG_ 2618644212 SingleBatteryGroup054 3154;
BA_ "SigType" SG_ 2618644212 SingleBatteryGroup054 1;
BA_ "SPN" SG_ 2618644212 SingleBatteryVoltage054 3154;
BA_ "SigType" SG_ 2618644212 SingleBatteryVoltage054 1;
BA_ "SPN" SG_ 2618644212 SingleBatteryGroup053 3153;
BA_ "SigType" SG_ 2618644212 SingleBatteryGroup053 1;
BA_ "SPN" SG_ 2618644212 SingleBatteryVoltage053 3153;
BA_ "SigType" SG_ 2618644212 SingleBatteryVoltage053 1;
BA_ "SPN" SG_ 2618644212 SingleBatteryGroup052 3152;
BA_ "SigType" SG_ 2618644212 SingleBatteryGroup052 1;
BA_ "SPN" SG_ 2618644212 SingleBatteryVoltage052 3152;
BA_ "SigType" SG_ 2618644212 SingleBatteryVoltage052 1;
BA_ "SPN" SG_ 2618644212 SingleBatteryGroup051 3151;
BA_ "SigType" SG_ 2618644212 SingleBatteryGroup051 1;
BA_ "SPN" SG_ 2618644212 SingleBatteryVoltage051 3151;
BA_ "SigType" SG_ 2618644212 SingleBatteryVoltage051 1;
BA_ "SPN" SG_ 2618644212 SingleBatteryGroup050 3150;
BA_ "SigType" SG_ 2618644212 SingleBatteryGroup050 1;
BA_ "SPN" SG_ 2618644212 SingleBatteryVoltage050 3150;
BA_ "SigType" SG_ 2618644212 SingleBatteryVoltage050 1;
BA_ "SPN" SG_ 2618644212 SingleBatteryGroup049 3149;
BA_ "SigType" SG_ 2618644212 SingleBatteryGroup049 1;
BA_ "SPN" SG_ 2618644212 SingleBatteryVoltage049 3149;
BA_ "SigType" SG_ 2618644212 SingleBatteryVoltage049 1;
BA_ "SPN" SG_ 2618644212 SingleBatteryGroup048 3148;
BA_ "SigType" SG_ 2618644212 SingleBatteryGroup048 1;
BA_ "SPN" SG_ 2618644212 SingleBatteryVoltage048 3148;
BA_ "SigType" SG_ 2618644212 SingleBatteryVoltage048 1;
BA_ "SPN" SG_ 2618644212 SingleBatteryGroup047 3147;
BA_ "SigType" SG_ 2618644212 SingleBatteryGroup047 1;
BA_ "SPN" SG_ 2618644212 SingleBatteryVoltage047 3147;
BA_ "SigType" SG_ 2618644212 SingleBatteryVoltage047 1;
BA_ "SPN" SG_ 2618644212 SingleBatteryGroup046 3146;
BA_ "SigType" SG_ 2618644212 SingleBatteryGroup046 1;
BA_ "SPN" SG_ 2618644212 SingleBatteryVoltage046 3146;
BA_ "SigType" SG_ 2618644212 SingleBatteryVoltage046 1;
BA_ "SPN" SG_ 2618644212 SingleBatteryGroup045 3145;
BA_ "SigType" SG_ 2618644212 SingleBatteryGroup045 1;
BA_ "SPN" SG_ 2618644212 SingleBatteryVoltage045 3145;
BA_ "SigType" SG_ 2618644212 SingleBatteryVoltage045 1;
BA_ "SPN" SG_ 2618644212 SingleBatteryGroup044 3144;
BA_ "SigType" SG_ 2618644212 SingleBatteryGroup044 1;
BA_ "SPN" SG_ 2618644212 SingleBatteryVoltage044 3144;
BA_ "SigType" SG_ 2618644212 SingleBatteryVoltage044 1;
BA_ "SPN" SG_ 2618644212 SingleBatteryGroup043 3143;
BA_ "SigType" SG_ 2618644212 SingleBatteryGroup043 1;
BA_ "SPN" SG_ 2618644212 SingleBatteryVoltage043 3143;
BA_ "SigType" SG_ 2618644212 SingleBatteryVoltage043 1;
BA_ "SPN" SG_ 2618644212 SingleBatteryGroup042 3142;
BA_ "SigType" SG_ 2618644212 SingleBatteryGroup042 1;
BA_ "SPN" SG_ 2618644212 SingleBatteryVoltage042 3142;
BA_ "SigType" SG_ 2618644212 SingleBatteryVoltage042 1;
BA_ "SPN" SG_ 2618644212 SingleBatteryGroup041 3141;
BA_ "SigType" SG_ 2618644212 SingleBatteryGroup041 1;
BA_ "SPN" SG_ 2618644212 SingleBatteryVoltage041 3141;
BA_ "SigType" SG_ 2618644212 SingleBatteryVoltage041 1;
BA_ "SPN" SG_ 2618644212 SingleBatteryGroup040 3140;
BA_ "SigType" SG_ 2618644212 SingleBatteryGroup040 1;
BA_ "SPN" SG_ 2618644212 SingleBatteryVoltage040 3140;
BA_ "SigType" SG_ 2618644212 SingleBatteryVoltage040 1;
BA_ "SPN" SG_ 2618644212 SingleBatteryGroup039 3139;
BA_ "SigType" SG_ 2618644212 SingleBatteryGroup039 1;
BA_ "SPN" SG_ 2618644212 SingleBatteryVoltage039 3139;
BA_ "SigType" SG_ 2618644212 SingleBatteryVoltage039 1;
BA_ "SPN" SG_ 2618644212 SingleBatteryGroup038 3138;
BA_ "SigType" SG_ 2618644212 SingleBatteryGroup038 1;
BA_ "SPN" SG_ 2618644212 SingleBatteryVoltage038 3138;
BA_ "SigType" SG_ 2618644212 SingleBatteryVoltage038 1;
BA_ "SPN" SG_ 2618644212 SingleBatteryGroup037 3137;
BA_ "SigType" SG_ 2618644212 SingleBatteryGroup037 1;
BA_ "SPN" SG_ 2618644212 SingleBatteryVoltage037 3137;
BA_ "SigType" SG_ 2618644212 SingleBatteryVoltage037 1;
BA_ "SPN" SG_ 2618644212 SingleBatteryGroup036 3136;
BA_ "SigType" SG_ 2618644212 SingleBatteryGroup036 1;
BA_ "SPN" SG_ 2618644212 SingleBatteryVoltage036 3136;
BA_ "SigType" SG_ 2618644212 SingleBatteryVoltage036 1;
BA_ "SPN" SG_ 2618644212 SingleBatteryGroup035 3135;
BA_ "SigType" SG_ 2618644212 SingleBatteryGroup035 1;
BA_ "SPN" SG_ 2618644212 SingleBatteryVoltage035 3135;
BA_ "SigType" SG_ 2618644212 SingleBatteryVoltage035 1;
BA_ "SPN" SG_ 2618644212 SingleBatteryGroup034 3134;
BA_ "SigType" SG_ 2618644212 SingleBatteryGroup034 1;
BA_ "SPN" SG_ 2618644212 SingleBatteryVoltage034 3134;
BA_ "SigType" SG_ 2618644212 SingleBatteryVoltage034 1;
BA_ "SPN" SG_ 2618644212 SingleBatteryGroup033 3133;
BA_ "SigType" SG_ 2618644212 SingleBatteryGroup033 1;
BA_ "SPN" SG_ 2618644212 SingleBatteryVoltage033 3133;
BA_ "SigType" SG_ 2618644212 SingleBatteryVoltage033 1;
BA_ "SPN" SG_ 2618644212 SingleBatteryGroup032 3132;
BA_ "SigType" SG_ 2618644212 SingleBatteryGroup032 1;
BA_ "SPN" SG_ 2618644212 SingleBatteryVoltage032 3132;
BA_ "SigType" SG_ 2618644212 SingleBatteryVoltage032 1;
BA_ "SPN" SG_ 2618644212 SingleBatteryGroup031 3131;
BA_ "SigType" SG_ 2618644212 SingleBatteryGroup031 1;
BA_ "SPN" SG_ 2618644212 SingleBatteryVoltage031 3131;
BA_ "SigType" SG_ 2618644212 SingleBatteryVoltage031 1;
BA_ "SPN" SG_ 2618644212 SingleBatteryGroup030 3130;
BA_ "SigType" SG_ 2618644212 SingleBatteryGroup030 1;
BA_ "SPN" SG_ 2618644212 SingleBatteryVoltage030 3130;
BA_ "SigType" SG_ 2618644212 SingleBatteryVoltage030 1;
BA_ "SPN" SG_ 2618644212 SingleBatteryGroup029 3129;
BA_ "SigType" SG_ 2618644212 SingleBatteryGroup029 1;
BA_ "SPN" SG_ 2618644212 SingleBatteryVoltage029 3129;
BA_ "SigType" SG_ 2618644212 SingleBatteryVoltage029 1;
BA_ "SPN" SG_ 2618644212 SingleBatteryGroup028 3128;
BA_ "SigType" SG_ 2618644212 SingleBatteryGroup028 1;
BA_ "SPN" SG_ 2618644212 SingleBatteryVoltage028 3128;
BA_ "SigType" SG_ 2618644212 SingleBatteryVoltage028 1;
BA_ "SPN" SG_ 2618644212 SingleBatteryGroup027 3127;
BA_ "SigType" SG_ 2618644212 SingleBatteryGroup027 1;
BA_ "SPN" SG_ 2618644212 SingleBatteryVoltage027 3127;
BA_ "SigType" SG_ 2618644212 SingleBatteryVoltage027 1;
BA_ "SPN" SG_ 2618644212 SingleBatteryGroup026 3126;
BA_ "SigType" SG_ 2618644212 SingleBatteryGroup026 1;
BA_ "SPN" SG_ 2618644212 SingleBatteryVoltage026 3126;
BA_ "SigType" SG_ 2618644212 SingleBatteryVoltage026 1;
BA_ "SPN" SG_ 2618644212 SingleBatteryGroup025 3125;
BA_ "SigType" SG_ 2618644212 SingleBatteryGroup025 1;
BA_ "SPN" SG_ 2618644212 SingleBatteryVoltage025 3125;
BA_ "SigType" SG_ 2618644212 SingleBatteryVoltage025 1;
BA_ "SPN" SG_ 2618644212 SingleBatteryGroup024 3124;
BA_ "SigType" SG_ 2618644212 SingleBatteryGroup024 1;
BA_ "SPN" SG_ 2618644212 SingleBatteryVoltage024 3124;
BA_ "SigType" SG_ 2618644212 SingleBatteryVoltage024 1;
BA_ "SPN" SG_ 2618644212 SingleBatteryGroup023 3123;
BA_ "SigType" SG_ 2618644212 SingleBatteryGroup023 1;
BA_ "SPN" SG_ 2618644212 SingleBatteryVoltage023 3123;
BA_ "SigType" SG_ 2618644212 SingleBatteryVoltage023 1;
BA_ "SPN" SG_ 2618644212 SingleBatteryGroup022 3122;
BA_ "SigType" SG_ 2618644212 SingleBatteryGroup022 1;
BA_ "SPN" SG_ 2618644212 SingleBatteryVoltage022 3122;
BA_ "SigType" SG_ 2618644212 SingleBatteryVoltage022 1;
BA_ "SPN" SG_ 2618644212 SingleBatteryGroup021 3121;
BA_ "SigType" SG_ 2618644212 SingleBatteryGroup021 1;
BA_ "SPN" SG_ 2618644212 SingleBatteryVoltage021 3121;
BA_ "SigType" SG_ 2618644212 SingleBatteryVoltage021 1;
BA_ "SPN" SG_ 2618644212 SingleBatteryGroup020 3120;
BA_ "SigType" SG_ 2618644212 SingleBatteryGroup020 1;
BA_ "SPN" SG_ 2618644212 SingleBatteryVoltage020 3120;
BA_ "SigType" SG_ 2618644212 SingleBatteryVoltage020 1;
BA_ "SigType" SG_ 2618644212 SingleBatteryGroup019 1;
BA_ "SPN" SG_ 2618644212 SingleBatteryGroup019 3119;
BA_ "SigType" SG_ 2618644212 SingleBatteryVoltage019 1;
BA_ "SPN" SG_ 2618644212 SingleBatteryVoltage019 3119;
BA_ "SigType" SG_ 2618644212 SingleBatteryGroup018 1;
BA_ "SPN" SG_ 2618644212 SingleBatteryGroup018 3118;
BA_ "SigType" SG_ 2618644212 SingleBatteryVoltage018 1;
BA_ "SPN" SG_ 2618644212 SingleBatteryVoltage018 3118;
BA_ "SigType" SG_ 2618644212 SingleBatteryGroup017 1;
BA_ "SPN" SG_ 2618644212 SingleBatteryGroup017 3117;
BA_ "SigType" SG_ 2618644212 SingleBatteryVoltage017 1;
BA_ "SPN" SG_ 2618644212 SingleBatteryVoltage017 3117;
BA_ "SigType" SG_ 2618644212 SingleBatteryGroup016 1;
BA_ "SPN" SG_ 2618644212 SingleBatteryGroup016 3116;
BA_ "SigType" SG_ 2618644212 SingleBatteryVoltage016 1;
BA_ "SPN" SG_ 2618644212 SingleBatteryVoltage016 3116;
BA_ "SigType" SG_ 2618644212 SingleBatteryGroup015 1;
BA_ "SPN" SG_ 2618644212 SingleBatteryGroup015 3115;
BA_ "SigType" SG_ 2618644212 SingleBatteryVoltage015 1;
BA_ "SPN" SG_ 2618644212 SingleBatteryVoltage015 3115;
BA_ "SigType" SG_ 2618644212 SingleBatteryGroup014 1;
BA_ "SPN" SG_ 2618644212 SingleBatteryGroup014 3114;
BA_ "SigType" SG_ 2618644212 SingleBatteryVoltage014 1;
BA_ "SPN" SG_ 2618644212 SingleBatteryVoltage014 3114;
BA_ "SigType" SG_ 2618644212 SingleBatteryGroup013 1;
BA_ "SPN" SG_ 2618644212 SingleBatteryGroup013 3113;
BA_ "SigType" SG_ 2618644212 SingleBatteryVoltage013 1;
BA_ "SPN" SG_ 2618644212 SingleBatteryVoltage013 3113;
BA_ "SigType" SG_ 2618644212 SingleBatteryGroup012 1;
BA_ "SPN" SG_ 2618644212 SingleBatteryGroup012 3112;
BA_ "SigType" SG_ 2618644212 SingleBatteryVoltage012 1;
BA_ "SPN" SG_ 2618644212 SingleBatteryVoltage012 3112;
BA_ "SigType" SG_ 2618644212 SingleBatteryGroup011 1;
BA_ "SPN" SG_ 2618644212 SingleBatteryGroup011 3111;
BA_ "SigType" SG_ 2618644212 SingleBatteryVoltage011 1;
BA_ "SPN" SG_ 2618644212 SingleBatteryVoltage011 3111;
BA_ "SPN" SG_ 2618644212 SingleBatteryGroup010 3110;
BA_ "SigType" SG_ 2618644212 SingleBatteryGroup010 1;
BA_ "SPN" SG_ 2618644212 SingleBatteryVoltage010 3110;
BA_ "SigType" SG_ 2618644212 SingleBatteryVoltage010 1;
BA_ "SPN" SG_ 2618644212 SingleBatteryGroup009 3109;
BA_ "SigType" SG_ 2618644212 SingleBatteryGroup009 1;
BA_ "SPN" SG_ 2618644212 SingleBatteryVoltage009 3109;
BA_ "SigType" SG_ 2618644212 SingleBatteryVoltage009 1;
BA_ "SPN" SG_ 2618644212 SingleBatteryGroup008 3108;
BA_ "SigType" SG_ 2618644212 SingleBatteryGroup008 1;
BA_ "SPN" SG_ 2618644212 SingleBatteryVoltage008 3108;
BA_ "SigType" SG_ 2618644212 SingleBatteryVoltage008 1;
BA_ "SPN" SG_ 2618644212 SingleBatteryGroup007 3107;
BA_ "SigType" SG_ 2618644212 SingleBatteryGroup007 1;
BA_ "SPN" SG_ 2618644212 SingleBatteryVoltage007 3107;
BA_ "SigType" SG_ 2618644212 SingleBatteryVoltage007 1;
BA_ "SPN" SG_ 2618644212 SingleBatteryGroup006 3106;
BA_ "SigType" SG_ 2618644212 SingleBatteryGroup006 1;
BA_ "SPN" SG_ 2618644212 SingleBatteryVoltage006 3106;
BA_ "SigType" SG_ 2618644212 SingleBatteryVoltage006 1;
BA_ "SPN" SG_ 2618644212 SingleBatteryGroup005 3105;
BA_ "SigType" SG_ 2618644212 SingleBatteryGroup005 1;
BA_ "SPN" SG_ 2618644212 SingleBatteryVoltage005 3105;
BA_ "SigType" SG_ 2618644212 SingleBatteryVoltage005 1;
BA_ "SPN" SG_ 2618644212 SingleBatteryGroup004 3104;
BA_ "SigType" SG_ 2618644212 SingleBatteryGroup004 1;
BA_ "SPN" SG_ 2618644212 SingleBatteryVoltage004 3104;
BA_ "SigType" SG_ 2618644212 SingleBatteryVoltage004 1;
BA_ "SPN" SG_ 2618644212 SingleBatteryGroup003 3103;
BA_ "SigType" SG_ 2618644212 SingleBatteryGroup003 1;
BA_ "SPN" SG_ 2618644212 SingleBatteryVoltage003 3103;
BA_ "SigType" SG_ 2618644212 SingleBatteryVoltage003 1;
BA_ "SPN" SG_ 2618644212 SingleBatteryGroup002 3102;
BA_ "SigType" SG_ 2618644212 SingleBatteryGroup002 1;
BA_ "SPN" SG_ 2618644212 SingleBatteryVoltage002 3102;
BA_ "SigType" SG_ 2618644212 SingleBatteryVoltage002 1;
BA_ "SPN" SG_ 2618644212 SingleBatteryGroup001 3101;
BA_ "SigType" SG_ 2618644212 SingleBatteryGroup001 1;
BA_ "SPN" SG_ 2618644212 SingleBatteryVoltage001 3101;
BA_ "SigType" SG_ 2618644212 SingleBatteryVoltage001 1;
BA_ "SigType" SG_ 2551404276 ChargingPermissible 4;
BA_ "SPN" SG_ 2551404276 ChargingPermissible 3096;
BA_ "GenSigStartValue" SG_ 2551404276 ChargingPermissible 1;
BA_ "SigType" SG_ 2551404276 BatteryOutputConnectorState 4;
BA_ "SPN" SG_ 2551404276 BatteryOutputConnectorState 3095;
BA_ "SigType" SG_ 2551404276 BatteryInsulationState 4;
BA_ "SPN" SG_ 2551404276 BatteryInsulationState 3094;
BA_ "SigType" SG_ 2551404276 BatteryExcessTemperature 4;
BA_ "SPN" SG_ 2551404276 BatteryExcessTemperature 3093;
BA_ "SigType" SG_ 2551404276 BatteryChargingOvercurrent 4;
BA_ "SPN" SG_ 2551404276 BatteryChargingOvercurrent 3092;
BA_ "SigType" SG_ 2551404276 StateOfCharge 4;
BA_ "SPN" SG_ 2551404276 StateOfCharge 3091;
BA_ "SigType" SG_ 2551404276 BatteryCellVoltageState 4;
BA_ "SPN" SG_ 2551404276 BatteryCellVoltageState 3090;
BA_ "GenSigStartValue" SG_ 2551404276 BatteryLowestTempSerNo 212;
BA_ "SigType" SG_ 2551404276 BatteryLowestTempSerNo 1;
BA_ "SPN" SG_ 2551404276 BatteryLowestTempSerNo 3089;
BA_ "SigType" SG_ 2551404276 BatteryLowestTemp 1;
BA_ "GenSigStartValue" SG_ 2551404276 BatteryLowestTemp 72;
BA_ "SPN" SG_ 2551404276 BatteryLowestTemp 3088;
BA_ "GenSigStartValue" SG_ 2551404276 BatteryHighestTempSerNo 122;
BA_ "SigType" SG_ 2551404276 BatteryHighestTempSerNo 1;
BA_ "SPN" SG_ 2551404276 BatteryHighestTempSerNo 3087;
BA_ "SigType" SG_ 2551404276 BatteryHighestTemp 1;
BA_ "GenSigStartValue" SG_ 2551404276 BatteryHighestTemp 75;
BA_ "SPN" SG_ 2551404276 BatteryHighestTemp 3086;
BA_ "GenSigStartValue" SG_ 2551404276 SingleBatteryHighestVoltageSerNo 110;
BA_ "SPN" SG_ 2551404276 SingleBatteryHighestVoltageSerNo 3085;
BA_ "SigType" SG_ 2551404276 SingleBatteryHighestVoltageSerNo 1;
BA_ "SigType" SG_ 2551379030 ChargingPermissible 4;
BA_ "SPN" SG_ 2551379030 ChargingPermissible 3929;
BA_ "GenSigStartValue" SG_ 2551379030 ChargingPermissible 1;
BA_ "SigType" SG_ 2551379030 CumulativeChargingTime 1;
BA_ "SPN" SG_ 2551379030 CumulativeChargingTime 3083;
BA_ "SigType" SG_ 2551379030 CurrentOutputValue 1;
BA_ "GenSigStartValue" SG_ 2551379030 CurrentOutputValue 3700;
BA_ "SPN" SG_ 2551379030 CurrentOutputValue 3082;
BA_ "SPN" SG_ 2551379030 VoltageOutputValue 3081;
BA_ "SigType" SG_ 2551379030 VoltageOutputValue 1;
BA_ "GenSigStartValue" SG_ 2551379030 VoltageOutputValue 1200;
BA_ "SPN" SG_ 2618382068 EstimatedRemainingChargingTime 3079;
BA_ "SigType" SG_ 2618382068 EstimatedRemainingChargingTime 1;
BA_ "GenSigStartValue" SG_ 2618382068 CurrentChargeState 18;
BA_ "SPN" SG_ 2618382068 CurrentChargeState 3078;
BA_ "SigType" SG_ 2618382068 CurrentChargeState 1;
BA_ "GenSigStartValue" SG_ 2618382068 GroupNrOfCellWithHighestVoltage 13;
BA_ "SPN" SG_ 2618382068 GroupNrOfCellWithHighestVoltage 3077;
BA_ "GenSigStartValue" SG_ 2618382068 HighestVoltageOfBatteryCell 1300;
BA_ "SPN" SG_ 2618382068 HighestVoltageOfBatteryCell 3077;
BA_ "SigType" SG_ 2618382068 HighestVoltageOfBatteryCell 1;
BA_ "SPN" SG_ 2618382068 MeasuredChargingCurrent 3076;
BA_ "GenSigStartValue" SG_ 2618382068 MeasuredChargingCurrent 3970;
BA_ "SigType" SG_ 2618382068 MeasuredChargingCurrent 1;
BA_ "GenSigStartValue" SG_ 2618382068 MeasuredChargingVoltage 3000;
BA_ "SPN" SG_ 2618382068 MeasuredChargingVoltage 3075;
BA_ "SigType" SG_ 2618382068 MeasuredChargingVoltage 1;
BA_ "GenSigStartValue" SG_ 2551207668 ChargingMode 2;
BA_ "SPN" SG_ 2551207668 ChargingMode 3074;
BA_ "SPN" SG_ 2551207668 CurrentDemand 3073;
BA_ "SigType" SG_ 2551207668 CurrentDemand 1;
BA_ "GenSigStartValue" SG_ 2551207668 CurrentDemand 3800;
BA_ "GenSigStartValue" SG_ 2551207668 VoltageDemand 3600;
BA_ "SPN" SG_ 2551207668 VoltageDemand 3072;
BA_ "SigType" SG_ 2551207668 VoltageDemand 1;
BA_ "SPN" SG_ 2416637014 ChargerReadyForCharging 2830;
BA_ "SPN" SG_ 2416531188 BmsReadyForCharging 2829;
BA_ "SigType" SG_ 2416531188 BmsReadyForCharging 4;
BA_ "SPN" SG_ 2550723670 MinOutputCurrent 2827;
BA_ "GenSigStartValue" SG_ 2550723670 MinOutputCurrent 3980;
BA_ "SigType" SG_ 2550723670 MinOutputCurrent 1;
BA_ "GenSigStartValue" SG_ 2550723670 MaxOutputCurrent 2500;
BA_ "SPN" SG_ 2550723670 MaxOutputCurrent 2826;
BA_ "SigType" SG_ 2550723670 MaxOutputCurrent 1;
BA_ "SPN" SG_ 2550723670 MinOutputVoltage 2825;
BA_ "SigType" SG_ 2550723670 MinOutputVoltage 1;
BA_ "GenSigStartValue" SG_ 2550723670 MinOutputVoltage 1200;
BA_ "SPN" SG_ 2550723670 MaxOutputVoltage 2824;
BA_ "SigType" SG_ 2550723670 MaxOutputVoltage 1;
BA_ "GenSigStartValue" SG_ 2550723670 MaxOutputVoltage 4500;
BA_ "GenSigStartValue" SG_ 2617661172 CurrentBatteryVoltage 3200;
BA_ "GenSigStartValue" SG_ 2617661172 StatusOfCharge 180;
BA_ "SPN" SG_ 2617661172 StatusOfCharge 2821;
BA_ "SigType" SG_ 2617661172 StatusOfCharge 1;
BA_ "SPN" SG_ 2617661172 MaxPermTemperature 2820;
BA_ "GenSigStartValue" SG_ 2617661172 MaxPermTemperature 110;
BA_ "SigType" SG_ 2617661172 MaxPermTemperature 1;
BA_ "GenSigStartValue" SG_ 2617661172 TotalMaxPermChargingVoltage 4400;
BA_ "SPN" SG_ 2617661172 TotalMaxPermChargingVoltage 2819;
BA_ "SigType" SG_ 2617661172 TotalMaxPermChargingVoltage 1;
BA_ "GenSigStartValue" SG_ 2617661172 TotalNominalEnergy 260;
BA_ "SPN" SG_ 2617661172 TotalNominalEnergy 2818;
BA_ "SigType" SG_ 2617661172 TotalNominalEnergy 1;
BA_ "SPN" SG_ 2617661172 MaxPermChargingCurrent 2817;
BA_ "GenSigStartValue" SG_ 2617661172 MaxPermChargingCurrent 2800;
BA_ "SigType" SG_ 2617661172 MaxPermChargingCurrent 1;
BA_ "GenSigStartValue" SG_ 2617661172 MaxBattCellChargingVoltage 1400;
BA_ "SPN" SG_ 2617661172 MaxBattCellChargingVoltage 2816;
BA_ "SigType" SG_ 2617661172 MaxBattCellChargingVoltage 1;
BA_ "SPN" SG_ 2617399028 BmsSoftwareVersion_Reserved 2576;
BA_ "GenSigStartValue" SG_ 2617399028 BmsSoftwareVersion_Reserved 16777215;
BA_ "SigType" SG_ 2617399028 BmsSoftwareVersion_CompileYear 1;
BA_ "SPN" SG_ 2617399028 BmsSoftwareVersion_CompileYear 2576;
BA_ "GenSigStartValue" SG_ 2617399028 BmsSoftwareVersion_CompileYear 2018;
BA_ "SigType" SG_ 2617399028 BmsSoftwareVersion_CompileMonth 4;
BA_ "SPN" SG_ 2617399028 BmsSoftwareVersion_CompileMonth 2576;
BA_ "GenSigStartValue" SG_ 2617399028 BmsSoftwareVersion_CompileMonth 8;
BA_ "SigType" SG_ 2617399028 BmsSoftwareVersion_CompileDay 1;
BA_ "SPN" SG_ 2617399028 BmsSoftwareVersion_CompileDay 2576;
BA_ "GenSigStartValue" SG_ 2617399028 BmsSoftwareVersion_CompileDay 27;
BA_ "SigType" SG_ 2617399028 BmsSoftwareVersion_Serial 1;
BA_ "SPN" SG_ 2617399028 BmsSoftwareVersion_Serial 2576;
BA_ "GenSigStartValue" SG_ 2617399028 BmsSoftwareVersion_Serial 6;
BA_ "SPN" SG_ 2617399028 BRM_Reserved1 2574;
BA_ "GenSigStartValue" SG_ 2617399028 BRM_Reserved1 255;
BA_ "SPN" SG_ 2617399028 VIN 2575;
BA_ "SigType" SG_ 2617399028 VIN 3;
BA_ "SPN" SG_ 2617399028 Property 2573;
BA_ "GenSigStartValue" SG_ 2617399028 ChargingFrequency 159;
BA_ "SPN" SG_ 2617399028 ChargingFrequency 2572;
BA_ "SigType" SG_ 2617399028 ChargingFrequency 1;
BA_ "GenSigStartValue" SG_ 2617399028 ProductionDay 21;
BA_ "SPN" SG_ 2617399028 ProductionDay 2571;
BA_ "SigType" SG_ 2617399028 ProductionDay 1;
BA_ "GenSigStartValue" SG_ 2617399028 ProductionMonth 6;
BA_ "SPN" SG_ 2617399028 ProductionMonth 2571;
BA_ "GenSigStartValue" SG_ 2617399028 ProductionYear 33;
BA_ "SPN" SG_ 2617399028 ProductionYear 2571;
BA_ "SigType" SG_ 2617399028 ProductionYear 1;
BA_ "GenSigStartValue" SG_ 2617399028 BatteryPackNumber 12345678;
BA_ "SPN" SG_ 2617399028 BatteryPackNumber 2570;
BA_ "SigType" SG_ 2617399028 ManufacturerName 3;
BA_ "SPN" SG_ 2617399028 ManufacturerName 2569;
BA_ "GenSigStartValue" SG_ 2617399028 BatterySystemVoltage 3500;
BA_ "SigType" SG_ 2617399028 BatterySystemVoltage 1;
BA_ "SPN" SG_ 2617399028 BatterySystemVoltage 2568;
BA_ "GenSigStartValue" SG_ 2617399028 BatterySystemCapacity 750;
BA_ "SigType" SG_ 2617399028 BatterySystemCapacity 1;
BA_ "SPN" SG_ 2617399028 BatterySystemCapacity 2567;
BA_ "GenSigStartValue" SG_ 2617399028 BmsVersion 22;
BA_ "SigType" SG_ 2617399028 BmsVersion 1;
BA_ "SPN" SG_ 2617399028 BmsVersion 2565;
BA_ "GenSigStartValue" SG_ 2617399028 BmsRevision 12;
BA_ "SigType" SG_ 2617399028 BmsRevision 1;
BA_ "SPN" SG_ 2617399028 BmsRevision 2565;
BA_ "GenSigStartValue" SG_ 2617399028 BatteryType 3;
BA_ "SigType" SG_ 2617399028 BatteryType 4;
BA_ "SPN" SG_ 2617399028 BatteryType 2566;
BA_ "SigType" SG_ 2550264918 ChargerLocation 3;
BA_ "SPN" SG_ 2550264918 ChargerLocation 2562;
BA_ "GenSigStartValue" SG_ 2550264918 ChargerLocation 6382179;
BA_ "SPN" SG_ 2550264918 ChargerNumber 2561;
BA_ "GenSigStartValue" SG_ 2550264918 ChargerNumber 123456;
BA_ "SPN" SG_ 2550264918 RecognitionResult 2560;
BA_ "GenSigStartValue" SG_ 2552714996 MaxChargingVoltage 4500;
BA_ "SigType" SG_ 2552714996 MaxChargingVoltage 1;
BA_ "SPN" SG_ 2552714996 MaxChargingVoltage 2601;
BA_ "SPN" SG_ 2552689750 MinorChargerVersion 2600;
BA_ "GenSigStartValue" SG_ 2552689750 MinorChargerVersion 1;
BA_ "SPN" SG_ 2552689750 MajorChargerVersion 2600;
BA_ "GenSigStartValue" SG_ 2552689750 MajorChargerVersion 1;
BA_ "SPN" SG_ 2565603070 SequenceNumber 2572;
BA_ "SPN" SG_ 2565668606 TotalNumberOfPacketsEoMA 2565;
BA_ "SPN" SG_ 2565668606 TotalMessageSizeEoMA 2564;
BA_ "SigType" SG_ 2565668606 TotalMessageSizeEoMA 1;
BA_ "SPN" SG_ 2565668606 TotalMessageSizeBAM 2567;
BA_ "SigType" SG_ 2565668606 TotalMessageSizeBAM 1;
BA_ "SPN" SG_ 2565668606 TotalNumberOfPacketsBAM 2568;
BA_ "SPN" SG_ 2565668606 ConnectionAbortReason 2570;
BA_ "SPN" SG_ 2565668606 NextPacketNumberToBeSent 2562;
BA_ "SPN" SG_ 2565668606 NumberOfPacketsThatCanBeSent 2561;
BA_ "SPN" SG_ 2565668606 PGNumber 2560;
BA_ "SigType" SG_ 2565668606 PGNumber 6;
BA_ "SPN" SG_ 2565668606 MaximumNumberOfPackets 2559;
BA_ "SPN" SG_ 2565668606 TotalNumberOfPackets 2558;
BA_ "SPN" SG_ 2565668606 TotalMessageSize 2557;
BA_ "SigType" SG_ 2565668606 TotalMessageSize 1;
BA_ "SPN" SG_ 2565668606 ControlByte 2556;
BA_ "SPN" SG_ 2565537534 ParameterGroupNumber 2540;
BA_ "SigType" SG_ 2565537534 ParameterGroupNumber 6;
BA_ "SPN" SG_ 2565406462 AddressBusy 3293;
BA_ "SPN" SG_ 2565406462 ControlByte 2541;
BA_ "SigType" SG_ 2565406462 ControlByte 6;
BA_ "SPN" SG_ 2565406462 ParameterGroupNumber 2547;
BA_ "SigType" SG_ 2565406462 ParameterGroupNumber 6;
BA_ "SPN" SG_ 2565406462 GroupFunctionValue 2542;
BA_ "SigType" SG_ 2565406462 GroupFunctionValue 1;
BA_ "SPN" SG_ 2565406462 AddressAccessDenied 3292;
BA_ "SPN" SG_ 2565406462 AddressNegativeAcknowledgement 3291;
BA_ "SPN" SG_ 2565406462 AddressAcknowledged 3290;
VAL_ 2551404276 ChargingPermissible 3 "Not Available" 2 "Untrusted" 1 "Permit" 0 "Forbid" ;
VAL_ 2551404276 BatteryOutputConnectorState 3 "Not Available" 2 "Untrusted" 1 "Abnormal" 0 "Normal" ;
VAL_ 2551404276 BatteryInsulationState 3 "Not Available" 2 "Untrusted" 1 "Abnormal" 0 "Normal" ;
VAL_ 2551404276 BatteryExcessTemperature 3 "Not Available" 2 "Untrusted" 1 "Abnormal" 0 "Normal" ;
VAL_ 2551404276 BatteryChargingOvercurrent 3 "Not Available" 2 "Untrusted" 1 "Abnormal" 0 "Normal" ;
VAL_ 2551404276 StateOfCharge 3 "Not Available" 2 "Under-Low" 1 "Over-High" 0 "Normal" ;
VAL_ 2551404276 BatteryCellVoltageState 3 "Not Available" 2 "Under-Low" 1 "Over-High" 0 "Normal" ;
VAL_ 2551379030 ChargingPermissible 3 "Not Available" 2 "Untrusted" 1 "Permit" 0 "Suspend" ;
VAL_ 2551207668 ChargingMode 2 "Constant Current" 1 "Constant Voltage" ;
VAL_ 2416637014 ChargerReadyForCharging 255 "Invalid" 170 "Ready" 0 "Not Ready" ;
VAL_ 2416531188 BmsReadyForCharging 255 "Invalid" 170 "Ready" 0 "Not Ready" ;
VAL_ 2617399028 BmsSoftwareVersion_CompileMonth 12 "December" 11 "November" 10 "October" 9 "September" 8 "August" 7 "July" 6 "June" 5 "May" 4 "April" 3 "March" 2 "February" 1 "January" ;
VAL_ 2617399028 Property 1 "Existing On Vehicle" 0 "Lease" ;
VAL_ 2617399028 ProductionMonth 12 "December" 11 "November" 10 "October" 9 "September" 8 "August" 7 "July" 6 "June" 5 "May" 4 "April" 3 "March" 2 "February" 1 "January" ;
VAL_ 2617399028 BatteryType 255 "Other Batteries" 8 "Lithium Titanate Battery" 7 "Polymer Lithium-Ion Battery" 6 "Ternary Material Battery" 5 "Cobalt Based Lithium Battery" 4 "Lithium Manganate Battery" 3 "Lithium Iron Phosphate Battery" 2 "Nickel Hydrogen Battery" 1 "Lead Acid Battery" ;
VAL_ 2550264918 RecognitionResult 170 "BMS is recognized" 0 "BMS is not recognized" ;
VAL_ 2552689750 MinorChargerVersion 65537 "V1.1" ;
VAL_ 2552689750 MajorChargerVersion 65537 "V1.1" ;
VAL_ 2565668606 ControlByte 255 "Abort" 32 "BAM" 19 "EoMA" 17 "CTS" 16 "RTS" ;
VAL_ 2565406462 ControlByte 3 "Cannot Respond" 2 "Access Denied" 1 "Negative Acknowledgment" 0 "Positive Acknowledgment" ;
